VERSION "12.2.7"

NS_ :

BS_:

BU_: ACM ADAS_Body APM ASU_Gateway BCM BCM_BPM CCU_F CCU_R DUMMY_BCM_BPM ETG LDM_L LDM_R OCS_P PSM_D SRR_RR_M SHVU_F SHVU_R TRM USS_F USS_R XGW_Body

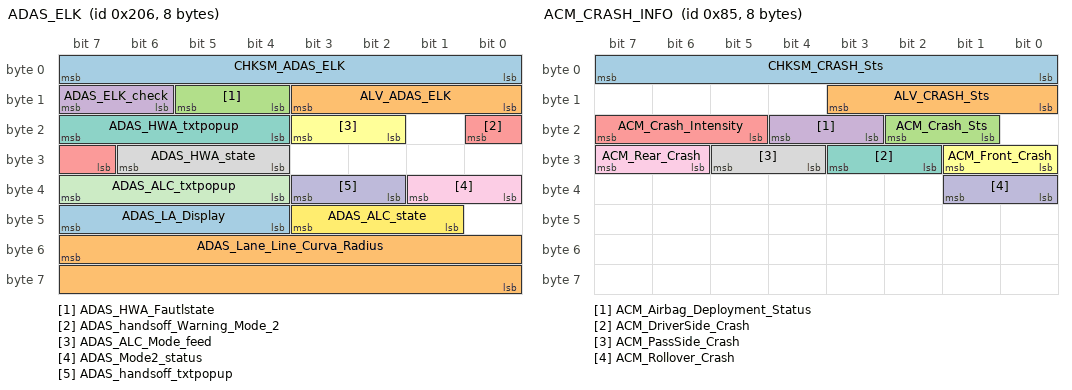
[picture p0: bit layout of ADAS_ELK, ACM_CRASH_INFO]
BO_ 518 ADAS_ELK: 8 XGW_Body
 SG_ CHKSM_ADAS_ELK : 7|8@0+ (1,0) [0|255] "" ACM
 SG_ ALV_ADAS_ELK : 11|4@0+ (1,0) [0|14] "" ACM
 SG_ ADAS_HWA_Fautlstate : 13|2@0+ (1,0) [0|3] "" Vector__XXX
 SG_ ADAS_ELK_check : 15|2@0+ (1,0) [0|3] "" ACM
 SG_ ADAS_handsoff_Warning_Mode_2 : 16|2@0+ (1,0) [0|3] "" Vector__XXX
 SG_ ADAS_ALC_Mode_feed : 19|2@0+ (1,0) [0|3] "-"  Vector__XXX
 SG_ ADAS_HWA_txtpopup : 23|4@0+ (1,0) [0|15] "" Vector__XXX
 SG_ ADAS_HWA_state : 30|3@0+ (1,0) [0|7] "" ACM
 SG_ ADAS_Mode2_status : 33|2@0+ (1,0) [0|3] "" ACM
 SG_ ADAS_handsoff_txtpopup : 35|2@0+ (1,0) [0|3] "" Vector__XXX
 SG_ ADAS_ALC_txtpopup : 39|4@0+ (1,0) [0|15] "" Vector__XXX
 SG_ ADAS_ALC_state : 43|3@0+ (1,0) [0|7] "" BCM,ACM
 SG_ ADAS_LA_Display : 47|4@0+ (1,0) [0|15] "" Vector__XXX
 SG_ ADAS_Lane_Line_Curva_Radius : 55|16@0- (1,0) [-32768|32767] "m" Vector__XXX

BO_ 133 ACM_CRASH_INFO: 8 ACM
 SG_ CHKSM_CRASH_Sts : 7|8@0+ (1,0) [0|255] ""  BCM,ETG,XGW_Body
 SG_ ALV_CRASH_Sts : 11|4@0+ (1,0) [0|14] ""  BCM,ETG,XGW_Body
 SG_ ACM_Crash_Sts : 18|2@0+ (1,0) [0|3] ""  BCM,CCU_F,ETG,XGW_Body
 SG_ ACM_Airbag_Deployment_Status : 20|2@0+ (1,0) [0|3] "-"  ETG,XGW_Body
 SG_ ACM_Crash_Intensity : 23|3@0+ (1,0) [0|7] ""  CCU_F,ETG,XGW_Body
 SG_ ACM_Front_Crash : 25|2@0+ (1,0) [0|3] "-"  BCM,ETG,XGW_Body
 SG_ ACM_DriverSide_Crash : 27|2@0+ (1,0) [0|3] ""  BCM,ETG,XGW_Body
 SG_ ACM_PassSide_Crash : 29|2@0+ (1,0) [0|3] "-"  BCM,ETG,XGW_Body
 SG_ ACM_Rear_Crash : 31|2@0+ (1,0) [0|3] "-"  BCM,ETG,XGW_Body
 SG_ ACM_Rollover_Crash : 33|2@0+ (1,0) [0|3] "-"  BCM,ETG,XGW_Body

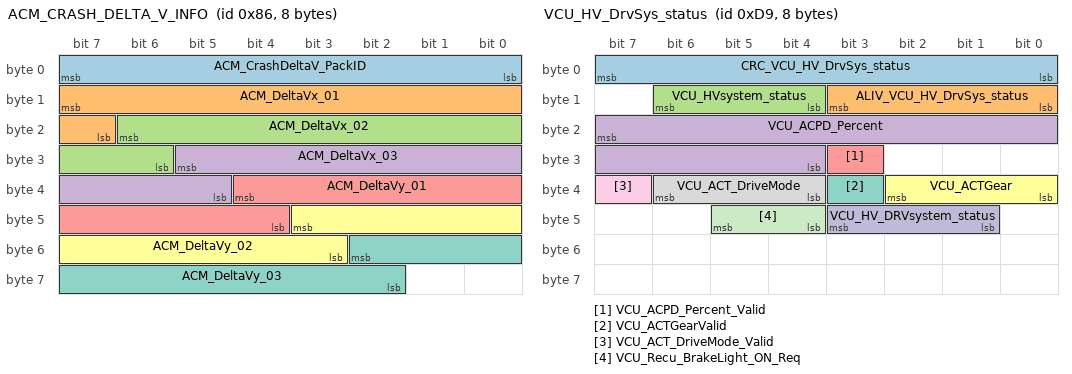
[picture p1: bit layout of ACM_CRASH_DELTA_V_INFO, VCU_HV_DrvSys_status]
BO_ 134 ACM_CRASH_DELTA_V_INFO: 8 ACM
 SG_ ACM_CrashDeltaV_PackID : 7|8@0+ (1,0) [1|9] ""  XGW_Body
 SG_ ACM_DeltaVx_01 : 15|9@0+ (1,-250) [-250|250] "Km/h"  XGW_Body
 SG_ ACM_DeltaVx_02 : 22|9@0+ (1,-250) [-250|250] "Km/h"  XGW_Body
 SG_ ACM_DeltaVx_03 : 29|9@0+ (1,-250) [-250|250] "Km/h"  XGW_Body
 SG_ ACM_DeltaVy_01 : 36|9@0+ (1,-250) [-250|250] "Km/h"  XGW_Body
 SG_ ACM_DeltaVy_02 : 43|9@0+ (1,-250) [-250|250] "Km/h"  XGW_Body
 SG_ ACM_DeltaVy_03 : 50|9@0+ (1,-250) [-250|250] "Km/h"  XGW_Body

BO_ 149 IDB_FUNCTION: 8 XGW_Body
 SG_ CHKSM_IDB_FUNCTION : 7|8@0+ (1,0) [0|255] ""  ACM,BCM
 SG_ ALV_IDB_FUNCTION : 11|4@0+ (1,0) [0|14] ""  ACM,BCM
 SG_ STAT_ABS : 13|2@0+ (1,0) [0|3] "" Vector__XXX
 SG_ ABS_Active : 15|2@0+ (1,0) [0|3] "" Vector__XXX
 SG_ AYC_Active : 17|2@0+ (1,0) [0|3] "Bit" Vector__XXX
 SG_ ASR_Active : 19|2@0+ (1,0) [0|3] "-" Vector__XXX
 SG_ STAT_DSC : 21|2@0+ (1,0) [0|3] "-"  ACM
 SG_ DSC_Active : 23|2@0+ (1,0) [0|3] "" Vector__XXX
 SG_ HBA_ActiveSignal : 25|2@0+ (1,0) [0|3] "" Vector__XXX
 SG_ ARM_ActiveSignal : 27|2@0+ (1,0) [0|3] "-" Vector__XXX
 SG_ STAT_AutoHazardBlinking : 29|2@0+ (1,0) [0|3] "Bit"  BCM
 SG_ MSR_Active : 31|2@0+ (1,0) [0|3] "-" Vector__XXX
 SG_ HSA_ActiveSignal : 33|2@0+ (1,0) [0|3] "" Vector__XXX
 SG_ EPBi_ECD_ActiveSignal : 35|2@0+ (1,0) [0|3] "" Vector__XXX
 SG_ TSM_Active : 37|2@0+ (1,0) [0|3] "-" Vector__XXX
 SG_ HAS_Available : 41|2@0+ (1,0) [0|3] "" Vector__XXX
 SG_ STAT_EBD : 43|2@0+ (1,0) [0|3] "" Vector__XXX
 SG_ EBD_Active : 45|2@0+ (1,0) [0|3] "" Vector__XXX
 SG_ ST_BRG_MSA : 55|4@0+ (1,0) [0|15] "" Vector__XXX

BO_ 217 VCU_HV_DrvSys_status: 8 XGW_Body
 SG_ CRC_VCU_HV_DrvSys_status : 7|8@0+ (1,0) [0|255] ""  ACM,BCM,LDM_L,LDM_R,SRR_RR_M,USS_F,USS_R
 SG_ ALIV_VCU_HV_DrvSys_status : 11|4@0+ (1,0) [0|14] ""  ACM,BCM,LDM_L,LDM_R,SRR_RR_M,USS_F,USS_R
 SG_ VCU_HVsystem_status : 14|3@0+ (1,0) [0|7] "-"  ACM,BCM
 SG_ VCU_ACPD_Percent : 23|12@0+ (0.0625,0) [0|100] "%"  ACM,SRR_RR_M
 SG_ VCU_ACPD_Percent_Valid : 27|1@0+ (1,0) [0|1] ""  ACM,SRR_RR_M
 SG_ VCU_ACTGear : 34|3@0+ (1,0) [0|7] ""  BCM,LDM_L,LDM_R,SRR_RR_M,USS_F,USS_R
 SG_ VCU_ACTGearValid : 35|1@0+ (1,0) [0|1] ""  BCM,LDM_L,LDM_R,SRR_RR_M
 SG_ VCU_ACT_DriveMode : 38|3@0+ (1,0) [0|7] ""  BCM
 SG_ VCU_ACT_DriveMode_Valid : 39|1@0+ (1,0) [0|1] "-"  BCM
 SG_ VCU_HV_DRVsystem_status : 43|3@0+ (1,0) [0|7] ""  BCM
 SG_ VCU_Recu_BrakeLight_ON_Req : 45|2@0+ (1,0) [0|3] "-"  BCM

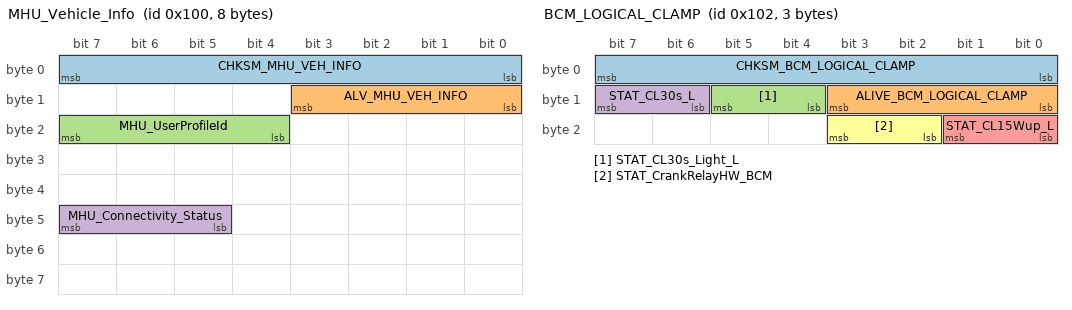
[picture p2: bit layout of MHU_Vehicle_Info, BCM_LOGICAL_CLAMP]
BO_ 256 MHU_Vehicle_Info: 8 XGW_Body
 SG_ CHKSM_MHU_VEH_INFO : 7|8@0+ (1,0) [0|255] ""  BCM
 SG_ ALV_MHU_VEH_INFO : 11|4@0+ (1,0) [0|14] ""  BCM
 SG_ MHU_UserProfileId : 23|4@0+ (1,0) [0|15] "-"  BCM
 SG_ MHU_Connectivity_Status : 47|3@0+ (1,0) [0|7] ""  BCM

BO_ 258 BCM_LOGICAL_CLAMP: 3 BCM
 SG_ CHKSM_BCM_LOGICAL_CLAMP : 7|8@0+ (1,0) [0|255] ""  ASU_Gateway,XGW_Body
 SG_ ALIVE_BCM_LOGICAL_CLAMP : 11|4@0+ (1,0) [0|14] ""  ASU_Gateway,XGW_Body
 SG_ STAT_CL30s_Light_L : 13|2@0+ (1,0) [0|3] ""  XGW_Body
 SG_ STAT_CL30s_L : 15|2@0+ (1,0) [0|3] "Bit"  ASU_Gateway,XGW_Body
 SG_ STAT_CL15Wup_L : 17|2@0+ (1,0) [0|3] "Bit"  ASU_Gateway,XGW_Body
 SG_ STAT_CrankRelayHW_BCM : 19|2@0+ (1,0) [0|3] "Bit"  XGW_Body

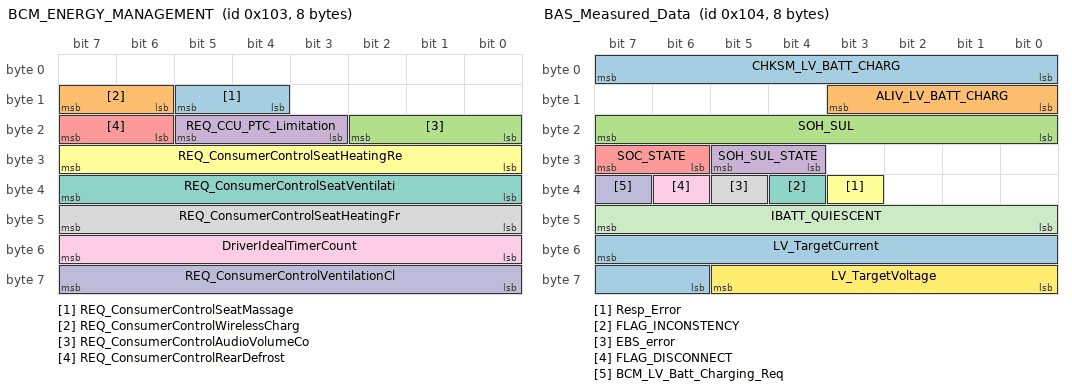
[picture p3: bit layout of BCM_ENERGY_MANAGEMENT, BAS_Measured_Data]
BO_ 259 BCM_ENERGY_MANAGEMENT: 8 BCM
 SG_ REQ_ConsumerControlSeatMassage : 13|2@0+ (1,0) [0|3] "-"  XGW_Body
 SG_ REQ_ConsumerControlWirelessCharg : 15|2@0+ (1,0) [0|3] "-"  XGW_Body
 SG_ REQ_ConsumerControlAudioVolumeCo : 18|3@0+ (1,0) [0|7] "-"  XGW_Body
 SG_ REQ_CCU_PTC_Limitation : 21|3@0+ (1,0) [0|7] ""  CCU_F,CCU_R
 SG_ REQ_ConsumerControlRearDefrost : 23|2@0+ (1,0) [0|3] "-"  CCU_F,CCU_R,XGW_Body
 SG_ REQ_ConsumerControlSeatHeatingRe : 31|8@0+ (1,0) [0|100] "%"  SHVU_F,SHVU_R,XGW_Body
 SG_ REQ_ConsumerControlSeatVentilati : 39|8@0+ (1,0) [0|100] "%"  SHVU_F,SHVU_R,XGW_Body
 SG_ REQ_ConsumerControlSeatHeatingFr : 47|8@0+ (1,0) [0|100] "%"  SHVU_F,SHVU_R,XGW_Body
 SG_ DriverIdealTimerCount : 55|8@0+ (5,0) [0|1275] "s"  XGW_Body
 SG_ REQ_ConsumerControlVentilationCl : 63|8@0+ (1,0) [0|100] "%"  CCU_F,CCU_R,SHVU_F,SHVU_R,XGW_Body

BO_ 260 BAS_Measured_Data: 8 BCM
 SG_ CHKSM_LV_BATT_CHARG : 7|8@0+ (1,0) [0|255] ""  XGW_Body
 SG_ ALIV_LV_BATT_CHARG : 11|4@0+ (1,0) [0|14] ""  XGW_Body
 SG_ SOH_SUL : 23|8@0+ (1,0) [0|100] "%"  XGW_Body
 SG_ SOH_SUL_STATE : 29|2@0+ (1,0) [0|3] ""  XGW_Body
 SG_ SOC_STATE : 31|2@0+ (1,0) [0|3] "%"  XGW_Body
 SG_ Resp_Error : 35|1@0+ (1,0) [0|1] ""  XGW_Body
 SG_ FLAG_INCONSTENCY : 36|1@0+ (1,0) [0|1] "%"  XGW_Body
 SG_ EBS_error : 37|1@0+ (1,0) [0|1] ""  XGW_Body
 SG_ FLAG_DISCONNECT : 38|1@0+ (1,0) [0|1] ""  XGW_Body
 SG_ BCM_LV_Batt_Charging_Req : 39|1@0+ (1,0) [0|1] ""  XGW_Body
 SG_ IBATT_QUIESCENT : 47|8@0+ (0.00390625,0) [0|0.984375] "" Vector__XXX
 SG_ LV_TargetVoltage : 61|6@0+ (0.112903,9) [9|16] "V"  XGW_Body
 SG_ LV_TargetCurrent : 55|10@0+ (0.25,-128) [-128|127] "A"  XGW_Body

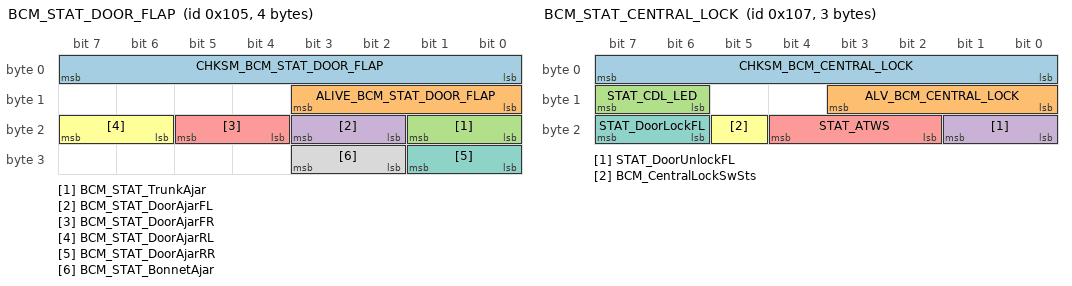
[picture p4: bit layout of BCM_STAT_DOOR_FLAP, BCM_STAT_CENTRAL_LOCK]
BO_ 261 BCM_STAT_DOOR_FLAP: 4 BCM
 SG_ CHKSM_BCM_STAT_DOOR_FLAP : 7|8@0+ (1,0) [0|255] ""  APM,ASU_Gateway,CCU_F,CCU_R,SRR_RR_M,XGW_Body
 SG_ ALIVE_BCM_STAT_DOOR_FLAP : 11|4@0+ (1,0) [0|14] ""  APM,ASU_Gateway,CCU_F,CCU_R,SRR_RR_M,XGW_Body
 SG_ BCM_STAT_TrunkAjar : 17|2@0+ (1,0) [0|3] "Bit"  APM,ASU_Gateway,CCU_R,SRR_RR_M,XGW_Body
 SG_ BCM_STAT_DoorAjarFL : 19|2@0+ (1,0) [0|3] "Bit"  APM,ASU_Gateway,CCU_F,CCU_R,SRR_RR_M,XGW_Body
 SG_ BCM_STAT_DoorAjarFR : 21|2@0+ (1,0) [0|3] "Bit"  APM,ASU_Gateway,CCU_F,CCU_R,SRR_RR_M,XGW_Body
 SG_ BCM_STAT_DoorAjarRL : 23|2@0+ (1,0) [0|3] "Bit"  APM,ASU_Gateway,CCU_F,CCU_R,SRR_RR_M,XGW_Body
 SG_ BCM_STAT_DoorAjarRR : 25|2@0+ (1,0) [0|3] "Bit"  APM,ASU_Gateway,CCU_F,CCU_R,SRR_RR_M,XGW_Body
 SG_ BCM_STAT_BonnetAjar : 27|2@0+ (1,0) [0|3] "Bit"  APM,SRR_RR_M,XGW_Body

BO_ 262 BCM_LIGHT: 8 BCM
 SG_ CHKSM_BCM_LIGHT : 7|8@0+ (1,0) [0|255] ""  APM,CCU_F,LDM_L,LDM_R,XGW_Body,SRR_RR_M
 SG_ ALIVE_BCM_LIGHT : 11|4@0+ (1,0) [0|14] ""  APM,CCU_F,LDM_L,LDM_R,XGW_Body,SRR_RR_M
 SG_ BCM_DayRunningLampSts : 13|2@0+ (1,0) [0|3] ""  LDM_L,LDM_R,XGW_Body
 SG_ BCM_ReverseLightSts : 15|2@0+ (1,0) [0|3] ""  TRM,XGW_Body
 SG_ BCM_StopLightSts : 17|2@0+ (1,0) [0|3] ""  TRM,XGW_Body
 SG_ BCM_LicensePlateLightSts : 19|2@0+ (1,0) [0|3] ""  XGW_Body
 SG_ BCM_Fr_Dimming_dome_lampSts : 21|2@0+ (1,0) [0|3] ""  XGW_Body
 SG_ BCM_Rr_Dimming_dome_lampSts : 23|2@0+ (1,0) [0|3] ""  XGW_Body
 SG_ BCM_STAT_InteriorLight : 25|2@0+ (1,0) [0|3] "Bit"  XGW_Body
 SG_ BCM_STAT_LightActivation : 28|3@0+ (1,0) [0|7] "-"  LDM_L,LDM_R,TRM,XGW_Body,SRR_RR_M
 SG_ BCM_HighBeamSts : 31|2@0+ (1,0) [0|3] ""  LDM_L,LDM_R,TRM,XGW_Body
 SG_ BCM_STAT_SwitchLightBrightness : 39|7@0+ (1,0) [0|100] "%"  XGW_Body
 SG_ BCM_LowBeamSts : 41|2@0+ (1,0) [0|3] "-"  LDM_L,LDM_R,TRM,XGW_Body
 SG_ BCM_RearFogLmpSts : 43|2@0+ (1,0) [0|3] "-"  TRM,XGW_Body
 SG_ BCM_FrntFogLmpSts : 45|2@0+ (1,0) [0|3] ""  XGW_Body
 SG_ BCM_PosLmpSts : 47|2@0+ (1,0) [0|3] "-"  LDM_L,LDM_R,TRM,XGW_Body
 SG_ BCM_BackGrdCl58Sts : 51|2@0+ (1,0) [0|3] "" Vector__XXX
 SG_ BCM_HornSts : 53|2@0+ (1,0) [0|3] ""  XGW_Body
 SG_ BCM_TurnIndicatorSts : 55|2@0+ (1,0) [0|3] ""  LDM_L,LDM_R,TRM,XGW_Body,SRR_RR_M

BO_ 263 BCM_STAT_CENTRAL_LOCK: 3 BCM
 SG_ CHKSM_BCM_CENTRAL_LOCK : 7|8@0+ (1,0) [0|255] ""  ASU_Gateway,SRR_RR_M,XGW_Body
 SG_ ALV_BCM_CENTRAL_LOCK : 11|4@0+ (1,0) [0|14] ""  ASU_Gateway,SRR_RR_M,XGW_Body
 SG_ STAT_CDL_LED : 15|2@0+ (1,0) [0|3] "-"  XGW_Body
 SG_ STAT_DoorUnlockFL : 17|2@0+ (1,0) [0|3] "Bit"  SRR_RR_M,XGW_Body
 SG_ STAT_ATWS : 20|3@0+ (1,0) [0|7] "Bit"  XGW_Body
 SG_ BCM_CentralLockSwSts : 21|1@0+ (1,0) [0|1] "" Vector__XXX
 SG_ STAT_DoorLockFL : 23|2@0+ (1,0) [0|3] "Bit"  ASU_Gateway,XGW_Body

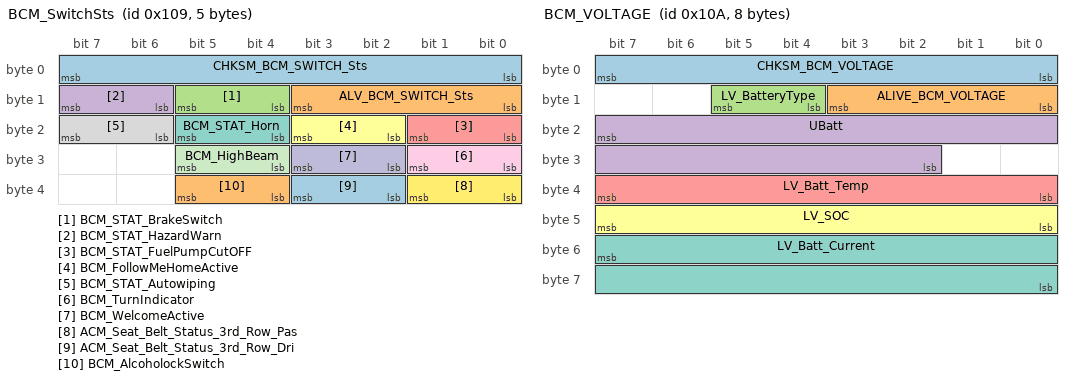
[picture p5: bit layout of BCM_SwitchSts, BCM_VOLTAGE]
BO_ 265 BCM_SwitchSts: 5 BCM
 SG_ CHKSM_BCM_SWITCH_Sts : 7|8@0+ (1,0) [0|255] ""  ACM,LDM_L,LDM_R,TRM,XGW_Body,SRR_RR_M
 SG_ ALV_BCM_SWITCH_Sts : 11|4@0+ (1,0) [0|14] ""  ACM,LDM_L,LDM_R,TRM,XGW_Body,SRR_RR_M
 SG_ BCM_STAT_BrakeSwitch : 13|2@0+ (1,0) [0|3] ""  ACM,TRM,XGW_Body,SRR_RR_M
 SG_ BCM_STAT_HazardWarn : 15|2@0+ (1,0) [0|3] "-"  LDM_L,LDM_R,TRM,XGW_Body,SRR_RR_M
 SG_ BCM_STAT_FuelPumpCutOFF : 17|2@0+ (1,0) [0|3] ""  XGW_Body
 SG_ BCM_FollowMeHomeActive : 19|2@0+ (1,0) [0|3] ""  TRM,XGW_Body
 SG_ BCM_STAT_Horn : 21|2@0+ (1,0) [0|3] "-"  XGW_Body
 SG_ BCM_STAT_Autowiping : 23|2@0+ (1,0) [0|3] ""  XGW_Body
 SG_ BCM_TurnIndicator : 25|2@0+ (1,0) [0|3] ""  LDM_L,LDM_R,TRM,XGW_Body,SRR_RR_M
 SG_ BCM_WelcomeActive : 27|2@0+ (1,0) [0|3] "-"  TRM,XGW_Body
 SG_ BCM_HighBeam : 29|2@0+ (1,0) [0|3] ""  LDM_L,LDM_R,TRM,XGW_Body,SRR_RR_M
 SG_ ACM_Seat_Belt_Status_3rd_Row_Pas : 33|2@0+ (1,0) [0|3] ""  XGW_Body
 SG_ ACM_Seat_Belt_Status_3rd_Row_Dri : 35|2@0+ (1,0) [0|3] "-"  XGW_Body
 SG_ BCM_AlcoholockSwitch : 37|2@0+ (1,0) [0|3] "" Vector__XXX

BO_ 266 BCM_VOLTAGE: 8 BCM
 SG_ CHKSM_BCM_VOLTAGE : 7|8@0+ (1,0) [0|255] ""  ACM,APM,ASU_Gateway,BCM_BPM,CCU_F,CCU_R,ETG,LDM_L,LDM_R,OCS_P,PSM_D,SHVU_F,SHVU_R,SRR_RR_M,TRM,USS_F,USS_R,XGW_Body
 SG_ ALIVE_BCM_VOLTAGE : 11|4@0+ (1,0) [0|14] ""  ACM,APM,ASU_Gateway,BCM_BPM,CCU_F,CCU_R,ETG,LDM_L,LDM_R,OCS_P,PSM_D,SHVU_F,SHVU_R,SRR_RR_M,TRM,USS_F,USS_R,XGW_Body
 SG_ LV_BatteryType : 13|2@0+ (1,0) [0|3] "Number"  XGW_Body
 SG_ UBatt : 23|14@0+ (0.0009777,3) [3|18] "V"  ACM,APM,ASU_Gateway,BCM_BPM,CCU_F,CCU_R,ETG,LDM_L,LDM_R,OCS_P,PSM_D,SHVU_F,SHVU_R,SRR_RR_M,TRM,XGW_Body,USS_F,USS_R
 SG_ LV_Batt_Temp : 39|8@0+ (1,-40) [-40|105] "Degree C"  ACM,APM,ASU_Gateway,BCM_BPM,CCU_F,CCU_R,ETG,LDM_L,LDM_R,OCS_P,PSM_D,SHVU_F,SHVU_R,TRM,XGW_Body
 SG_ LV_SOC : 47|8@0+ (1,0) [0|100] "%"  ACM,APM,ASU_Gateway,BCM_BPM,CCU_F,CCU_R,ETG,LDM_L,LDM_R,OCS_P,PSM_D,SHVU_F,SHVU_R,TRM,XGW_Body
 SG_ LV_Batt_Current : 55|16@0+ (0.03125,-1536) [-1536|511.90625] "A"  ACM,APM,ASU_Gateway,BCM_BPM,CCU_F,CCU_R,ETG,LDM_L,LDM_R,OCS_P,PSM_D,SHVU_F,SHVU_R,TRM,XGW_Body

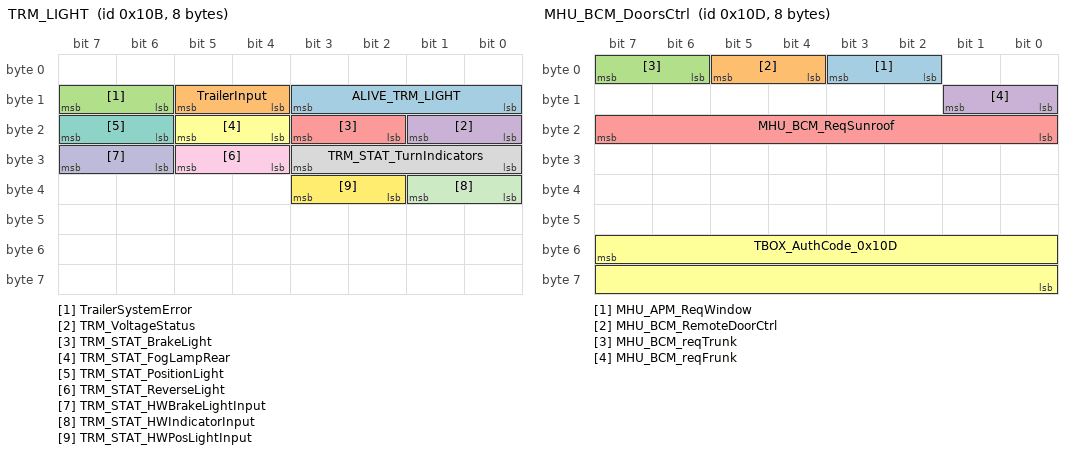
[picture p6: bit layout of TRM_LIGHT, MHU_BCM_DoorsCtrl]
BO_ 267 TRM_LIGHT: 8 TRM
 SG_ ALIVE_TRM_LIGHT : 11|4@0+ (1,0) [0|14] ""  BCM,XGW_Body
 SG_ TrailerInput : 13|2@0+ (1,0) [0|3] ""  BCM,XGW_Body
 SG_ TrailerSystemError : 15|2@0+ (1,0) [0|3] ""  BCM,XGW_Body
 SG_ TRM_VoltageStatus : 17|2@0+ (1,0) [0|3] ""  BCM,XGW_Body
 SG_ TRM_STAT_BrakeLight : 19|2@0+ (1,0) [0|3] ""  BCM,XGW_Body
 SG_ TRM_STAT_FogLampRear : 21|2@0+ (1,0) [0|3] ""  BCM,XGW_Body
 SG_ TRM_STAT_PositionLight : 23|2@0+ (1,0) [0|3] ""  BCM,XGW_Body
 SG_ TRM_STAT_TurnIndicators : 27|4@0+ (1,0) [0|15] ""  BCM,XGW_Body
 SG_ TRM_STAT_ReverseLight : 29|2@0+ (1,0) [0|3] ""  BCM,XGW_Body
 SG_ TRM_STAT_HWBrakeLightInput : 31|2@0+ (1,0) [0|3] ""  BCM,XGW_Body
 SG_ TRM_STAT_HWIndicatorInput : 33|2@0+ (1,0) [0|3] ""  BCM,XGW_Body
 SG_ TRM_STAT_HWPosLightInput : 35|2@0+ (1,0) [0|3] ""  BCM,XGW_Body

BO_ 268 BCM_RemoteCtrlSts: 8 BCM
 SG_ Checksum_0x10C : 7|8@0+ (1,0) [0|255] ""  XGW_Body
 SG_ Rolling_Counter_0x10C : 11|4@0+ (1,0) [0|14] ""  XGW_Body
 SG_ BCM_TboxAuthStatus : 23|2@0+ (1,0) [0|3] "-"  XGW_Body
 SG_ BCM_RandomNum32bit : 31|32@0+ (1,0) [0|4294967295] "-"  XGW_Body

BO_ 269 MHU_BCM_DoorsCtrl: 8 XGW_Body
 SG_ MHU_APM_ReqWindow : 3|2@0+ (1,0) [0|3] "-"  BCM
 SG_ MHU_BCM_RemoteDoorCtrl : 5|2@0+ (1,0) [0|3] "-"  BCM
 SG_ MHU_BCM_reqTrunk : 7|2@0+ (1,0) [0|3] "-"  BCM
 SG_ MHU_BCM_reqFrunk : 9|2@0+ (1,0) [0|3] "-"  BCM
 SG_ MHU_BCM_ReqSunroof : 23|8@0+ (1,0) [0|255] "%"  BCM
 SG_ TBOX_AuthCode_0x10D : 55|16@0+ (1,0) [0|65535] "-"  BCM

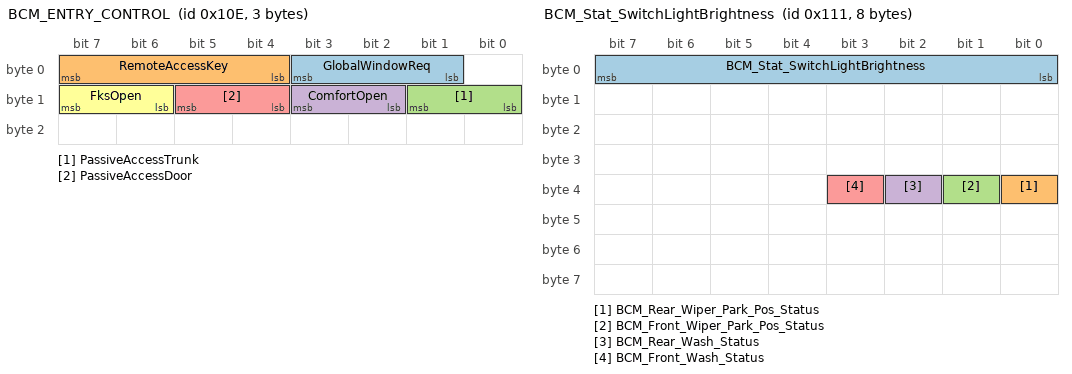
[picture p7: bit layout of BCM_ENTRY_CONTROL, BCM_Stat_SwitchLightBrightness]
BO_ 270 BCM_ENTRY_CONTROL: 3 BCM
 SG_ GlobalWindowReq : 3|3@0+ (1,0) [0|7] ""  APM
 SG_ RemoteAccessKey : 7|4@0+ (1,0) [0|15] "-"  APM,ETG,XGW_Body
 SG_ PassiveAccessTrunk : 9|2@0+ (1,0) [0|3] "-"  ETG,XGW_Body
 SG_ ComfortOpen : 11|2@0+ (1,0) [0|3] "-"  ETG,XGW_Body
 SG_ PassiveAccessDoor : 13|2@0+ (1,0) [0|3] "-"  APM,ETG,XGW_Body
 SG_ FksOpen : 15|2@0+ (1,0) [0|3] ""  ETG,XGW_Body

BO_ 271 MHU_BCM_HornLightControl: 8 XGW_Body
 SG_ MHU_SetHornOnOff : 3|2@0+ (1,0) [0|3] "-"  BCM
 SG_ MHU_SetLowBeam : 5|2@0+ (1,0) [0|3] ""  BCM
 SG_ MHU_SetHighBeam : 7|2@0+ (1,0) [0|3] ""  BCM
 SG_ TBOX_AuthCode_0x10F : 55|16@0+ (1,0) [0|65535] "-"  BCM

BO_ 273 BCM_Stat_SwitchLightBrightness: 8 BCM
 SG_ BCM_Stat_SwitchLightBrightness : 7|8@0+ (0.4,0) [0|102] ""  XGW_Body
 SG_ BCM_Rear_Wiper_Park_Pos_Status : 32|1@0+ (1,0) [0|1] "" Vector__XXX
 SG_ BCM_Front_Wiper_Park_Pos_Status : 33|1@0+ (1,0) [0|1] "" Vector__XXX
 SG_ BCM_Rear_Wash_Status : 34|1@0+ (1,0) [0|1] "" Vector__XXX
 SG_ BCM_Front_Wash_Status : 35|1@0+ (1,0) [0|1] "" Vector__XXX

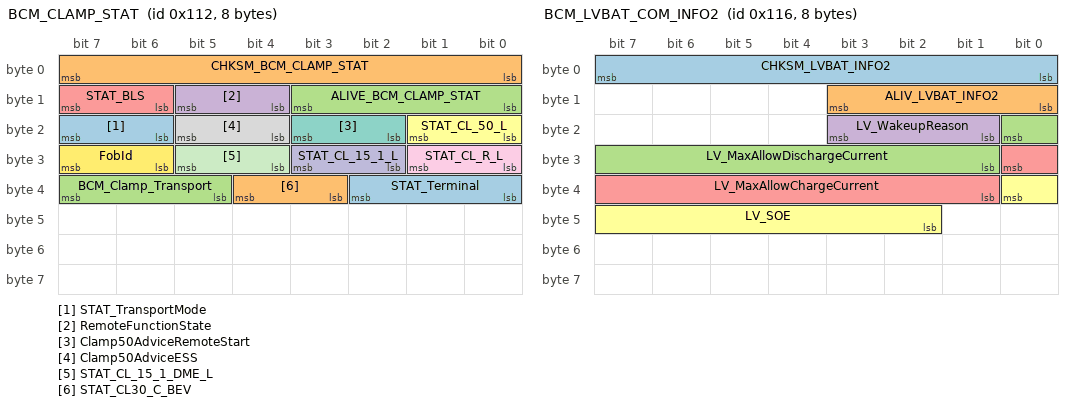
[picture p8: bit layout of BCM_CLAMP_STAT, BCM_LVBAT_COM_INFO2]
BO_ 274 BCM_CLAMP_STAT: 8 BCM
 SG_ STAT_TransportMode : 23|2@0+ (1,0) [0|3] ""  XGW_Body
 SG_ CHKSM_BCM_CLAMP_STAT : 7|8@0+ (1,0) [0|255] ""  ACM,APM,ASU_Gateway,BCM_BPM,CCU_F,CCU_R,ETG,LDM_L,LDM_R,OCS_P,PSM_D,SHVU_F,SHVU_R,SRR_RR_M,TRM,USS_F,USS_R,XGW_Body
 SG_ ALIVE_BCM_CLAMP_STAT : 11|4@0+ (1,0) [0|14] ""  ACM,APM,ASU_Gateway,BCM_BPM,CCU_F,CCU_R,ETG,LDM_L,LDM_R,OCS_P,PSM_D,SHVU_F,SHVU_R,SRR_RR_M,TRM,USS_F,USS_R,XGW_Body
 SG_ RemoteFunctionState : 13|2@0+ (1,0) [0|3] ""  ACM,APM,ASU_Gateway,BCM_BPM,CCU_F,CCU_R,ETG,LDM_L,LDM_R,OCS_P,PSM_D,SHVU_F,SHVU_R,TRM,XGW_Body
 SG_ STAT_BLS : 15|2@0+ (1,0) [0|3] "-"  ACM,APM,ASU_Gateway,BCM_BPM,CCU_F,CCU_R,ETG,LDM_L,LDM_R,OCS_P,PSM_D,SHVU_F,SHVU_R,TRM,XGW_Body
 SG_ STAT_CL_50_L : 17|2@0+ (1,0) [0|3] ""  ACM,APM,ASU_Gateway,BCM_BPM,CCU_F,CCU_R,ETG,LDM_L,LDM_R,OCS_P,PSM_D,SHVU_F,SHVU_R,TRM,XGW_Body
 SG_ Clamp50AdviceRemoteStart : 19|2@0+ (1,0) [0|3] "-"  ACM,APM,ASU_Gateway,BCM_BPM,CCU_F,CCU_R,ETG,LDM_L,LDM_R,OCS_P,PSM_D,SHVU_F,SHVU_R,TRM,XGW_Body
 SG_ Clamp50AdviceESS : 21|2@0+ (1,0) [0|3] "-"  ACM,APM,ASU_Gateway,BCM_BPM,CCU_F,CCU_R,ETG,LDM_L,LDM_R,OCS_P,PSM_D,SHVU_F,SHVU_R,TRM,XGW_Body
 SG_ STAT_CL_R_L : 25|2@0+ (1,0) [0|3] ""  ACM,APM,ASU_Gateway,BCM_BPM,CCU_F,CCU_R,ETG,LDM_L,LDM_R,OCS_P,PSM_D,SHVU_F,SHVU_R,TRM,XGW_Body
 SG_ STAT_CL_15_1_L : 27|2@0+ (1,0) [0|3] "-"  ACM,APM,ASU_Gateway,BCM_BPM,CCU_F,CCU_R,ETG,LDM_L,LDM_R,OCS_P,PSM_D,SHVU_F,SHVU_R,TRM,XGW_Body
 SG_ STAT_CL_15_1_DME_L : 29|2@0+ (1,0) [0|3] ""  ACM,APM,ASU_Gateway,BCM_BPM,CCU_F,CCU_R,ETG,LDM_L,LDM_R,OCS_P,PSM_D,SHVU_F,SHVU_R,TRM,XGW_Body
 SG_ FobId : 31|2@0+ (1,0) [0|3] "Bit"  ACM,APM,ASU_Gateway,BCM_BPM,CCU_F,CCU_R,ETG,LDM_L,LDM_R,OCS_P,PSM_D,SHVU_F,SHVU_R,TRM,XGW_Body
 SG_ STAT_Terminal : 34|3@0+ (1,0) [0|7] "Bit"  ACM,APM,ASU_Gateway,BCM_BPM,CCU_F,CCU_R,ETG,LDM_L,LDM_R,OCS_P,PSM_D,SHVU_F,SHVU_R,SRR_RR_M,TRM,XGW_Body,USS_F,USS_R
 SG_ STAT_CL30_C_BEV : 36|2@0+ (1,0) [0|3] "Bit"  ACM,APM,ASU_Gateway,BCM_BPM,CCU_F,CCU_R,ETG,LDM_L,LDM_R,OCS_P,PSM_D,SHVU_F,SHVU_R,TRM,XGW_Body
 SG_ BCM_Clamp_Transport : 39|3@0+ (1,0) [0|7] ""  ACM,APM,ASU_Gateway,BCM_BPM,CCU_F,CCU_R,ETG,LDM_L,LDM_R,OCS_P,PSM_D,SHVU_F,SHVU_R,TRM,XGW_Body

BO_ 276 BCM_LVBAT_Data: 8 BCM
 SG_ CHKSM_LVBAT_DATA : 7|8@0+ (1,0) [0|255] ""  XGW_Body
 SG_ ALIV_LVBAT_DATA : 11|4@0+ (1,0) [0|14] ""  XGW_Body
 SG_ LV_ErrorSts : 14|3@0+ (1,0) [0|7] ""  XGW_Body
 SG_ LV_MinCellVolt : 23|8@0+ (0.015625,1) [1|5] "V"  XGW_Body
 SG_ LV_MaxCellVolt : 31|8@0+ (0.015625,1) [1|5] "V"  XGW_Body
 SG_ LV_MinCellTemp : 39|8@0+ (1,-40) [-40|215] "Degree C"  XGW_Body
 SG_ LV_MaxCellTemp : 47|8@0+ (1,-40) [-40|215] "Degree C"  XGW_Body
 SG_ LV_Discharger_Err : 48|1@0+ (1,0) [0|1] ""  XGW_Body
 SG_ LV_Discharger_Sts : 49|1@0+ (1,0) [0|1] ""  XGW_Body
 SG_ LV_Charger_Err : 50|1@0+ (1,0) [0|1] ""  XGW_Body
 SG_ LV_Charger_Sts : 51|1@0+ (1,0) [0|1] ""  XGW_Body
 SG_ LV_OverVoltage : 52|1@0+ (1,0) [0|1] ""  XGW_Body
 SG_ LV_UnderVoltage : 53|1@0+ (1,0) [0|1] ""  XGW_Body
 SG_ LV_OverCurrent : 54|1@0+ (1,0) [0|1] ""  XGW_Body
 SG_ LV_UnderTemp : 55|1@0+ (1,0) [0|1] ""  XGW_Body
 SG_ LV_OverTemp : 56|1@0+ (1,0) [0|1] ""  XGW_Body
 SG_ LV_OverCharge : 57|1@0+ (1,0) [0|1] ""  XGW_Body
 SG_ LV_OverDischarge : 58|1@0+ (1,0) [0|1] ""  XGW_Body
 SG_ LV_CellBalance_Sts : 59|1@0+ (1,0) [0|1] ""  XGW_Body
 SG_ LV_CellBalance_Error : 60|1@0+ (1,0) [0|1] ""  XGW_Body
 SG_ LV_ThermalRunaway : 61|1@0+ (1,0) [0|1] ""  XGW_Body
 SG_ LV_WarmupRequest : 63|2@0+ (1,0) [0|3] ""  XGW_Body

BO_ 277 BCM_Childlock: 8 BCM
 SG_ BCM_ChildLock_Feedback : 7|2@0+ (1,0) [0|3] ""  XGW_Body

BO_ 278 BCM_LVBAT_COM_INFO2: 8 BCM
 SG_ CHKSM_LVBAT_INFO2 : 7|8@0+ (1,0) [0|255] ""  XGW_Body
 SG_ ALIV_LVBAT_INFO2 : 11|4@0+ (1,0) [0|14] ""  XGW_Body
 SG_ LV_MaxAllowDischargeCurrent : 16|8@0+ (1,0) [0|253] "A"  XGW_Body
 SG_ LV_WakeupReason : 19|3@0+ (1,0) [0|7] "" XGW_Body
 SG_ LV_MaxAllowChargeCurrent : 24|8@0+ (1,0) [0|253] "A"  XGW_Body
 SG_ LV_SOE : 32|7@0+ (1,0) [0|100] "%"  XGW_Body

BO_ 280 BCM_MHU_Ctrl_Fbk: 8 BCM
 SG_ CHKSM_BCM_MHU_Ctrl_Fbk : 7|8@0+ (1,0) [0|255] ""  XGW_Body
 SG_ ALV_BCM_MHU_Ctrl_Fbk : 11|4@0+ (1,0) [0|14] ""  XGW_Body
 SG_ BCM_DrvInhibitStsFbk : 13|2@0+ (1,0) [0|3] ""  XGW_Body

BO_ 282 MHU_ServiceMode_Setting: 8 XGW_Body
 SG_ MHU_SET_WiperServicePositionMod : 5|2@0+ (1,0) [0|3] ""  BCM
 SG_ MHU_Read_KeyFobOnCenterConsole : 7|2@0+ (1,0) [0|3] ""  BCM

BO_ 283 MHU_BCM_RemoteClampCtrl: 8 XGW_Body
 SG_ TBOX_STAT_TerminalReq : 7|3@0+ (1,0) [0|7] "-"  BCM
 SG_ TBOX_AuthCode_0x11B : 55|16@0+ (1,0) [0|65535] ""  BCM

BO_ 284 MHU_BCM_FOTAClampCtrl: 8 XGW_Body
 SG_ TBOX_FOTA_STAT_TerminalReq : 7|3@0+ (1,0) [0|7] "-"  BCM

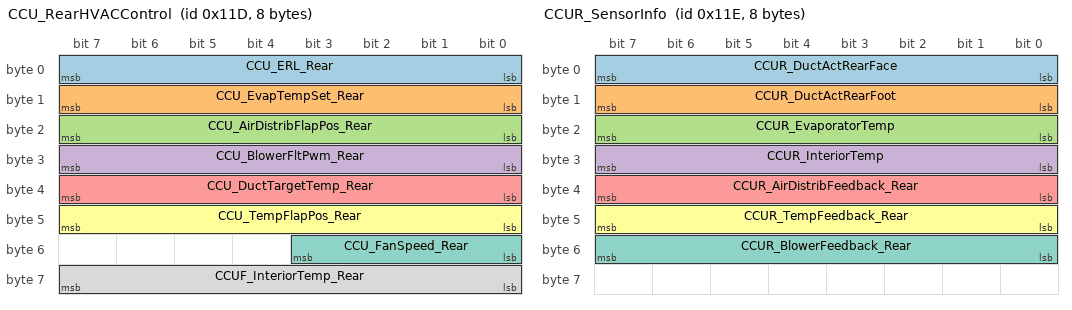
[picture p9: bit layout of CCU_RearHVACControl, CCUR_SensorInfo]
BO_ 285 CCU_RearHVACControl: 8 CCU_F
 SG_ CCU_ERL_Rear : 7|8@0+ (1,0) [0|255] ""  CCU_R
 SG_ CCU_EvapTempSet_Rear : 15|8@0+ (0.1,-5) [-5|20.5] "Degree C"  CCU_R
 SG_ CCU_AirDistribFlapPos_Rear : 23|8@0+ (0.5,0) [0|100] "%"  CCU_R
 SG_ CCU_BlowerFltPwm_Rear : 31|8@0+ (0.5,0) [0|100] "%"  CCU_R
 SG_ CCU_DuctTargetTemp_Rear : 39|8@0+ (0.5,-40) [-40|85] "Degree C"  CCU_R
 SG_ CCU_TempFlapPos_Rear : 47|8@0+ (0.5,0) [0|100] "%"  CCU_R
 SG_ CCU_FanSpeed_Rear : 51|4@0+ (1,0) [0|15] "%"  CCU_R
 SG_ CCUF_InteriorTemp_Rear : 63|8@0+ (0.5,-40) [-40|85] "Degree C" Vector__XXX

BO_ 286 CCUR_SensorInfo: 8 CCU_R
 SG_ CCUR_DuctActRearFace : 7|8@0+ (0.5,-40) [-40|85] "Degree C"  CCU_F
 SG_ CCUR_DuctActRearFoot : 15|8@0+ (0.5,-40) [-40|85] "Degree C"  CCU_F
 SG_ CCUR_EvaporatorTemp : 23|8@0+ (0.5,-40) [-40|85] "Degree C"  CCU_F
 SG_ CCUR_InteriorTemp : 31|8@0+ (0.5,-40) [-40|85] "Degree C"  CCU_F
 SG_ CCUR_AirDistribFeedback_Rear : 39|8@0+ (0.5,0) [0|5] "V"  CCU_F
 SG_ CCUR_TempFeedback_Rear : 47|8@0+ (0.5,0) [0|5] "V"  CCU_F
 SG_ CCUR_BlowerFeedback_Rear : 55|8@0+ (0.5,0) [0|5] "V"  CCU_F

BO_ 287 MHU_BCM_Ctrl: 8 XGW_Body
 SG_ MHU_DrvInhibitSts : 13|2@0+ (1,0) [0|3] ""  BCM
 SG_ TBOX_AuthCode_0x11F : 55|16@0+ (1,0) [0|65535] ""  BCM

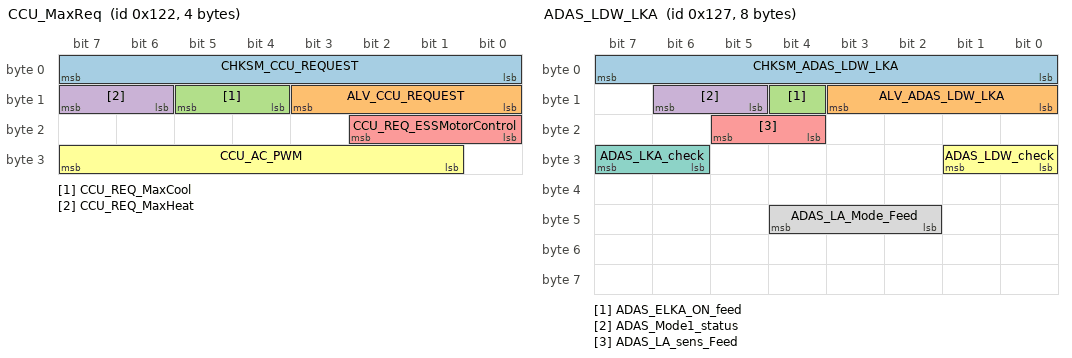
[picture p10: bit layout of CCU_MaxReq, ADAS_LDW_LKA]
BO_ 290 CCU_MaxReq: 4 CCU_F
 SG_ CHKSM_CCU_REQUEST : 7|8@0+ (1,0) [0|255] ""  XGW_Body
 SG_ ALV_CCU_REQUEST : 11|4@0+ (1,0) [0|14] ""  XGW_Body
 SG_ CCU_REQ_MaxCool : 13|2@0+ (1,0) [0|3] ""  XGW_Body
 SG_ CCU_REQ_MaxHeat : 15|2@0+ (1,0) [0|3] ""  XGW_Body
 SG_ CCU_REQ_ESSMotorControl : 18|3@0+ (1,0) [0|7] "Bit"  XGW_Body
 SG_ CCU_AC_PWM : 31|7@0+ (1,0) [0|100] "%"  XGW_Body

BO_ 295 ADAS_LDW_LKA: 8 XGW_Body
  SG_ CHKSM_ADAS_LDW_LKA : 7|8@0+ (1,0) [0|255] "" ACM
  SG_ ALV_ADAS_LDW_LKA : 11|4@0+ (1,0) [0|14] "" ACM
  SG_ ADAS_ELKA_ON_feed : 12|1@0+ (1,0) [0|1] ""  ACM
  SG_ ADAS_Mode1_status : 14|2@0+ (1,0) [0|3] "-" ACM
  SG_ ADAS_LA_sens_Feed : 21|2@0+ (1,0) [0|3] "-" ACM
  SG_ ADAS_LDW_check : 25|2@0+ (1,0) [0|3] "-" ACM
  SG_ ADAS_LKA_check : 31|2@0+ (1,0) [0|3] "-" ACM
  SG_ ADAS_LA_Mode_Feed : 44|3@0+ (1,0) [0|7] "-" ACM

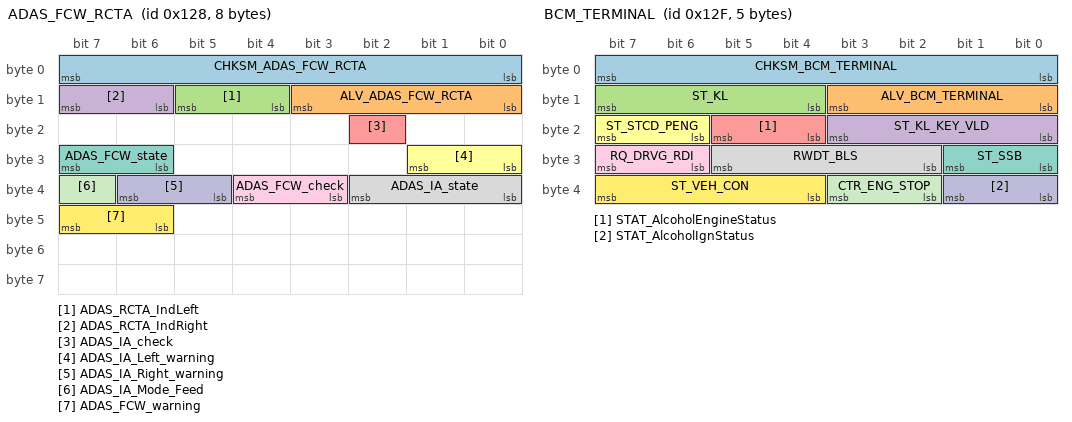
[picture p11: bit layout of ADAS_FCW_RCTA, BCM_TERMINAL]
BO_ 296 ADAS_FCW_RCTA: 8 XGW_Body
  SG_ CHKSM_ADAS_FCW_RCTA : 7|8@0+ (1,0) [0|255] "" ACM
  SG_ ALV_ADAS_FCW_RCTA : 11|4@0+ (1,0) [0|14] "" ACM
  SG_ ADAS_RCTA_IndLeft : 13|2@0+ (1,0) [0|3] "-" BCM
  SG_ ADAS_RCTA_IndRight : 15|2@0+ (1,0) [0|3] "-" BCM
  SG_ ADAS_IA_check : 18|1@0+ (1,0) [0|1] "-" ACM
  SG_ ADAS_IA_Left_warning : 25|2@0+ (1,0) [0|3] "-" ACM
  SG_ ADAS_FCW_state : 31|2@0+ (1,0) [0|3] "-" ACM
  SG_ ADAS_IA_state : 34|3@0+ (1,0) [0|7] "-" ACM
  SG_ ADAS_FCW_check : 36|2@0+ (1,0) [0|3] "-" ACM
  SG_ ADAS_IA_Right_warning : 38|2@0+ (1,0) [0|3] "-" ACM
  SG_ ADAS_IA_Mode_Feed : 39|1@0+ (1,0) [0|1] "-" ACM
  SG_ ADAS_FCW_warning : 47|2@0+ (1,0) [0|3] "-" ACM

BO_ 303 BCM_TERMINAL: 5 BCM
 SG_ CHKSM_BCM_TERMINAL : 7|8@0+ (1,0) [0|255] ""  XGW_Body
 SG_ ALV_BCM_TERMINAL : 11|4@0+ (1,0) [0|14] ""  XGW_Body
 SG_ ST_KL : 15|4@0+ (1,0) [0|15] "-"  XGW_Body
 SG_ ST_KL_KEY_VLD : 19|4@0+ (1,0) [0|15] ""  XGW_Body
 SG_ STAT_AlcoholEngineStatus : 21|2@0+ (1,0) [0|3] "" XGW_Body
 SG_ ST_STCD_PENG : 23|2@0+ (1,0) [0|3] ""  XGW_Body
 SG_ ST_SSB : 25|2@0+ (1,0) [0|3] "-"  XGW_Body
 SG_ RWDT_BLS : 29|4@0+ (1,0) [0|15] "-"  XGW_Body
 SG_ RQ_DRVG_RDI : 31|2@0+ (1,0) [0|3] ""  XGW_Body
 SG_ STAT_AlcoholIgnStatus : 33|2@0+ (1,0) [0|3] "" XGW_Body
 SG_ CTR_ENG_STOP : 35|2@0+ (1,0) [0|3] "Bit"  XGW_Body
 SG_ ST_VEH_CON : 39|4@0+ (1,0) [0|15] "-"  XGW_Body

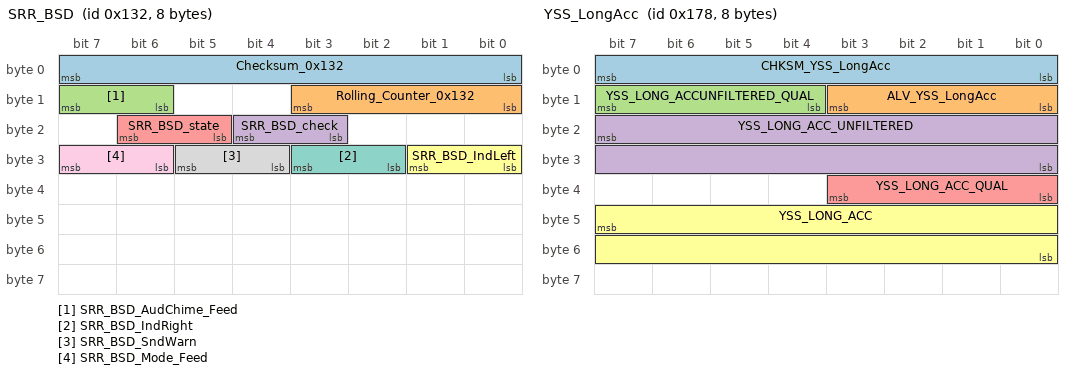
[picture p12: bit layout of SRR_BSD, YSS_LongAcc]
BO_ 306 SRR_BSD: 8 SRR_RR_M
 SG_ Checksum_0x132 : 7|8@0+ (1,0) [0|255] ""  BCM,XGW_Body
 SG_ Rolling_Counter_0x132 : 11|4@0+ (1,0) [0|15] ""  BCM,XGW_Body
 SG_ SRR_BSD_AudChime_Feed : 15|2@0+ (1,0) [0|3] "-"  BCM,XGW_Body
 SG_ SRR_BSD_check : 20|2@0+ (1,0) [0|3] "-"  BCM,XGW_Body
 SG_ SRR_BSD_state : 22|2@0+ (1,0) [0|3] ""  BCM,XGW_Body
 SG_ SRR_BSD_IndLeft : 25|2@0+ (1,0) [0|3] "" BCM,XGW_Body
 SG_ SRR_BSD_IndRight : 27|2@0+ (1,0) [0|3] ""  BCM,XGW_Body
 SG_ SRR_BSD_SndWarn : 29|2@0+ (1,0) [0|3] "-"  BCM,XGW_Body
 SG_ SRR_BSD_Mode_Feed : 31|2@0+ (1,0) [0|3] "-"  BCM,XGW_Body

BO_ 307 ADAS_BSD: 8 XGW_Body
 SG_ ADAS_BSD_IndLeft : 25|2@0+ (1,0) [0|3] ""  BCM
 SG_ ADAS_BSD_IndRight : 27|2@0+ (1,0) [0|3] ""  BCM

BO_ 314 FCAM_ESA_Sts: 8 XGW_Body
 SG_ FCAM_ESA_Sts : 14|3@0+ (1,0) [0|7] ""  ACM

BO_ 359 VCU_TWV1_Frm: 8 XGW_Body
 SG_ TWV1_N_Position : 7|16@0+ (0.1,0) [0|100] "%"  CCU_F
 SG_ TWV1_St_Feedback : 23|16@0+ (1,0) [0|15] ""  CCU_F
 SG_ TWV1_Frm_Error : 39|1@0+ (1,0) [0|1] ""  CCU_F

BO_ 360 MHU_FEEDBACK_APA: 8 XGW_Body
 SG_ Checksum_MHU_FEEDBACK_APA : 7|8@0+ (1,0) [0|255] "" USS_F,USS_R
 SG_ Rolling_Counter_MHU_FEEDBACK_APA : 11|4@0+ (1,0) [0|14] "" USS_F,USS_R
 SG_ MHU_AVM_ShowAVMReq : 22|2@0+ (1,0) [0|3] "-" USS_F,USS_R

BO_ 376 YSS_LongAcc: 8 XGW_Body
 SG_ CHKSM_YSS_LongAcc : 7|8@0+ (1,0) [0|255] ""  ASU_Gateway
 SG_ ALV_YSS_LongAcc : 11|4@0+ (1,0) [0|14] ""  ASU_Gateway
 SG_ YSS_LONG_ACCUNFILTERED_QUAL : 15|4@0+ (1,0) [0|15] ""  ASU_Gateway
 SG_ YSS_LONG_ACC_UNFILTERED : 23|16@0+ (0.002,-65.532) [-65.532|65.532] "m/s2"  ASU_Gateway
 SG_ YSS_LONG_ACC_QUAL : 35|4@0+ (1,0) [0|15] ""  ASU_Gateway
 SG_ YSS_LONG_ACC : 47|16@0+ (0.002,-65.532) [-65.532|65.532] "m/s2"  ASU_Gateway

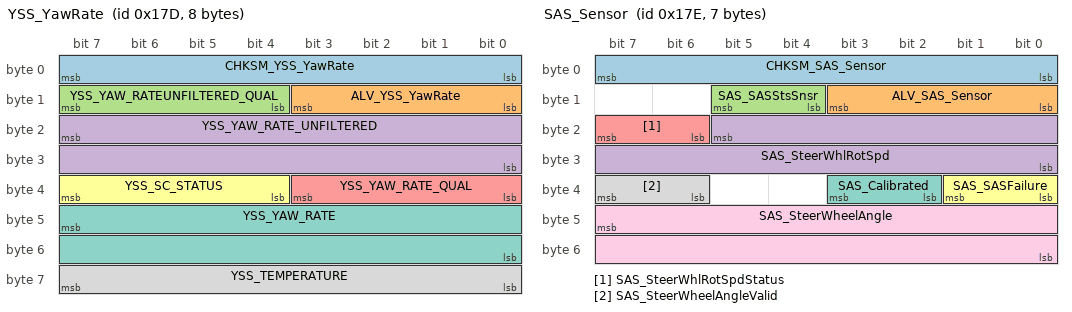
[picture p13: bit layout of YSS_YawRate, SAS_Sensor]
BO_ 381 YSS_YawRate: 8 XGW_Body
 SG_ CHKSM_YSS_YawRate : 7|8@0+ (1,0) [0|255] ""  ASU_Gateway,ACM
 SG_ ALV_YSS_YawRate : 11|4@0+ (1,0) [0|14] ""  ASU_Gateway,ACM
 SG_ YSS_YAW_RATEUNFILTERED_QUAL : 15|4@0+ (1,0) [0|15] ""  ASU_Gateway,ACM
 SG_ YSS_YAW_RATE_UNFILTERED : 23|16@0+ (0.005,-163.83) [-163.83|163.83] "�/s"  ASU_Gateway,ACM
 SG_ YSS_YAW_RATE_QUAL : 35|4@0+ (1,0) [0|15] ""  ASU_Gateway,ACM
 SG_ YSS_SC_STATUS : 39|4@0+ (1,0) [0|15] ""  ASU_Gateway,ACM
 SG_ YSS_YAW_RATE : 47|16@0+ (0.005,-163.83) [-163.83|163.83] "�/s"  ASU_Gateway,ACM
 SG_ YSS_TEMPERATURE : 63|8@0+ (1,-40) [-40|115] "�C"  ASU_Gateway,ACM

BO_ 382 SAS_Sensor: 7 XGW_Body
 SG_ CHKSM_SAS_Sensor : 7|8@0+ (1,0) [0|255] ""  ACM,BCM,LDM_L,LDM_R,SRR_RR_M
 SG_ ALV_SAS_Sensor : 11|4@0+ (1,0) [0|14] ""  ACM,BCM,LDM_L,LDM_R,SRR_RR_M
 SG_ SAS_SASStsSnsr : 13|2@0+ (1,0) [0|1] "-"  ACM,LDM_L,LDM_R,SRR_RR_M
 SG_ SAS_SteerWhlRotSpd : 21|14@0+ (0.125,-1024) [-1024|1023.875] "degree/s"  LDM_L,LDM_R,SRR_RR_M
 SG_ SAS_SteerWhlRotSpdStatus : 23|2@0+ (1,0) [0|1] ""  LDM_L,LDM_R,SRR_RR_M
 SG_ SAS_SASFailure : 33|2@0+ (1,0) [0|1] ""  ACM,LDM_L,LDM_R,SRR_RR_M
 SG_ SAS_Calibrated : 35|2@0+ (1,0) [0|1] ""  ACM,LDM_L,LDM_R,SRR_RR_M
 SG_ SAS_SteerWheelAngleValid : 39|2@0+ (1,0) [0|1] ""  ACM,LDM_L,LDM_R,SRR_RR_M
 SG_ SAS_SteerWheelAngle : 47|16@0+ (0.0238,-780) [-780|779.7] "deg"  ACM,BCM,LDM_L,LDM_R,SRR_RR_M

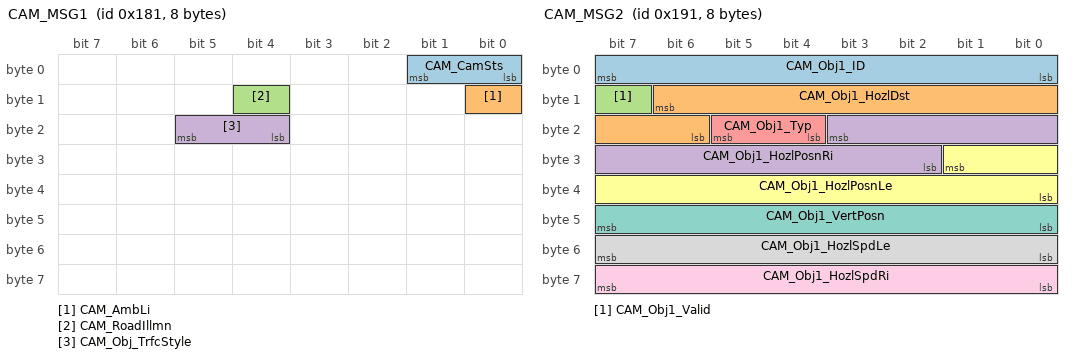
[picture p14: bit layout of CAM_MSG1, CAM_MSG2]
BO_ 385 CAM_MSG1: 8 XGW_Body
 SG_ CAM_CamSts : 1|2@0+ (1,0) [0|3] ""  LDM_L,LDM_R
 SG_ CAM_AmbLi : 8|1@0+ (1,0) [0|1] ""  LDM_L,LDM_R
 SG_ CAM_RoadIllmn : 12|1@0+ (1,0) [0|1] ""  LDM_L,LDM_R
 SG_ CAM_Obj_TrfcStyle : 21|2@0+ (1,0) [0|3] ""  LDM_L,LDM_R

 BO_ 388 FCAM_BCM_Status: 8 XGW_Body
 SG_ CHKSM_FCAM_BCM_Status : 7|8@0+ (1,0) [0|255] ""  BCM
 SG_ ALIVE_FCAM_BCM_Status : 11|4@0+ (1,0) [0|14] ""  BCM
 SG_ FCAM_BCM_IndicatorlightReq : 15|3@0+ (1,0) [0|7] ""  BCM
 SG_ SECCAN_FCAM_BCM_Sts : 63|8@0+ (1,0) [0|255] ""  BCM

BO_ 401 CAM_MSG2: 8 XGW_Body
 SG_ CAM_Obj1_ID : 7|8@0+ (1,0) [0|255] ""  LDM_L,LDM_R
 SG_ CAM_Obj1_HozlDst : 14|9@0+ (1,0) [0|511] "m"  LDM_L,LDM_R
 SG_ CAM_Obj1_Valid : 15|1@0+ (1,0) [0|1] ""  LDM_L,LDM_R
 SG_ CAM_Obj1_HozlPosnRi : 19|10@0+ (0.08,-40) [-40|40] "degree"  LDM_L,LDM_R
 SG_ CAM_Obj1_Typ : 21|2@0+ (1,0) [0|3] ""  LDM_L,LDM_R
 SG_ CAM_Obj1_HozlPosnLe : 25|10@0+ (0.08,-40) [-40|40] "degree"  LDM_L,LDM_R
 SG_ CAM_Obj1_VertPosn : 47|8@0+ (0.1,-12) [-12|12] "degree"  LDM_L,LDM_R
 SG_ CAM_Obj1_HozlSpdLe : 55|8@0+ (0.5,-64) [-64|63.5] "degree/s"  LDM_L,LDM_R
 SG_ CAM_Obj1_HozlSpdRi : 63|8@0+ (0.5,-64) [-64|63.5] "degree/s"  LDM_L,LDM_R

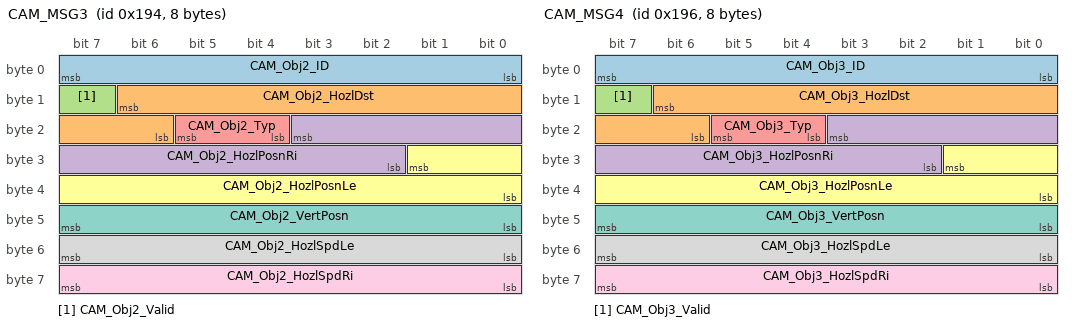
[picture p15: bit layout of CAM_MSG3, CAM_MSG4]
BO_ 404 CAM_MSG3: 8 XGW_Body
 SG_ CAM_Obj2_ID : 7|8@0+ (1,0) [0|255] ""  LDM_L,LDM_R
 SG_ CAM_Obj2_HozlDst : 14|9@0+ (1,0) [0|511] "m"  LDM_L,LDM_R
 SG_ CAM_Obj2_Valid : 15|1@0+ (1,0) [0|1] ""  LDM_L,LDM_R
 SG_ CAM_Obj2_HozlPosnRi : 19|10@0+ (0.08,-40) [-40|40] "degree"  LDM_L,LDM_R
 SG_ CAM_Obj2_Typ : 21|2@0+ (1,0) [0|3] ""  LDM_L,LDM_R
 SG_ CAM_Obj2_HozlPosnLe : 25|10@0+ (0.08,-40) [-40|40] "degree"  LDM_L,LDM_R
 SG_ CAM_Obj2_VertPosn : 47|8@0+ (0.1,-12) [-12|12] "degree"  LDM_L,LDM_R
 SG_ CAM_Obj2_HozlSpdLe : 55|8@0+ (0.5,-64) [-64|63.5] "degree/s"  LDM_L,LDM_R
 SG_ CAM_Obj2_HozlSpdRi : 63|8@0+ (0.5,-64) [-64|63.5] "degree/s"  LDM_L,LDM_R

BO_ 406 CAM_MSG4: 8 XGW_Body
 SG_ CAM_Obj3_ID : 7|8@0+ (1,0) [0|255] ""  LDM_L,LDM_R
 SG_ CAM_Obj3_HozlDst : 14|9@0+ (1,0) [0|511] "m"  LDM_L,LDM_R
 SG_ CAM_Obj3_Valid : 15|1@0+ (1,0) [0|1] ""  LDM_L,LDM_R
 SG_ CAM_Obj3_HozlPosnRi : 19|10@0+ (0.08,-40) [-40|40] "degree"  LDM_L,LDM_R
 SG_ CAM_Obj3_Typ : 21|2@0+ (1,0) [0|3] ""  LDM_L,LDM_R
 SG_ CAM_Obj3_HozlPosnLe : 25|10@0+ (0.08,-40) [-40|40] "degree"  LDM_L,LDM_R
 SG_ CAM_Obj3_VertPosn : 47|8@0+ (0.1,-12) [-12|12] "degree"  LDM_L,LDM_R
 SG_ CAM_Obj3_HozlSpdLe : 55|8@0+ (0.5,-64) [-64|63.5] "degree/s"  LDM_L,LDM_R
 SG_ CAM_Obj3_HozlSpdRi : 63|8@0+ (0.5,-64) [-64|63.5] "degree/s"  LDM_L,LDM_R

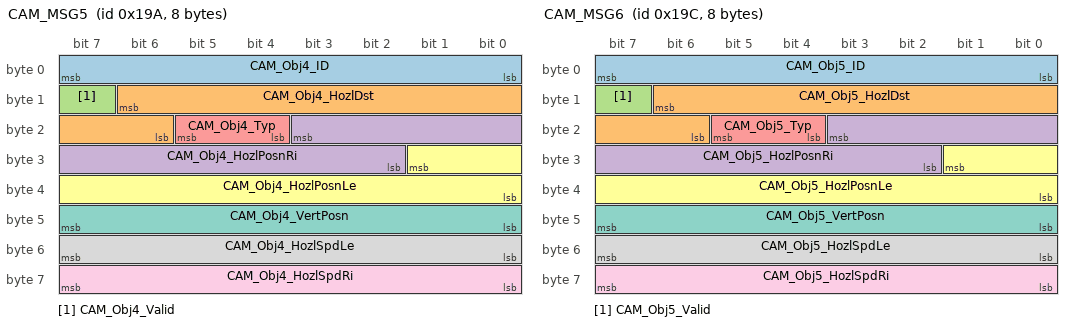
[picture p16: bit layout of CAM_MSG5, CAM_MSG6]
BO_ 410 CAM_MSG5: 8 XGW_Body
 SG_ CAM_Obj4_ID : 7|8@0+ (1,0) [0|255] ""  LDM_L,LDM_R
 SG_ CAM_Obj4_HozlDst : 14|9@0+ (1,0) [0|511] "m"  LDM_L,LDM_R
 SG_ CAM_Obj4_Valid : 15|1@0+ (1,0) [0|1] ""  LDM_L,LDM_R
 SG_ CAM_Obj4_HozlPosnRi : 19|10@0+ (0.08,-40) [-40|40] "degree"  LDM_L,LDM_R
 SG_ CAM_Obj4_Typ : 21|2@0+ (1,0) [0|3] ""  LDM_L,LDM_R
 SG_ CAM_Obj4_HozlPosnLe : 25|10@0+ (0.08,-40) [-40|40] "degree"  LDM_L,LDM_R
 SG_ CAM_Obj4_VertPosn : 47|8@0+ (0.1,-12) [-12|12] "degree"  LDM_L,LDM_R
 SG_ CAM_Obj4_HozlSpdLe : 55|8@0+ (0.5,-64) [-64|63.5] "degree/s"  LDM_L,LDM_R
 SG_ CAM_Obj4_HozlSpdRi : 63|8@0+ (0.5,-64) [-64|63.5] "degree/s"  LDM_L,LDM_R

BO_ 412 CAM_MSG6: 8 XGW_Body
 SG_ CAM_Obj5_ID : 7|8@0+ (1,0) [0|255] ""  LDM_L,LDM_R
 SG_ CAM_Obj5_HozlDst : 14|9@0+ (1,0) [0|511] "m"  LDM_L,LDM_R
 SG_ CAM_Obj5_Valid : 15|1@0+ (1,0) [0|1] ""  LDM_L,LDM_R
 SG_ CAM_Obj5_HozlPosnRi : 19|10@0+ (0.08,-40) [-40|40] "degree"  LDM_L,LDM_R
 SG_ CAM_Obj5_Typ : 21|2@0+ (1,0) [0|3] ""  LDM_L,LDM_R
 SG_ CAM_Obj5_HozlPosnLe : 25|10@0+ (0.08,-40) [-40|40] "degree"  LDM_L,LDM_R
 SG_ CAM_Obj5_VertPosn : 47|8@0+ (0.1,-12) [-12|12] "degree"  LDM_L,LDM_R
 SG_ CAM_Obj5_HozlSpdLe : 55|8@0+ (0.5,-64) [-64|63.5] "degree/s"  LDM_L,LDM_R
 SG_ CAM_Obj5_HozlSpdRi : 63|8@0+ (0.5,-64) [-64|63.5] "degree/s"  LDM_L,LDM_R

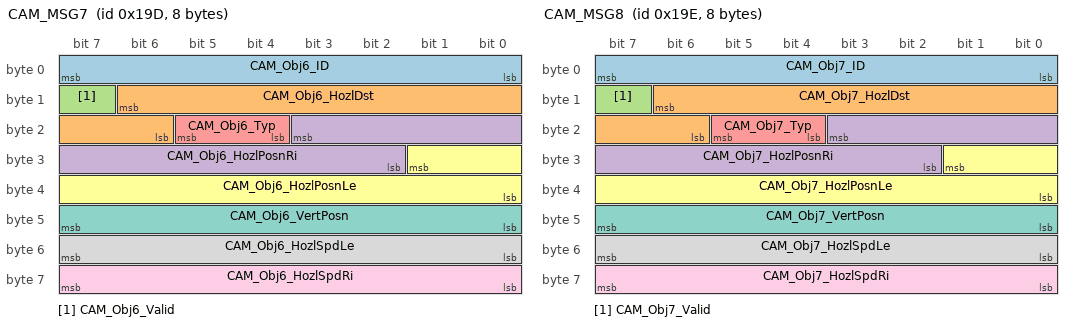
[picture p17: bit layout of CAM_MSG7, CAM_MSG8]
BO_ 413 CAM_MSG7: 8 XGW_Body
 SG_ CAM_Obj6_ID : 7|8@0+ (1,0) [0|255] ""  LDM_L,LDM_R
 SG_ CAM_Obj6_HozlDst : 14|9@0+ (1,0) [0|511] "m"  LDM_L,LDM_R
 SG_ CAM_Obj6_Valid : 15|1@0+ (1,0) [0|1] ""  LDM_L,LDM_R
 SG_ CAM_Obj6_HozlPosnRi : 19|10@0+ (0.08,-40) [-40|40] "degree"  LDM_L,LDM_R
 SG_ CAM_Obj6_Typ : 21|2@0+ (1,0) [0|3] ""  LDM_L,LDM_R
 SG_ CAM_Obj6_HozlPosnLe : 25|10@0+ (0.08,-40) [-40|40] "degree"  LDM_L,LDM_R
 SG_ CAM_Obj6_VertPosn : 47|8@0+ (0.1,-12) [-12|12] "degree"  LDM_L,LDM_R
 SG_ CAM_Obj6_HozlSpdLe : 55|8@0+ (0.5,-64) [-64|63.5] "degree/s"  LDM_L,LDM_R
 SG_ CAM_Obj6_HozlSpdRi : 63|8@0+ (0.5,-64) [-64|63.5] "degree/s"  LDM_L,LDM_R

BO_ 414 CAM_MSG8: 8 XGW_Body
 SG_ CAM_Obj7_ID : 7|8@0+ (1,0) [0|255] ""  LDM_L,LDM_R
 SG_ CAM_Obj7_HozlDst : 14|9@0+ (1,0) [0|511] "m"  LDM_L,LDM_R
 SG_ CAM_Obj7_Valid : 15|1@0+ (1,0) [0|1] ""  LDM_L,LDM_R
 SG_ CAM_Obj7_HozlPosnRi : 19|10@0+ (0.08,-40) [-40|40] "degree"  LDM_L,LDM_R
 SG_ CAM_Obj7_Typ : 21|2@0+ (1,0) [0|3] ""  LDM_L,LDM_R
 SG_ CAM_Obj7_HozlPosnLe : 25|10@0+ (0.08,-40) [-40|40] "degree"  LDM_L,LDM_R
 SG_ CAM_Obj7_VertPosn : 47|8@0+ (0.1,-12) [-12|12] "degree"  LDM_L,LDM_R
 SG_ CAM_Obj7_HozlSpdLe : 55|8@0+ (0.5,-64) [-64|63.5] "degree/s"  LDM_L,LDM_R
 SG_ CAM_Obj7_HozlSpdRi : 63|8@0+ (0.5,-64) [-64|63.5] "degree/s"  LDM_L,LDM_R

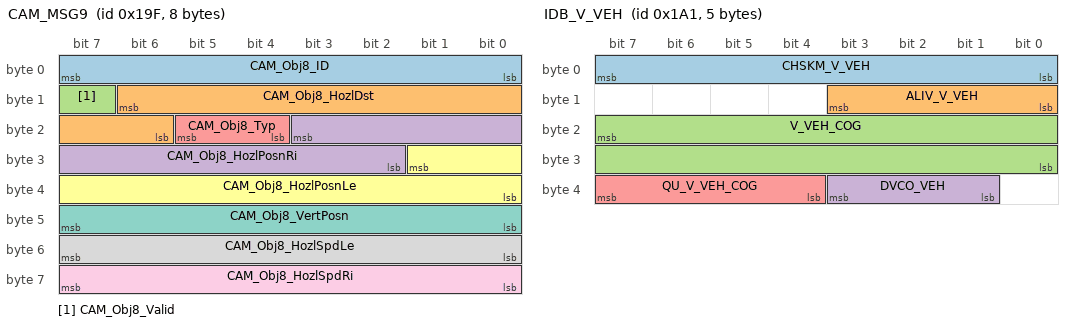
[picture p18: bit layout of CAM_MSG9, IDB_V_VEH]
BO_ 415 CAM_MSG9: 8 XGW_Body
 SG_ CAM_Obj8_ID : 7|8@0+ (1,0) [0|255] ""  LDM_L,LDM_R
 SG_ CAM_Obj8_HozlDst : 14|9@0+ (1,0) [0|511] "m"  LDM_L,LDM_R
 SG_ CAM_Obj8_Valid : 15|1@0+ (1,0) [0|1] ""  LDM_L,LDM_R
 SG_ CAM_Obj8_HozlPosnRi : 19|10@0+ (0.08,-40) [-40|40] "degree"  LDM_L,LDM_R
 SG_ CAM_Obj8_Typ : 21|2@0+ (1,0) [0|3] ""  LDM_L,LDM_R
 SG_ CAM_Obj8_HozlPosnLe : 25|10@0+ (0.08,-40) [-40|40] "degree"  LDM_L,LDM_R
 SG_ CAM_Obj8_VertPosn : 47|8@0+ (0.1,-12) [-12|12] "degree"  LDM_L,LDM_R
 SG_ CAM_Obj8_HozlSpdLe : 55|8@0+ (0.5,-64) [-64|63.5] "degree/s"  LDM_L,LDM_R
 SG_ CAM_Obj8_HozlSpdRi : 63|8@0+ (0.5,-64) [-64|63.5] "degree/s"  LDM_L,LDM_R

BO_ 417 IDB_V_VEH: 5 XGW_Body
 SG_ CHSKM_V_VEH : 7|8@0+ (1,0) [0|255] ""  ACM, USS_F, USS_R
 SG_ ALIV_V_VEH : 11|4@0+ (1,0) [0|14] ""  ACM, USS_F, USS_R
 SG_ V_VEH_COG : 23|16@0+ (0.015625,0) [0|350] "km/h"  ACM
 SG_ DVCO_VEH : 35|3@0+ (1,0) [0|7] ""  ACM, USS_F, USS_R
 SG_ QU_V_VEH_COG : 39|4@0+ (1,0) [0|15] ""  ACM

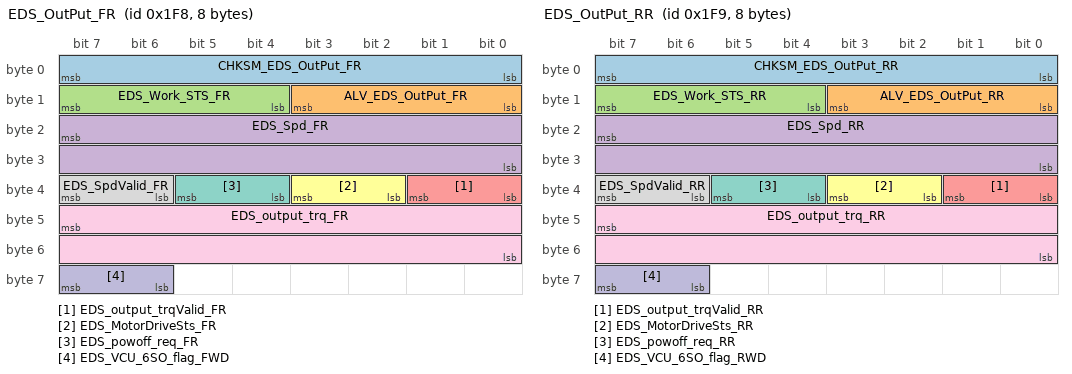
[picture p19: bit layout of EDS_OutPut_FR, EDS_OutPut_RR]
BO_ 504 EDS_OutPut_FR: 8 XGW_Body
 SG_ CHKSM_EDS_OutPut_FR : 7|8@0+ (1,0) [0|255] ""  ACM,APM,ASU_Gateway,BCM_BPM,CCU_F,CCU_R,ETG,LDM_L,LDM_R,OCS_P,PSM_D,SHVU_F,SHVU_R,TRM
 SG_ ALV_EDS_OutPut_FR : 11|4@0+ (1,0) [0|14] ""  ACM,APM,ASU_Gateway,BCM_BPM,CCU_F,CCU_R,ETG,LDM_L,LDM_R,OCS_P,PSM_D,SHVU_F,SHVU_R,TRM
 SG_ EDS_Work_STS_FR : 15|4@0+ (1,0) [0|15] "-"  ACM,APM,ASU_Gateway,BCM_BPM,CCU_F,CCU_R,ETG,LDM_L,LDM_R,OCS_P,PSM_D,SHVU_F,SHVU_R,TRM
 SG_ EDS_Spd_FR : 23|16@0+ (1,-20000) [-20000|20000] "rpm"  ACM,APM,ASU_Gateway,BCM_BPM,CCU_F,CCU_R,ETG,LDM_L,LDM_R,OCS_P,PSM_D,SHVU_F,SHVU_R,TRM
 SG_ EDS_output_trqValid_FR : 33|2@0+ (1,0) [0|1] ""  ACM,APM,ASU_Gateway,BCM_BPM,CCU_F,CCU_R,ETG,LDM_L,LDM_R,OCS_P,PSM_D,SHVU_F,SHVU_R,TRM
 SG_ EDS_MotorDriveSts_FR : 35|2@0+ (1,0) [0|3] ""  ACM,APM,ASU_Gateway,BCM_BPM,CCU_F,CCU_R,ETG,LDM_L,LDM_R,OCS_P,PSM_D,SHVU_F,SHVU_R,TRM
 SG_ EDS_powoff_req_FR : 37|2@0+ (1,0) [0|1] ""  ACM,APM,ASU_Gateway,BCM_BPM,CCU_F,CCU_R,ETG,LDM_L,LDM_R,OCS_P,PSM_D,SHVU_F,SHVU_R,TRM
 SG_ EDS_SpdValid_FR : 39|2@0+ (1,0) [0|1] ""  ACM,APM,ASU_Gateway,BCM_BPM,CCU_F,CCU_R,ETG,LDM_L,LDM_R,OCS_P,PSM_D,SHVU_F,SHVU_R,TRM
 SG_ EDS_output_trq_FR : 47|16@0+ (1,-2000) [-2000|2000] "Nm"  ACM,APM,ASU_Gateway,BCM_BPM,CCU_F,CCU_R,ETG,LDM_L,LDM_R,OCS_P,PSM_D,SHVU_F,SHVU_R,TRM
 SG_ EDS_VCU_6SO_flag_FWD : 63|2@0+ (1,0) [0|1] ""  ACM,APM,ASU_Gateway,BCM_BPM,CCU_F,CCU_R,ETG,LDM_L,LDM_R,OCS_P,PSM_D,SHVU_F,SHVU_R,TRM

BO_ 505 EDS_OutPut_RR: 8 XGW_Body
 SG_ CHKSM_EDS_OutPut_RR : 7|8@0+ (1,0) [0|255] ""  ACM,APM,ASU_Gateway,BCM_BPM,CCU_F,CCU_R,ETG,LDM_L,LDM_R,OCS_P,PSM_D,SHVU_F,SHVU_R,TRM
 SG_ ALV_EDS_OutPut_RR : 11|4@0+ (1,0) [0|14] ""  ACM,APM,ASU_Gateway,BCM_BPM,CCU_F,CCU_R,ETG,LDM_L,LDM_R,OCS_P,PSM_D,SHVU_F,SHVU_R,TRM
 SG_ EDS_Work_STS_RR : 15|4@0+ (1,0) [0|15] "-"  ACM,APM,ASU_Gateway,BCM_BPM,CCU_F,CCU_R,ETG,LDM_L,LDM_R,OCS_P,PSM_D,SHVU_F,SHVU_R,TRM
 SG_ EDS_Spd_RR : 23|16@0+ (1,-20000) [-20000|20000] "rpm"  ACM,APM,ASU_Gateway,BCM_BPM,CCU_F,CCU_R,ETG,LDM_L,LDM_R,OCS_P,PSM_D,SHVU_F,SHVU_R,TRM
 SG_ EDS_output_trqValid_RR : 33|2@0+ (1,0) [0|1] ""  ACM,APM,ASU_Gateway,BCM_BPM,CCU_F,CCU_R,ETG,LDM_L,LDM_R,OCS_P,PSM_D,SHVU_F,SHVU_R,TRM
 SG_ EDS_MotorDriveSts_RR : 35|2@0+ (1,0) [0|3] ""  ACM,APM,ASU_Gateway,BCM_BPM,CCU_F,CCU_R,ETG,LDM_L,LDM_R,OCS_P,PSM_D,SHVU_F,SHVU_R,TRM
 SG_ EDS_powoff_req_RR : 37|2@0+ (1,0) [0|1] ""  ACM,APM,ASU_Gateway,BCM_BPM,CCU_F,CCU_R,ETG,LDM_L,LDM_R,OCS_P,PSM_D,SHVU_F,SHVU_R,TRM
 SG_ EDS_SpdValid_RR : 39|2@0+ (1,0) [0|1] ""  ACM,APM,ASU_Gateway,BCM_BPM,CCU_F,CCU_R,ETG,LDM_L,LDM_R,OCS_P,PSM_D,SHVU_F,SHVU_R,TRM
 SG_ EDS_output_trq_RR : 47|16@0+ (1,-2000) [-2000|2000] "Nm"  ACM,APM,ASU_Gateway,BCM_BPM,CCU_F,CCU_R,ETG,LDM_L,LDM_R,OCS_P,PSM_D,SHVU_F,SHVU_R,TRM
 SG_ EDS_VCU_6SO_flag_RWD : 63|2@0+ (1,0) [0|1] "-"  ACM,APM,ASU_Gateway,BCM_BPM,CCU_F,CCU_R,ETG,LDM_L,LDM_R,OCS_P,PSM_D,SHVU_F,SHVU_R,TRM

BO_ 519 BCM_SunroofSts: 8 BCM
 SG_ SR_Undervoltage_Fault_Sts : 0|1@0+ (1,0) [0|1] ""  XGW_Body
 SG_ SR_Overvoltage_Fault_Sts : 1|1@0+ (1,0) [0|1] ""  XGW_Body
 SG_ SR_SLEEP_RQ : 2|1@0+ (1,0) [0|1] "-"  XGW_Body
 SG_ SR_Position : 5|3@0+ (1,0) [0|7] ""  XGW_Body
 SG_ SR_Motor_Running_Sts : 7|2@0+ (1,0) [0|3] ""  XGW_Body
 SG_ SR_MotorReverse_Fault_Sts : 8|1@0+ (1,0) [0|1] ""  XGW_Body
 SG_ SR_Hall_Fault_Sts : 9|1@0+ (1,0) [0|1] ""  XGW_Body
 SG_ SR_Normalisation_Sts : 10|1@0+ (1,0) [0|1] ""  XGW_Body
 SG_ SR_Relay_Fault : 11|1@0+ (1,0) [0|1] ""  XGW_Body
 SG_ SR_Commu_Fault_Sts : 12|1@0+ (1,0) [0|1] ""  XGW_Body
 SG_ SR_Initialisation_Status : 13|1@0+ (1,0) [0|1] ""  XGW_Body
 SG_ SR_Ctrl_Result : 15|2@0+ (1,0) [0|3] ""  XGW_Body
 SG_ SR_ThermalProtection_Fault_Sts : 16|1@0+ (1,0) [0|1] "-"  XGW_Body
 SG_ SR_Posit_Percentage : 23|7@0+ (1,0) [0|100] "%"  XGW_Body
 SG_ SR_Operation_Stat : 27|4@0+ (1,0) [0|8] "-"  XGW_Body
 SG_ SR_Error_RSP : 28|1@0+ (1,0) [0|1] ""  XGW_Body
 SG_ BCM_AutoSunroof_Sts : 30|2@0+ (1,0) [0|3] ""  XGW_Body

BO_ 520 BCM_SunshadeSts: 8 BCM
 SG_ SS_MotorReverse_Fault_Status : 0|1@0+ (1,0) [0|1] ""  XGW_Body
 SG_ SS_Motor_Running_Status : 2|2@0+ (1,0) [0|3] ""  XGW_Body
 SG_ SS_Position : 5|3@0+ (1,0) [0|7] ""  XGW_Body
 SG_ SS_SLEEP_RQ : 6|1@0+ (1,0) [0|1] "-"  XGW_Body
 SG_ SS_Undervoltage_Fault_Status : 7|1@0+ (1,0) [0|1] ""  XGW_Body
 SG_ SS_Ctrl_Result : 9|2@0+ (1,0) [0|3] ""  XGW_Body
 SG_ SS_Overvoltage_Fault_Status : 10|1@0+ (1,0) [0|1] ""  XGW_Body
 SG_ SS_Relay_Fault : 11|1@0+ (1,0) [0|1] ""  XGW_Body
 SG_ SS_Normalisation_Status : 12|1@0+ (1,0) [0|1] ""  XGW_Body
 SG_ SS_Hall_Fault_Status : 13|1@0+ (1,0) [0|1] ""  XGW_Body
 SG_ SS_Commu_Fault_Status : 14|1@0+ (1,0) [0|1] ""  XGW_Body
 SG_ SS_Initialisation_Status : 15|1@0+ (1,0) [0|1] ""  XGW_Body
 SG_ SS_Posit_Percentage : 22|7@0+ (1,0) [0|100] "%"  XGW_Body
 SG_ SS_ThermalProtection_Flt_Sts : 23|1@0+ (1,0) [0|1] ""  XGW_Body
 SG_ SS_Operation_State : 31|3@0+ (1,0) [0|7] ""  XGW_Body
 SG_ SECCAN_SunshadeSts : 55|8@0+ (1,0) [0|255] ""  XGW_Body
 SG_ SS_Error_RSP : 63|1@0+ (1,0) [0|1] ""  XGW_Body

CM_ "This dbc file for FRS build";
CM_ BU_ ACM "Airbag Control Module";
CM_ BU_ ADAS_Body "Advance Driver Assistance System";
CM_ BU_ APM "Anti Pinch Module";
CM_ BU_ ASU_Gateway "Air Spring Control Unit";
CM_ BU_ BCM "Body Control Module";
CM_ BU_ BCM_BPM "Second chip of Body Control Module";
CM_ BU_ CCU_F "Climate Control Unit Front";
CM_ BU_ CCU_R "Climate Control Unit Rear";
CM_ BU_ ETG "Electric Tail Gate";
CM_ BU_ LDM_L "Led Driving Matrix Left";
CM_ BU_ LDM_R "Led Driving Matrix Right";
CM_ BU_ OCS_P "Occupant Classification System";
CM_ BU_ PSM_D "Power Seat Module Driver";
CM_ BU_ SHVU_F "Seat Heating and Ventilation Unit Front";
CM_ BU_ SHVU_R "Seat Heating and Ventilation Unit Rear";
CM_ BU_ TRM "Trailer Module";
CM_ BU_ XGW_Body "Gateway";
CM_ BO_ 518 "ADAS_ELK";
CM_ SG_ 518 ADAS_ALC_txtpopup "ALC Text Popups Based on system states- functional cases";
CM_ SG_ 518 ADAS_Lane_Line_Curva_Radius "Lane line curvature redius (minus for left curve, plus for right curve, radius > 1000m, display as straight curve";
CM_ SG_ 518 ADAS_LA_Display "Lane assist function and lane display";
CM_ SG_ 518 ADAS_ALC_state "ALC state";
CM_ SG_ 518 ADAS_handsoff_txtpopup "Hands off warning popup text";
CM_ SG_ 518 ADAS_Mode2_status "System mode: Mode 1 & 2";
CM_ SG_ 518 ADAS_handsoff_Warning_Mode_2 "Hands off warning level";
CM_ SG_ 518 ADAS_HWA_state "HWA state";
CM_ SG_ 518 ADAS_ALC_Mode_feed "ALCA feedback status";
CM_ SG_ 518 ADAS_HWA_txtpopup "HWA Text Popups Based on system states- functional cases";
CM_ SG_ 518 ADAS_ELK_check "Emergency Lane Keeping check";
CM_ SG_ 518 ADAS_HWA_Fautlstate "HWA fault status";
CM_ SG_ 518 ALV_ADAS_ELK "Alive Counter";
CM_ SG_ 518 CHKSM_ADAS_ELK "Checksum";
CM_ BO_ 133 "ACM Message for crash details";
CM_ SG_ 133 CHKSM_CRASH_Sts "Checksum";
CM_ SG_ 133 ALV_CRASH_Sts "Alive Counter";
CM_ SG_ 133 ACM_Crash_Sts "Crash status";
CM_ SG_ 133 ACM_Airbag_Deployment_Status "Signal to indicate if airbag pretensioner pyrofuse is deployed";
CM_ SG_ 133 ACM_Crash_Intensity "Indicate crash intensity level";
CM_ SG_ 133 ACM_Front_Crash "Output information for direction of crash";
CM_ SG_ 133 ACM_DriverSide_Crash "Output information for direction of crash";
CM_ SG_ 133 ACM_PassSide_Crash "Output information for direction of crash";
CM_ SG_ 133 ACM_Rear_Crash "Output information for direction of crash";
CM_ SG_ 133 ACM_Rollover_Crash "Output information for direction of crash";
CM_ BO_ 134 " ";
CM_ SG_ 134 ACM_CrashDeltaV_PackID "Pack ID, each pack ID contain 3 sample  [DeltaVx ; DeltaVy]​. There are 26 samples, so ID range will be from 1 to 9​";
CM_ SG_ 134 ACM_DeltaVx_01 "Delta velocity longitudinal sample 1 of pack";
CM_ SG_ 134 ACM_DeltaVx_02 "Delta velocity longitudinal sample 2 of pack";
CM_ SG_ 134 ACM_DeltaVx_03 "Delta velocity longitudinal sample 3 of pack";
CM_ SG_ 134 ACM_DeltaVy_01 "Delta velocity lateral sample 1 of pack​";
CM_ SG_ 134 ACM_DeltaVy_02 "Delta velocity lateral sample 2 of pack​";
CM_ SG_ 134 ACM_DeltaVy_03 "Delta velocity lateral sample 3 of pack​";
CM_ BO_ 149 "EPBi Function";
CM_ SG_ 149 CHKSM_IDB_FUNCTION "Checksum";
CM_ SG_ 149 ALV_IDB_FUNCTION "Alive counter";
CM_ SG_ 149 STAT_ABS "ABS Status";
CM_ SG_ 149 ABS_Active "ABS function active.";
CM_ SG_ 149 AYC_Active "Active yaw control";
CM_ SG_ 149 ASR_Active "ASR Traction Control active";
CM_ SG_ 149 STAT_DSC "Dynamic Stability Control status";
CM_ SG_ 149 DSC_Active "DSC function active.";
CM_ SG_ 149 HBA_ActiveSignal "HBA active signal";
CM_ SG_ 149 ARM_ActiveSignal "ARM active signal";
CM_ SG_ 149 STAT_AutoHazardBlinking "Indicates IDB/ABS emergency brake";
CM_ SG_ 149 MSR_Active "engine drag torque control active";
CM_ SG_ 149 HSA_ActiveSignal "HSA active signal, It will set to 0x1: Active when HHC activated, it will set back to 0x0:Inactive when HHC not active or deactivated.";
CM_ SG_ 149 EPBi_ECD_ActiveSignal "this signal indicates EPBi active or not after EPBi receives ECD request";
CM_ SG_ 149 TSM_Active "TSM Active";
CM_ SG_ 149 HAS_Available "HAS Hill Hold Available";
CM_ SG_ 149 STAT_EBD "EBD Electronic Brake Distribution Status";
CM_ SG_ 149 EBD_Active "EBD function active.";
CM_ SG_ 149 ST_BRG_MSA "Prediction of whether the vehicle is held by the DSC at v = 0 km/h. (Receiver: EMS)";
CM_ BO_ 217 "High Voltage Drive System Status";
CM_ SG_ 217 CRC_VCU_HV_DrvSys_status "Checksum";
CM_ SG_ 217 ALIV_VCU_HV_DrvSys_status "Alive counter";
CM_ SG_ 217 VCU_HVsystem_status "High Voltage system status";
CM_ SG_ 217 VCU_ACPD_Percent "The signal contains the actual angle of the acceleration pedal100% acceleration pedal position shall only provided in case of kick down.Without kickdown the maximum value shall be 99.";
CM_ SG_ 217 VCU_ACPD_Percent_Valid "Qualifier for corresponding signal.  In value table not defined values are reserved";
CM_ SG_ 217 VCU_ACTGear "actual gear,Provide gear shift signal";
CM_ SG_ 217 VCU_ACTGearValid "Indicate the current gear position";
CM_ SG_ 217 VCU_ACT_DriveMode "Vehicle drive mode";
CM_ SG_ 217 VCU_ACT_DriveMode_Valid "Vehicle drive mode status";
CM_ SG_ 217 VCU_HV_DRVsystem_status "Status of driving system ( Highvoltage )";
CM_ SG_ 217 VCU_Recu_BrakeLight_ON_Req "VCU request brake light ON when regen";
CM_ BO_ 256 "MHU_Vehicle_Info";
CM_ SG_ 256 CHKSM_MHU_VEH_INFO "Checksum";
CM_ SG_ 256 ALV_MHU_VEH_INFO "Alive Counter";
CM_ SG_ 256 MHU_UserProfileId "User profile ID, support 10 user profiles in maxinum, 0xF is invalid signal";
CM_ SG_ 256 MHU_Connectivity_Status "Internet Connection Connectivity Status";
CM_ BO_ 258 "Logical Clamp status for  Vehicle";
CM_ SG_ 258 CHKSM_BCM_LOGICAL_CLAMP "Checksum";
CM_ SG_ 258 ALIVE_BCM_LOGICAL_CLAMP "Alive counter";
CM_ SG_ 258 STAT_CL30s_Light_L "Logical clamp status";
CM_ SG_ 258 STAT_CL30s_L "Status Clamp 30s Logical ON/OFF";
CM_ SG_ 258 STAT_CL15Wup_L "Status Clamp 15 WakeUp Signal Logical";
CM_ SG_ 258 STAT_CrankRelayHW_BCM "Represents the status of the starter relais";
CM_ BO_ 259 "BCM Energy Management";
CM_ SG_ 259 REQ_ConsumerControlWirelessCharg "Consumer control WLC  for powermanagement";
CM_ SG_ 259 REQ_ConsumerControlAudioVolumeCo "Consumer control audio volume for powermanagement";
CM_ SG_ 259 REQ_ConsumerControlSeatMassage "Consumer control WLC  for SeatMassage powermanagement";
CM_ SG_ 259 REQ_CCU_PTC_Limitation "Consumer control PTC for powermanagement";
CM_ SG_ 259 REQ_ConsumerControlRearDefrost "Consumer control rear defrost for powermanagement";
CM_ SG_ 259 REQ_ConsumerControlSeatHeatingRe "Consumer control rear seat heating  for powermanagement";
CM_ SG_ 259 REQ_ConsumerControlSeatVentilati "Consumer control seat venting for powermanagement";
CM_ SG_ 259 REQ_ConsumerControlSeatHeatingFr "Consumer control front seat heating  for powermanagement";
CM_ SG_ 259 DriverIdealTimerCount "Driver Ideal Timer Counter";
CM_ SG_ 259 REQ_ConsumerControlVentilationCl "Consumer control  ventilation (blower control clima) for powermanagement";
CM_ BO_ 260 "Actual name BCM_LVBAT_COM_INFO";
CM_ SG_ 260 CHKSM_LV_BATT_CHARG "Checksum";
CM_ SG_ 260 ALIV_LV_BATT_CHARG "Alive counter";
CM_ SG_ 260 SOH_SUL "Actual name LV_SOH (State of Health)";
CM_ SG_ 260 SOH_SUL_STATE "Actual name LV_SOH_Sts (SOH Status)";
CM_ SG_ 260 SOC_STATE "SOC Status";
CM_ SG_ 260 Resp_Error "Resp_Error";
CM_ SG_ 260 FLAG_INCONSTENCY "Battery inconsistency flag";
CM_ SG_ 260 EBS_error "EBS error";
CM_ SG_ 260 FLAG_DISCONNECT "Battery disconnection flag";
CM_ SG_ 260 BCM_LV_Batt_Charging_Req "BCM_LV_REQ";
CM_ SG_ 260 IBATT_QUIESCENT "IBATT_QUIESCENT ";
CM_ SG_ 260 LV_TargetVoltage "LV BMS sends out expected target voltage";
CM_ SG_ 260 LV_TargetCurrent "Target battery current from LV BMS";
CM_ BO_ 261 "BCM door flap state";
CM_ SG_ 261 CHKSM_BCM_STAT_DOOR_FLAP "Checksum";
CM_ SG_ 261 ALIVE_BCM_STAT_DOOR_FLAP "Alive counter";
CM_ SG_ 261 BCM_STAT_TrunkAjar "Trunk Ajar Door Status";
CM_ SG_ 261 BCM_STAT_DoorAjarFL "Ajar Door Front Left Status";
CM_ SG_ 261 BCM_STAT_DoorAjarFR "Ajar Door Front Right Status";
CM_ SG_ 261 BCM_STAT_DoorAjarRL "Ajar Door Rear Left Status";
CM_ SG_ 261 BCM_STAT_DoorAjarRR "Ajar Door Rear Right Status";
CM_ SG_ 261 BCM_STAT_BonnetAjar "Ajar Bonnet Status";
CM_ BO_ 262 "BCM LIGHT";
CM_ SG_ 262 CHKSM_BCM_LIGHT "Checksum";
CM_ SG_ 262 ALIVE_BCM_LIGHT "Alive counter";
CM_ SG_ 262 BCM_DayRunningLampSts "DayRunning Lamp output Status";
CM_ SG_ 262 BCM_ReverseLightSts "Reverse light output Status";
CM_ SG_ 262 BCM_StopLightSts "Stop light output Status";
CM_ SG_ 262 BCM_LicensePlateLightSts "License plate light output";
CM_ SG_ 262 BCM_Fr_Dimming_dome_lampSts "Dimming dome lamp Front Status";
CM_ SG_ 262 BCM_Rr_Dimming_dome_lampSts "Dimming dome lamp Rear Status";
CM_ SG_ 262 BCM_STAT_InteriorLight "Status for functional illumination in the interior light switch button";
CM_ SG_ 262 BCM_STAT_LightActivation "Status of light ";
CM_ SG_ 262 BCM_HighBeamSts "High beam output Status";
CM_ SG_ 262 BCM_STAT_SwitchLightBrightness "Confirm Brighness level of Switch illumination";
CM_ SG_ 262 BCM_LowBeamSts "Low beam output  Status";
CM_ SG_ 262 BCM_RearFogLmpSts "Rear fog output Status";
CM_ SG_ 262 BCM_FrntFogLmpSts "Front fog output Status";
CM_ SG_ 262 BCM_PosLmpSts "Position light output Status";
CM_ SG_ 262 BCM_BackGrdCl58Sts "Background CL58  output  Status";
CM_ SG_ 262 BCM_HornSts "Horn output Status";
CM_ SG_ 262 BCM_TurnIndicatorSts "Turn light output  Status";
CM_ BO_ 263 "BCM Status Central Lock";
CM_ SG_ 263 CHKSM_BCM_CENTRAL_LOCK "Checksum ";
CM_ SG_ 263 ALV_BCM_CENTRAL_LOCK "Alive counter";
CM_ SG_ 263 STAT_CDL_LED "Status of functional CDL button LED, value 2 represents implausible state";
CM_ SG_ 263 STAT_DoorUnlockFL "UnLock Status Driver Door not used for lock status";
CM_ SG_ 263 STAT_ATWS "Locking/UnLocking Status Anti theft Invalid value = 7";
CM_ SG_ 263 BCM_CentralLockSwSts "BCM Central LockSwitch Sts ";
CM_ SG_ 263 STAT_DoorLockFL "Lock Status Driver Door used as central lock information";
CM_ BO_ 265 "BCM switches status";
CM_ SG_ 265 CHKSM_BCM_SWITCH_Sts "Checksum";
CM_ SG_ 265 ALV_BCM_SWITCH_Sts "Alive counter";
CM_ SG_ 265 BCM_STAT_BrakeSwitch "Brake pedal switch BCM pressed (only for brake light)";
CM_ SG_ 265 BCM_STAT_HazardWarn "Hazard Warning switch activation";
CM_ SG_ 265 BCM_STAT_FuelPumpCutOFF "Status Fuel Pump cut off by crash";
CM_ SG_ 265 BCM_FollowMeHomeActive "BCM_FollowMeHomeActive";
CM_ SG_ 265 BCM_STAT_Horn "Status switch horn";
CM_ SG_ 265 BCM_STAT_Autowiping "Status for Autowiping ON /OFF";
CM_ SG_ 265 BCM_TurnIndicator "BCM_TurnIndicator";
CM_ SG_ 265 BCM_WelcomeActive "BCM Welcome Active";
CM_ SG_ 265 BCM_HighBeam "BCM_High beam ";
CM_ SG_ 265 ACM_Seat_Belt_Status_3rd_Row_Pas "Seatbelt status for seatbelt reminder function for 3rd Row Pass";
CM_ SG_ 265 ACM_Seat_Belt_Status_3rd_Row_Dri "Seatbelt status for seatbelt reminder function for 3rd Row Driver";
CM_ SG_ 265 BCM_AlcoholockSwitch "AlcoholockSwithDetect";
CM_ BO_ 266 "Low Voltage Battery";
CM_ SG_ 266 CHKSM_BCM_VOLTAGE "Checksum";
CM_ SG_ 266 ALIVE_BCM_VOLTAGE "Alive counter";
CM_ SG_ 266 LV_BatteryType "LV Battery Type (Lead Acid or Lithium)";
CM_ SG_ 266 UBatt "Battery Voltage";
CM_ SG_ 266 LV_Batt_Temp "Low voltage Battery Temperature";
CM_ SG_ 266 LV_SOC "State Of charge for Low Voltage Battery";
CM_ SG_ 266 LV_Batt_Current "Current of Low Voltage Battery";
CM_ BO_ 267 "TRM_LIGHT";
CM_ SG_ 267 ALIVE_TRM_LIGHT "Alive counter rolling counter of the message if it's over 14 then will swap back to 0 and increase again. Invalid Value = F";
CM_ SG_ 267 TrailerInput "Trailer synchronization confirmation with HW/SW";
CM_ SG_ 267 TrailerSystemError "Trailer error detection";
CM_ SG_ 267 TRM_VoltageStatus "Trailer voltage status";
CM_ SG_ 267 TRM_STAT_BrakeLight "Trailer Brake light status";
CM_ SG_ 267 TRM_STAT_FogLampRear "Trailer Rear fog lamp status";
CM_ SG_ 267 TRM_STAT_PositionLight "Trailer Position light status";
CM_ SG_ 267 TRM_STAT_TurnIndicators "Trailer Turn Indicatiors status";
CM_ SG_ 267 TRM_STAT_ReverseLight "Trailer Reverse light status";
CM_ SG_ 267 TRM_STAT_HWBrakeLightInput "Trailer hardwired Brake light inputstatus";
CM_ SG_ 267 TRM_STAT_HWIndicatorInput "Trailer hardwired Turn Indicatiors input status";
CM_ SG_ 267 TRM_STAT_HWPosLightInput "Trailer hardwired Position light input status";
CM_ BO_ 268 "GW_BCM_RemoteCtrlSts";
CM_ SG_ 268 Checksum_0x10C "Checksum";
CM_ SG_ 268 Rolling_Counter_0x10C "Rolling_Counter";
CM_ SG_ 268 BCM_TboxAuthStatus "MHU's TBOX authentication status";
CM_ SG_ 268 BCM_RandomNum32bit "BCM's random OTP 32 bits and refresh every 20 secs";
CM_ BO_ 269 "MHU_BCM_DoorsCtrl";
CM_ SG_ 269 MHU_APM_ReqWindow "Request control Window from MHU";
CM_ SG_ 269 MHU_BCM_RemoteDoorCtrl "MHU set door state remotely.";
CM_ SG_ 269 MHU_BCM_reqTrunk "MHU Set Trunk Ajar Door or Tailgate";
CM_ SG_ 269 MHU_BCM_reqFrunk "MHU unlock frunk or bonnet";
CM_ SG_ 269 MHU_BCM_ReqSunroof "MHU open sunroof by percentage value";
CM_ SG_ 269 TBOX_AuthCode_0x10D "TBOX Message Authentication Code of message 0x10D";
CM_ BO_ 270 "BCM ENTRY CONTROLBCM Entry Control";
CM_ SG_ 270 GlobalWindowReq "Global windows open/close CAN signal ";
CM_ SG_ 270 RemoteAccessKey "Status of remote key button Tailgate opening long press > 1.5 sec;";
CM_ SG_ 270 PassiveAccessTrunk "BCM request for passive entry trunk";
CM_ SG_ 270 ComfortOpen "Doorhandle or RKE request for comfort open.";
CM_ SG_ 270 PassiveAccessDoor "BCM request for passive entry door";
CM_ SG_ 270 FksOpen "The signal is send by BCM after BCM confirms that the vehilce should let PTG open";
CM_ BO_ 271 "MHU_BCM_HornLightControl";
CM_ SG_ 271 MHU_SetHornOnOff "Set horn ON/OFF";
CM_ SG_ 271 MHU_SetLowBeam "Set low beam light ON/FF";
CM_ SG_ 271 MHU_SetHighBeam "Set high beam light ON/FF";
CM_ SG_ 271 TBOX_AuthCode_0x10F "TBOX Message Authentication Code of message 0x10F";
CM_ BO_ 273 "BCM_Stat_SwitchLightBrightness";
CM_ SG_ 273 BCM_Stat_SwitchLightBrightness "BCM_Stat_SwitchLightBrightness";
CM_ SG_ 273 BCM_Rear_Wiper_Park_Pos_Status "Rear Wiper Park Position Status ";
CM_ SG_ 273 BCM_Front_Wiper_Park_Pos_Status "Front Wiper Park Position Status";
CM_ SG_ 273 BCM_Rear_Wash_Status "Rear Wiper Wash Status";
CM_ SG_ 273 BCM_Front_Wash_Status "Front Wiper Wash Status";
CM_ BO_ 274 "Clamp status for BEV vehicle";
CM_ SG_ 274 STAT_TransportMode "Status of Transport mode";
CM_ SG_ 274 CHKSM_BCM_CLAMP_STAT "Checksum";
CM_ SG_ 274 ALIVE_BCM_CLAMP_STAT "Alive counter";
CM_ SG_ 274 RemoteFunctionState "0x1(remote function) will be sent after PreRemoteStart=0x1 first time in ignition OFF state, and this signal will be kept 0x1 until SESAM exit remote state.";
CM_ SG_ 274 STAT_BLS "Signal represent plausibility of both HW Inputs for brake light switch.";
CM_ SG_ 274 STAT_CL_50_L "Logical clamp status";
CM_ SG_ 274 Clamp50AdviceRemoteStart "Engine Start announcement (Clamp 50) for remote start";
CM_ SG_ 274 Clamp50AdviceESS "Engine Start announcement (Clamp 50) for ESS";
CM_ SG_ 274 STAT_CL_R_L "Logical clamp status";
CM_ SG_ 274 STAT_CL_15_1_L "Logical clamp status";
CM_ SG_ 274 STAT_CL_15_1_DME_L "Logical clamp status";
CM_ SG_ 274 FobId "Information of FOB ID.";
CM_ SG_ 274 STAT_Terminal "Represent the status of physical terminal";
CM_ SG_ 274 STAT_CL30_C_BEV "Logical clamp status";
CM_ SG_ 274 BCM_Clamp_Transport "BCM_Clamp_Transport";
CM_ BO_ 276 "For Li-ion LV Battery only";
CM_ SG_ 276 CHKSM_LVBAT_DATA "Checksum";
CM_ SG_ 276 ALIV_LVBAT_DATA "Alive counter";
CM_ SG_ 276 LV_ErrorSts "LV Error status";
CM_ SG_ 276 LV_MinCellVolt "Min cell voltage";
CM_ SG_ 276 LV_MaxCellVolt "Max cell voltage";
CM_ SG_ 276 LV_MinCellTemp "Min cell temperature";
CM_ SG_ 276 LV_MaxCellTemp "Max cell temperature";
CM_ SG_ 276 LV_Discharger_Err "Discharge contactor (MOSFET) malfunction";
CM_ SG_ 276 LV_Discharger_Sts "The charge MOSFET status: Close/Open";
CM_ SG_ 276 LV_Charger_Err "Charge contactor (MOSFET) malfunction";
CM_ SG_ 276 LV_Charger_Sts "The discharge MOSFET status: Close/Open";
CM_ SG_ 276 LV_OverVoltage "Over voltage flag";
CM_ SG_ 276 LV_UnderVoltage "Under voltage flag";
CM_ SG_ 276 LV_OverCurrent "Over current flag";
CM_ SG_ 276 LV_UnderTemp "Under temperature flag";
CM_ SG_ 276 LV_OverTemp "Over temperature flag";
CM_ SG_ 276 LV_OverCharge "Over charge";
CM_ SG_ 276 LV_OverDischarge "Over discharge";
CM_ SG_ 276 LV_CellBalance_Sts "Cell balance operation status";
CM_ SG_ 276 LV_CellBalance_Error "Cell balance error status";
CM_ SG_ 276 LV_ThermalRunaway "Thermal runaway warning";
CM_ SG_ 276 LV_WarmupRequest "LV Warmup Request from the LV Lithium battery";
CM_ BO_ 277 "BCM_Childlock";
CM_ SG_ 277 BCM_ChildLock_Feedback "Response for Childlock Status";
CM_ BO_ 278 "BCM_LVBAT_COM_INFO2";
CM_ SG_ 278 CHKSM_LVBAT_INFO2 "Checksum";
CM_ SG_ 278 ALIV_LVBAT_INFO2 "Alive counter";
CM_ SG_ 278 LV_MaxAllowDischargeCurrent "Maximum discharge current that is allowed by LV BMS";
CM_ SG_ 278 LV_WakeupReason "LV Wakeup Reason";
CM_ SG_ 278 LV_MaxAllowChargeCurrent "Maximum charge current that is allowed by LV BMS";
CM_ SG_ 278 LV_SOE "State of Energy";
CM_ BO_ 280 "BCM_MHU_DrivingInhibitionFeed";
CM_ SG_ 280 CHKSM_BCM_MHU_Ctrl_Fbk "Checksum";
CM_ SG_ 280 ALV_BCM_MHU_Ctrl_Fbk "Alive Counter";
CM_ SG_ 280 BCM_DrvInhibitStsFbk "BCM Feedback status for Driving Inhibition";
CM_ BO_ 282 "MHU_ServiceMode_Setting";
CM_ SG_ 282 MHU_SET_WiperServicePositionMod "MHU request BCM to keyfob on the center comtrol to link this key to user profile";
CM_ SG_ 282 MHU_Read_KeyFobOnCenterConsole "MHU request BCM to keyfob on the center comtrol to link this key to user profile";
CM_ BO_ 283 "MHU_BCM_RemoteClampCtrl";
CM_ SG_ 283 TBOX_STAT_TerminalReq "CAR state switching request";
CM_ SG_ 283 TBOX_AuthCode_0x11B "TBOX Message Authentication Code of message";
CM_ BO_ 284 "MHU_BCM_FOTAClampCtrl";
CM_ SG_ 284 TBOX_FOTA_STAT_TerminalReq "CAR state switching request for FOTA";
CM_ BO_ 285 "CCU_RearHVACControl";
CM_ SG_ 285 CCU_ERL_Rear "Energy Requirement Level for Rear";
CM_ SG_ 285 CCU_EvapTempSet_Rear "Evaporator Target Temperature for Rear";
CM_ SG_ 285 CCU_AirDistribFlapPos_Rear "Air Distribution flap position Rear";
CM_ SG_ 285 CCU_BlowerFltPwm_Rear "Blower PWM Rear";
CM_ SG_ 285 CCU_DuctTargetTemp_Rear "Target Duct Temperature for Rear";
CM_ SG_ 285 CCU_TempFlapPos_Rear "Temperature flap position for Rear";
CM_ SG_ 285 CCU_FanSpeed_Rear "Blower settings/Fan Speed for climate system";
CM_ SG_ 285 CCUF_InteriorTemp_Rear "CCU interior temperature. Invalid = 251-255";
CM_ BO_ 286 "CCUR_SensorInfo";
CM_ SG_ 286 CCUR_DuctActRearFace "Actual Duct Temp Rear Face";
CM_ SG_ 286 CCUR_DuctActRearFoot "Actual Duct Temp Rear Foot";
CM_ SG_ 286 CCUR_EvaporatorTemp "Actual evaporator temperature of the HVAC unit. Invalid = 251-255";
CM_ SG_ 286 CCUR_InteriorTemp "CCU interior temperature. Invalid = 251-255";
CM_ SG_ 286 CCUR_AirDistribFeedback_Rear "Air Distribution flap feedback Rear";
CM_ SG_ 286 CCUR_TempFeedback_Rear "Temperature flap feedback for Rear";
CM_ SG_ 286 CCUR_BlowerFeedback_Rear "Blower feedback for Rear";
CM_ BO_ 287 "MHU_BCM_DrivingInhibition";
CM_ SG_ 287 MHU_DrvInhibitSts "MHU_DrivingInhibitionStatus";
CM_ SG_ 287 TBOX_AuthCode_0x11F "TBOX Message Authentication Code of message 0x11F";
CM_ BO_ 290 "CCU maximum request";
CM_ SG_ 290 CHKSM_CCU_REQUEST "Checksum";
CM_ SG_ 290 ALV_CCU_REQUEST "Alive Counter";
CM_ SG_ 290 CCU_REQ_MaxCool "Request for maximal cool down minimum level temp";
CM_ SG_ 290 CCU_REQ_MaxHeat "Request for maximal heat up maximum level temp";
CM_ SG_ 290 CCU_REQ_ESSMotorControl "This signal provides the status, to prevent the motorstop, or to request the motorstart.Invalid value = 7";
CM_ SG_ 290 CCU_AC_PWM "Compressor pwm value. 65h to 7Fh are invalid values. ";
CM_ BO_ 295 "ADAS Lane Departure Warning and Lane Keeping Assist";
CM_ SG_ 295 CHKSM_ADAS_LDW_LKA "Checksum";
CM_ SG_ 295 ALV_ADAS_LDW_LKA "Alive Counter";
CM_ SG_ 295 ADAS_ELKA_ON_feed "Feedback of MHU_ELKA_ON";
CM_ SG_ 295 ADAS_Mode1_status "System mode: Mode 1 & 2";
CM_ SG_ 295 ADAS_LA_sens_Feed "Sensitivity Feedback";
CM_ SG_ 295 ADAS_LDW_check "Lane Departure Warning Check";
CM_ SG_ 295 ADAS_LKA_check "Lans Keeping Assist Check";
CM_ SG_ 295 ADAS_LA_Mode_Feed "Feedback of LA mode select (From MHU setting)";
CM_ BO_ 296 "ADAS Forward Collision and Rear Cross Traffic Alert  Warning";
CM_ SG_ 296 CHKSM_ADAS_FCW_RCTA "Checksum";
CM_ SG_ 296 ALV_ADAS_FCW_RCTA "Alive Counter";
CM_ SG_ 296 ADAS_IA_check "Intersection Assist State Check";
CM_ SG_ 296 ADAS_RCTA_IndLeft "Left Rear Cross Traffic Alert (RCTA) System Warning";
CM_ SG_ 296 ADAS_RCTA_IndRight "Right Rear Cross Traffic Alert (RCTA) System Warning ";
CM_ SG_ 296 ADAS_IA_Left_warning "Intersecion assist left warning";
CM_ SG_ 296 ADAS_FCW_state "Forward Collision Warning State";
CM_ SG_ 296 ADAS_IA_state "Intersection Assist State";
CM_ SG_ 296 ADAS_FCW_check "Forward Collision Warning Check";
CM_ SG_ 296 ADAS_IA_Right_warning "Intersecion assist right warning";
CM_ SG_ 296 ADAS_IA_Mode_Feed "Intersection Assist State  Mode select";
CM_ SG_ 296 ADAS_FCW_warning "Forward Collision Warning Warning popup";
CM_ BO_ 303 "BCM Terminal for vehicle";
CM_ SG_ 303 CHKSM_BCM_TERMINAL "Checksum";
CM_ SG_ 303 ALV_BCM_TERMINAL "Alive counter";
CM_ SG_ 303 ST_KL "Clamp status";
CM_ SG_ 303 ST_KL_KEY_VLD "Key valid";
CM_ SG_ 303 STAT_AlcoholEngineStatus "AlcoholEngineStatus ON/OFF ";
CM_ SG_ 303 ST_STCD_PENG "Plausibility signal for starter release";
CM_ SG_ 303 ST_SSB "Status of Start Stop Button";
CM_ SG_ 303 RWDT_BLS "Raw data Brake light switch";
CM_ SG_ 303 RQ_DRVG_RDI "Engine start advice (will be send out before the engine start)";
CM_ BO_ 306 "ADAS Blind Sport Detection";
CM_ SG_ 306 Checksum_0x132 "Checksum";
CM_ SG_ 306 Rolling_Counter_0x132 "Rolling_Counter";
CM_ SG_ 306 SRR_BSD_AudChime_Feed "Blind Sport Detection Audible Chime Feedback";
CM_ SG_ 306 SRR_BSD_check "Blind Sport Detection Check";
CM_ SG_ 306 SRR_BSD_state "Blind Sport Detection State Feedback";
CM_ SG_ 306 SRR_BSD_IndLeft "Left Blind Sport Detection Warning";
CM_ SG_ 306 SRR_BSD_IndRight "Right Blind Sport Detection Warning";
CM_ SG_ 306 SRR_BSD_SndWarn "Rear Blind Sport Detection warning sound en disable";
CM_ SG_ 306 SRR_BSD_Mode_Feed "Blind Sport Detection On Off Feedback";
CM_ BO_ 307 "ADAS Blind Sport Detection";
CM_ SG_ 307 ADAS_BSD_IndLeft "Left Blind Sport Detection Warning";
CM_ SG_ 307 ADAS_BSD_IndRight "Right Blind Sport Detection Warning";
CM_ SG_ 303 STAT_AlcoholIgnStatus "AlcoholIgnStatus ON/OFF ";
CM_ SG_ 303 CTR_ENG_STOP "This signal allows the engine to be switched off without removing the ignition (KL15). ";
CM_ SG_ 303 ST_VEH_CON "The signal is formed from the current klemme state, the engine running status and the vehicle movement. It also shows whether the vehicle is in washline mode. Attention: This signal only evaluates the condition of the internal combustion engine.";
CM_ SG_ 314 FCAM_ESA_Sts "The signal indicates the status of ESA function Off  passive, standby,active etc.";
CM_ BO_ 359 "VCU_TWV1_FRM";
CM_ SG_ 359 TWV1_N_Position "TWV1_N_Position";
CM_ SG_ 359 TWV1_St_Feedback "TWV1_St_Feedback";
CM_ SG_ 359 TWV1_Frm_Error "TWV1_Frm_Error";
CM_ BO_ 360 "MHU and T-Box Feedback signals";
CM_ SG_ 360 Checksum_MHU_FEEDBACK_APA "Checksum";
CM_ SG_ 360 Rolling_Counter_MHU_FEEDBACK_APA "Roling counter";
CM_ SG_ 360 MHU_AVM_ShowAVMReq "request AVM Active";
CM_ BO_ 376 "YSS_LongAcc";
CM_ SG_ 376 CHKSM_YSS_LongAcc "Checksum";
CM_ SG_ 376 ALV_YSS_LongAcc "Alive Counter";
CM_ SG_ 376 YSS_LONG_ACCUNFILTERED_QUAL "This signal contains the physical value of the Longitudinal acceleration with 0.002m/s2 LSB.";
CM_ SG_ 376 YSS_LONG_ACC_UNFILTERED "This signal contains the physical value of the Longitudinal acceleration with 0.002m/s2 LSB.";
CM_ SG_ 376 YSS_LONG_ACC_QUAL "This signal contains the qualifier of the Longitudinal acceleration.";
CM_ SG_ 376 YSS_LONG_ACC "This signal contains the physical value of the Longitudinal acceleration with 0.002m/s2 LSB.";
CM_ BO_ 381 "YSS_YawRate";
CM_ SG_ 381 CHKSM_YSS_YawRate "Checksum";
CM_ SG_ 381 ALV_YSS_YawRate "Alive Counter";
CM_ SG_ 381 YSS_YAW_RATEUNFILTERED_QUAL "This signal contains the qualifier of the Yaw rate. ";
CM_ SG_ 381 YSS_YAW_RATE_UNFILTERED "This signal contains the physical value of the Yaw rate with 0.005�/s LSB.";
CM_ SG_ 381 YSS_YAW_RATE_QUAL "This signal contains the qualifier of the Yaw rate. ";
CM_ SG_ 381 YSS_SC_STATUS "This signal contains the state information for the SC. Each state has different priority, therefore the SC can have only one state at the same time.";
CM_ SG_ 381 YSS_YAW_RATE "This signal contains the physical value of the Yaw rate with 0.005�/s LSB. Table 2 contains some hexadecimal values with special meaning (e.g. initialization). The Yaw rate signal can have values from -163.830�/s (0x0000) to +163.830�/s (0xFFFC). The 0�/s value is assigned to (0x7FFE).";
CM_ SG_ 381 YSS_TEMPERATURE "This signal contains the physical value of the Temperature with 1�C LSB. Table 2 contains hexadecimal values with special meaning (e.g. initialization). The TEMPERATURE signal has no separate qualifier signal.";
CM_ BO_ 382 "Steering angle sensor";
CM_ SG_ 382 CHKSM_SAS_Sensor "Checksum";
CM_ SG_ 382 ALV_SAS_Sensor "Alive Counter";
CM_ SG_ 382 SAS_SASStsSnsr "The flag of  SAS status Punch Steering angle status";
CM_ SG_ 382 SAS_SteerWhlRotSpd "The current rotation speed of the steering wheel.";
CM_ SG_ 382 SAS_SteerWhlRotSpdStatus "The status of SteerWheelRotSpd";
CM_ SG_ 382 SAS_SASFailure "Angle sensor disabled.";
CM_ SG_ 382 SAS_Calibrated "SAS calibration state";
CM_ SG_ 382 SAS_SteerWheelAngleValid "Effective signal for steering angle";
CM_ SG_ 382 SAS_SteerWheelAngle "The current angle of the steering wheel(Positive, to left; Negative, to right)";
CM_ BO_ 385 "CAM_Status";
CM_ SG_ 385 CAM_CamSts "Camera Status ";
CM_ SG_ 385 CAM_AmbLi "Ambient brightness";
CM_ SG_ 385 CAM_RoadIllmn "Road lamp detection";
CM_ SG_ 385 CAM_Obj_TrfcStyle "Traffic type ";
CM_ SG_ 388 CHKSM_FCAM_BCM_Status "Checksum";
CM_ SG_ 388 ALIVE_FCAM_BCM_Status "Alive counter";
CM_ SG_ 388 FCAM_BCM_IndicatorlightReq "FCAM request BCM to light up these light";
CM_ SG_ 388 SECCAN_FCAM_BCM_Sts "Seed generated from Secure CAN algorithm";
CM_ BO_ 401 "CAM Obj 1";
CM_ SG_ 401 CAM_Obj1_ID "ID of object 1
Light object ID. Range is 1-255, while 0 indicates that the field in unfilled.";
CM_ SG_ 401 CAM_Obj1_HozlDst "Horizontal distance in X axis direction  of object 1
0x000-0x1FE: valid
0x1FF: NotAvailable";
CM_ SG_ 401 CAM_Obj1_Valid "Valid of object 1";
CM_ SG_ 401 CAM_Obj1_HozlPosnRi "Horizontal right edge of object 1
0x000-0x3E8: valid
0x3E9-0x3FD: Reserved
0x3FF: NotAvailable";
CM_ SG_ 401 CAM_Obj1_Typ "Type of object 1";
CM_ SG_ 401 CAM_Obj1_HozlPosnLe "Horizontal left edge of object 1
0x000-0x3E8: valid
0x3E9-0x3FD: Reserved
0x3FF: NotAvailable";
CM_ SG_ 401 CAM_Obj1_VertPosn "Vertical lower boundary of object 1
-10 to 10 degree";
CM_ SG_ 401 CAM_Obj1_HozlSpdLe "Horizontal angular velocity of left edge of object 1 (Left��negative and Right positive )
";
CM_ SG_ 401 CAM_Obj1_HozlSpdRi "Horizontal angular velocity of right edge of object 1 (Left��negative and Right positive )
";
CM_ BO_ 404 "CAM_Obj2";
CM_ SG_ 404 CAM_Obj2_ID "ID of object 2
Light object ID. Range is 1-255, while 0 indicates that the field in unfilled.";
CM_ SG_ 404 CAM_Obj2_HozlDst "Horizontal distance in X axis direction  of object 2
0x000-0x1FE: valid
0x1FF: NotAvailable";
CM_ SG_ 404 CAM_Obj2_Valid "Valid of object 2";
CM_ SG_ 404 CAM_Obj2_HozlPosnRi "Horizontal right edge of object 2
0x000-0x3E8: valid
0x3E9-0x3FD: Reserved
0x3FF: NotAvailable";
CM_ SG_ 404 CAM_Obj2_Typ "Type of object 2";
CM_ SG_ 404 CAM_Obj2_HozlPosnLe "Horizontal left edge of object 2
0x000-0x3E8: valid
0x3E9-0x3FD: Reserved
0x3FF: NotAvailable";
CM_ SG_ 404 CAM_Obj2_VertPosn "Vertical lower boundary of object  2
-10 to 10 degree";
CM_ SG_ 404 CAM_Obj2_HozlSpdLe "Horizontal angular velocity of left edge of object 2 (Left��negative and Right positive )
";
CM_ SG_ 404 CAM_Obj2_HozlSpdRi "Horizontal angular velocity of right edge of object 2 (Left��negative and Right positive )
";
CM_ BO_ 406 "CAM_Obj3";
CM_ SG_ 406 CAM_Obj3_ID "ID of object 3
Light object ID. Range is 1-255, while 0 indicates that the field in unfilled.";
CM_ SG_ 406 CAM_Obj3_HozlDst "Horizontal distance in X axis direction  of object 3
0x000-0x1FE: valid
0x1FF: NotAvailable";
CM_ SG_ 406 CAM_Obj3_Valid "Valid of object 3";
CM_ SG_ 406 CAM_Obj3_HozlPosnRi "Horizontal right edge of object 3
0x000-0x3E8: valid
0x3E9-0x3FD: Reserved
0x3FF: NotAvailable";
CM_ SG_ 406 CAM_Obj3_Typ "Type of object 3";
CM_ SG_ 406 CAM_Obj3_HozlPosnLe "Horizontal left edge of object 3
0x000-0x3E8: valid
0x3E9-0x3FD: Reserved
0x3FF: NotAvailable";
CM_ SG_ 406 CAM_Obj3_VertPosn "Vertical lower boundary of object  3
-10 to 10 degree";
CM_ SG_ 406 CAM_Obj3_HozlSpdLe "Horizontal angular velocity of left edge of object 3 (Left��negative and Right positive )
";
CM_ SG_ 406 CAM_Obj3_HozlSpdRi "Horizontal angular velocity of right edge of object 3 (Left��negative and Right positive )
";
CM_ BO_ 410 "CAM_Obj4";
CM_ SG_ 410 CAM_Obj4_ID "ID of object 4
Light object ID. Range is 1-255, while 0 indicates that the field in unfilled.";
CM_ SG_ 410 CAM_Obj4_HozlDst "Horizontal distance in X axis direction  of object 4
0x000-0x1FE: valid
0x1FF: NotAvailable";
CM_ SG_ 410 CAM_Obj4_Valid "Valid of object 4";
CM_ SG_ 410 CAM_Obj4_HozlPosnRi "Horizontal right edge of object 4
0x000-0x3E8: valid
0x3E9-0x3FD: Reserved
0x3FF: NotAvailable";
CM_ SG_ 410 CAM_Obj4_Typ "Type of object 4";
CM_ SG_ 410 CAM_Obj4_HozlPosnLe "Horizontal left edge of object 4
0x000-0x3E8: valid
0x3E9-0x3FD: Reserved
0x3FF: NotAvailable";
CM_ SG_ 410 CAM_Obj4_VertPosn "Vertical lower boundary of object  4
-10 to 10 degree";
CM_ SG_ 410 CAM_Obj4_HozlSpdLe "Horizontal angular velocity of left edge of object 4 (Left��negative and Right positive )
";
CM_ SG_ 410 CAM_Obj4_HozlSpdRi "Horizontal angular velocity of right edge of object 4 (Left��negative and Right positive )
";
CM_ BO_ 412 "CAM_Obj5";
CM_ SG_ 412 CAM_Obj5_ID "ID of object 5
Light object ID. Range is 1-255, while 0 indicates that the field in unfilled.";
CM_ SG_ 412 CAM_Obj5_HozlDst "Horizontal distance in X axis direction  of object 5
0x000-0x1FE: valid
0x1FF: NotAvailable";
CM_ SG_ 412 CAM_Obj5_Valid "Valid of object 5";
CM_ SG_ 412 CAM_Obj5_HozlPosnRi "Horizontal right edge of object 5
0x000-0x3E8: valid
0x3E9-0x3FD: Reserved
0x3FF: NotAvailable";
CM_ SG_ 412 CAM_Obj5_Typ "Type of object 5";
CM_ SG_ 412 CAM_Obj5_HozlPosnLe "Horizontal left edge of object 5
0x000-0x3E8: valid
0x3E9-0x3FD: Reserved
0x3FF: NotAvailable";
CM_ SG_ 412 CAM_Obj5_VertPosn "Vertical lower boundary of object  5
-10 to 10 degree";
CM_ SG_ 412 CAM_Obj5_HozlSpdLe "Horizontal angular velocity of left edge of object 5 (Left��negative and Right positive )
";
CM_ SG_ 412 CAM_Obj5_HozlSpdRi "Horizontal angular velocity of right edge of object 5 (Left��negative and Right positive )
";
CM_ BO_ 413 "CAM_Obj6";
CM_ SG_ 413 CAM_Obj6_ID "ID of object 6
Light object ID. Range is 1-255, while 0 indicates that the field in unfilled.";
CM_ SG_ 413 CAM_Obj6_HozlDst "Horizontal distance in X axis direction  of object 6
0x000-0x1FE: valid
0x1FF: NotAvailable";
CM_ SG_ 413 CAM_Obj6_Valid "Valid of object 6";
CM_ SG_ 413 CAM_Obj6_HozlPosnRi "Horizontal right edge of object 6
0x000-0x3E8: valid
0x3E9-0x3FD: Reserved
0x3FF: NotAvailable";
CM_ SG_ 413 CAM_Obj6_Typ "Type of object 6";
CM_ SG_ 413 CAM_Obj6_HozlPosnLe "Horizontal left edge of object 6
0x000-0x3E8: valid
0x3E9-0x3FD: Reserved
0x3FF: NotAvailable";
CM_ SG_ 413 CAM_Obj6_VertPosn "Vertical lower boundary of object  6
-10 to 10 degree";
CM_ SG_ 413 CAM_Obj6_HozlSpdLe "Horizontal angular velocity of left edge of object 6 (Left��negative and Right positive )
";
CM_ SG_ 413 CAM_Obj6_HozlSpdRi "Horizontal angular velocity of right edge of object 6 (Left��negative and Right positive )
";
CM_ BO_ 414 "CAM_Obj7";
CM_ SG_ 414 CAM_Obj7_ID "ID of object 7
Light object ID. Range is 1-255, while 0 indicates that the field in unfilled.";
CM_ SG_ 414 CAM_Obj7_HozlDst "Horizontal distance in X axis direction  of object 7
0x000-0x1FE: valid
0x1FF: NotAvailable";
CM_ SG_ 414 CAM_Obj7_Valid "Valid of object 7";
CM_ SG_ 414 CAM_Obj7_HozlPosnRi "Horizontal right edge of object 7
0x000-0x3E8: valid
0x3E9-0x3FD: Reserved
0x3FF: NotAvailable";
CM_ SG_ 414 CAM_Obj7_Typ "Type of object 7";
CM_ SG_ 414 CAM_Obj7_HozlPosnLe "Horizontal left edge of object 7
0x000-0x3E8: valid
0x3E9-0x3FD: Reserved
0x3FF: NotAvailable";
CM_ SG_ 414 CAM_Obj7_VertPosn "Vertical lower boundary of object  7
-10 to 10 degree";
CM_ SG_ 414 CAM_Obj7_HozlSpdLe "Horizontal angular velocity of left edge of object 7 (Left��negative and Right positive )
";
CM_ SG_ 414 CAM_Obj7_HozlSpdRi "Horizontal angular velocity of right edge of object 7 (Left��negative and Right positive )
";
CM_ BO_ 415 "CAM_Obj8";
CM_ SG_ 415 CAM_Obj8_ID "ID of object 8 Light object ID. Range is 1-255, while 0 indicates that the field in unfilled.";
CM_ SG_ 415 CAM_Obj8_HozlDst "Horizontal distance in X axis direction  of object 8
0x000-0x1FE: valid
0x1FF: NotAvailable";
CM_ SG_ 415 CAM_Obj8_Valid "Valid of object 8";
CM_ SG_ 415 CAM_Obj8_HozlPosnRi "Horizontal right edge of object 8
0x000-0x3E8: valid
0x3E9-0x3FD: Reserved
0x3FF: NotAvailable";
CM_ SG_ 415 CAM_Obj8_Typ "Type of object 8";
CM_ SG_ 415 CAM_Obj8_HozlPosnLe "Horizontal left edge of object 8
0x000-0x3E8: valid
0x3E9-0x3FD: Reserved
0x3FF: NotAvailable";
CM_ SG_ 415 CAM_Obj8_VertPosn "Vertical lower boundary of object 8 -10 to 10 degree";
CM_ SG_ 415 CAM_Obj8_HozlSpdLe "Horizontal angular velocity of left edge of object 8 (Left��negative and Right positive )";
CM_ SG_ 415 CAM_Obj8_HozlSpdRi "Horizontal angular velocity of right edge of object 8 (Left��negative and Right positive )";
CM_ BO_ 417 "Vehicle speed";
CM_ SG_ 417 CHSKM_V_VEH "Checksum";
CM_ SG_ 417 ALIV_V_VEH "Alive counter";
CM_ SG_ 417 V_VEH_COG "Vehicle speed for powertrain";
CM_ SG_ 417 DVCO_VEH "Driving condition";
CM_ SG_ 417 QU_V_VEH_COG "Vehicle speed valid";
CM_ BO_ 504 "MCU OutPut FR";
CM_ SG_ 504 CHKSM_EDS_OutPut_FR "Check sum";
CM_ SG_ 504 ALV_EDS_OutPut_FR "Alive Counter";
CM_ SG_ 504 EDS_Work_STS_FR "EDS Work status ";
CM_ SG_ 504 EDS_Spd_FR "Current motor speed";
CM_ SG_ 504 EDS_output_trqValid_FR "Indicate the valid flag of current motor torque";
CM_ SG_ 504 EDS_MotorDriveSts_FR "The drive state of EDS";
CM_ SG_ 504 EDS_powoff_req_FR "If there is a serious failure in the running process of EDS, the high voltage of VCU will be requested ";
CM_ SG_ 504 EDS_SpdValid_FR "Indicate the valid flag of current motor speed";
CM_ SG_ 504 EDS_output_trq_FR "Actual output torque of current EDS";
CM_ SG_ 504 EDS_VCU_6SO_flag_FWD "Indicate the valid flag of current front motor 6SO possible";
CM_ BO_ 505 "MCU OutPut RR";
CM_ SG_ 505 CHKSM_EDS_OutPut_RR "Check sum";
CM_ SG_ 505 ALV_EDS_OutPut_RR "Alive Counter";
CM_ SG_ 505 EDS_Work_STS_RR "Rear EDS Work status ";
CM_ SG_ 505 EDS_Spd_RR "current rear motor speed";
CM_ SG_ 505 EDS_output_trqValid_RR "Indicate the valid flag of current rear motor torque";
CM_ SG_ 505 EDS_MotorDriveSts_RR "The drive state of rear EDS";
CM_ SG_ 505 EDS_powoff_req_RR " If there is a serious failure in the running process of rear EDS, the high voltage of VCU will be requested ";
CM_ SG_ 505 EDS_SpdValid_RR "Indicate the valid flag of current rear motor speed";
CM_ SG_ 505 EDS_output_trq_RR "Actual output torque of current Rear motor ";
CM_ SG_ 505 EDS_VCU_6SO_flag_RWD "Indicate the valid flag of current rear motor 6SO possible";
CM_ BO_ 519 "Sunroof status";
CM_ SG_ 519 SR_Undervoltage_Fault_Sts "Sunroof under voltage status";
CM_ SG_ 519 SR_Overvoltage_Fault_Sts "Sunroof over voltage ";
CM_ SG_ 519 SR_SLEEP_RQ "Sunroof sleep request";
CM_ SG_ 519 SR_Position "Sunroof position";
CM_ SG_ 519 SR_Motor_Running_Sts "Sunroof motor running status";
CM_ SG_ 519 SR_MotorReverse_Fault_Sts "Sunroof motor reverse status";
CM_ SG_ 519 SR_Hall_Fault_Sts "SR Hall Fault Sts";
CM_ SG_ 519 SR_Normalisation_Sts "SR Normalisation Sts";
CM_ SG_ 519 SR_Relay_Fault "SR Relay Fault";
CM_ SG_ 519 SR_Commu_Fault_Sts "Sunroof comminication status";
CM_ SG_ 519 SR_Initialisation_Status "SR_Initialisation_Status";
CM_ SG_ 519 SR_Ctrl_Result "Sunroof control result";
CM_ SG_ 519 SR_ThermalProtection_Fault_Sts "Sunroof thermal protection status";
CM_ SG_ 519 SR_Posit_Percentage "Sunroof position in percentage";
CM_ SG_ 519 SR_Operation_Stat "Sunroof operating state ";
CM_ SG_ 519 SR_Error_RSP "Sunroof error";
CM_ SG_ 519 BCM_AutoSunroof_Sts "Auto Sunroof setting feedback";
CM_ BO_ 520 "Sunshade status";
CM_ SG_ 520 SS_MotorReverse_Fault_Status "Sunshade MotorReverse Fault Status";
CM_ SG_ 520 SS_Motor_Running_Status "Sunshade Motor Running Status";
CM_ SG_ 520 SS_Position "Sunshade Position";
CM_ SG_ 520 SS_SLEEP_RQ "Sunshade SLEEP RQ";
CM_ SG_ 520 SS_Undervoltage_Fault_Status "Sunshade Undervoltage Fault Status";
CM_ SG_ 520 SS_Ctrl_Result "Sunshade Ctrl Result";
CM_ SG_ 520 SS_Overvoltage_Fault_Status "Sunshade Overvoltage Fault Status";
CM_ SG_ 520 SS_Relay_Fault "SS_Relay_Fault";
CM_ SG_ 520 SS_Normalisation_Status "SS_Normalisation_Status";
CM_ SG_ 520 SS_Hall_Fault_Status "Sunshade Driver Fault Status";
CM_ SG_ 520 SS_Commu_Fault_Status "Sunshade Commu Fault Status";
CM_ SG_ 520 SS_Initialisation_Status "SS_Initialisation_Status";
CM_ SG_ 520 SS_Posit_Percentage "Sunshade Posit Percentage";
CM_ SG_ 520 SS_ThermalProtection_Flt_Sts "Sunshade ThermalProtection Fault Status";
CM_ SG_ 520 SS_Operation_State "Sunshade Operation State";
CM_ SG_ 520 SECCAN_SunshadeSts "Secret portion from Secure CAN algorithm";
CM_ SG_ 520 SS_Error_RSP "Sunshade Error RSP";
BA_DEF_ BO_  "GenMsgSendType" ENUM  "Cyclic","NotUsed","NotUsed","NotUsed","NotUsed","NotUsed","NotUsed","IfActive","NoMsgSendType","NotUsed";
BA_DEF_ BO_  "GenMsgILSupport" ENUM  "No","Yes";
BA_DEF_ BO_  "DiagResponse" ENUM  "No","Yes";
BA_DEF_ BO_  "DiagRequest" ENUM  "No","Yes";
BA_DEF_ BO_  "NmAsrMessage" ENUM  "No","Yes";
BA_DEF_ BO_  "DiagState" ENUM  "No","Yes";
BA_DEF_ BO_  "DiagUudtResponse" ENUM  "False","True";
BA_DEF_ BO_  "GenMsgStartDelayTime" INT 0 65535;
BA_DEF_ BO_  "GenMsgDelayTime" INT 0 0;
BA_DEF_ BO_  "GenMsgNrOfRepetition" INT 0 0;
BA_DEF_ BO_  "GenMsgCycleTimeFast" INT 0 0;
BA_DEF_ BO_  "GenMsgCycleTime" INT 0 0;
BA_DEF_ BU_  "NmStationAddress" HEX 0 0;
BA_DEF_ BU_  "Address" HEX 0 255;
BA_DEF_ BU_  "TpSTMin" INT 0 255;
BA_DEF_ BU_  "ILUsed" ENUM  "No","Yes";
BA_DEF_ BU_  "NmAsrNode" ENUM  "No","Yes";
BA_DEF_ BU_  "NmAsrNodeIdentifier" HEX 0 255;
BA_DEF_ BU_  "NmAsrCanMsgCycleOffset" INT 0 65535;
BA_DEF_ BU_  "NmAsrCanMsgReducedTime" INT 320 640;
BA_DEF_ SG_  "GenSigSendType" ENUM  "Cyclic","OnWrite","OnWriteWithRepetition","OnChange","OnChangeWithRepetition","IfActive","IfActiveWithRepetition","NoSigSendType","NotUsed","NotUsed","NotUsed","NotUsed","NotUsed";
BA_DEF_ SG_  "InvalidValue" STRING ;
BA_DEF_ SG_  "GenSigStartValue" INT 0 0;
BA_DEF_ SG_  "GenSigTimeoutTime_ALL" INT 0 65535;
BA_DEF_  "DBName" STRING ;
BA_DEF_  "NmAsrBaseAddress" HEX 0 2047;
BA_DEF_  "NmAsrMessageCount" INT 1 256;
BA_DEF_  "NmAsrTimeoutTime" INT 0 65535;
BA_DEF_  "NmAsrWaitBusSleepTime" INT 0 65535;
BA_DEF_  "NmAsrRepeatMessageTime" INT 0 65535;
BA_DEF_  "NmAsrCanMsgCycleTime" INT 0 65535;
BA_DEF_  "Baudrate" INT 0 1000000;
BA_DEF_  "BusType" STRING ;
BA_DEF_  "NmType" STRING ;
BA_DEF_  "Manufacturer" STRING ;
BA_DEF_ BU_  "ECU" STRING ;
BA_DEF_DEF_  "GenMsgSendType" "NoMsgSendType";
BA_DEF_DEF_  "GenMsgILSupport" "Yes";
BA_DEF_DEF_  "DiagResponse" "No";
BA_DEF_DEF_  "DiagRequest" "No";
BA_DEF_DEF_  "NmAsrMessage" "No";
BA_DEF_DEF_  "DiagState" "No";
BA_DEF_DEF_  "DiagUudtResponse" "False";
BA_DEF_DEF_  "GenMsgStartDelayTime" 0;
BA_DEF_DEF_  "GenMsgDelayTime" 0;
BA_DEF_DEF_  "GenMsgNrOfRepetition" 0;
BA_DEF_DEF_  "GenMsgCycleTimeFast" 0;
BA_DEF_DEF_  "GenMsgCycleTime" 0;
BA_DEF_DEF_  "NmStationAddress" 0;
BA_DEF_DEF_  "Address" 0;
BA_DEF_DEF_  "TpSTMin" 20;
BA_DEF_DEF_  "ILUsed" "Yes";
BA_DEF_DEF_  "NmAsrNode" "Yes";
BA_DEF_DEF_  "NmAsrNodeIdentifier" 0;
BA_DEF_DEF_  "NmAsrCanMsgCycleOffset" 0;
BA_DEF_DEF_  "NmAsrCanMsgReducedTime" 320;
BA_DEF_DEF_  "GenSigSendType" "Cyclic";
BA_DEF_DEF_  "InvalidValue" "";
BA_DEF_DEF_  "GenSigStartValue" 0;
BA_DEF_DEF_  "GenSigTimeoutTime_ALL" 0;
BA_DEF_DEF_  "DBName" "";
BA_DEF_DEF_  "NmAsrBaseAddress" 1280;
BA_DEF_DEF_  "NmAsrMessageCount" 128;
BA_DEF_DEF_  "NmAsrTimeoutTime" 2000;
BA_DEF_DEF_  "NmAsrWaitBusSleepTime" 1500;
BA_DEF_DEF_  "NmAsrRepeatMessageTime" 3200;
BA_DEF_DEF_  "NmAsrCanMsgCycleTime" 640;
BA_DEF_DEF_  "Baudrate" 500000;
BA_DEF_DEF_  "BusType" "";
BA_DEF_DEF_  "NmType" "";
BA_DEF_DEF_  "Manufacturer" "VinFast";
BA_DEF_DEF_  "ECU" "";
BA_ "BusType" "CAN";
BA_ "NmType" "NmAsr";
BA_ "DBName" "Body";
BA_ "Address" BU_ ACM 8;
BA_ "ECU" BU_ ACM "ACM";
BA_ "NmAsrCanMsgCycleOffset" BU_ ACM 40;
BA_ "NmAsrCanMsgReducedTime" BU_ ACM 340;
BA_ "NmAsrNodeIdentifier" BU_ ACM 8;
BA_ "NmStationAddress" BU_ ACM 8;
BA_ "Address" BU_ SRR_RR_M 57;
BA_ "ECU" BU_ SRR_RR_M "SRR_RR_M";
BA_ "NmAsrCanMsgCycleOffset" BU_ SRR_RR_M 285;
BA_ "NmAsrNodeIdentifier" BU_ SRR_RR_M 57;
BA_ "NmStationAddress" BU_ SRR_RR_M 57;
BA_ "Address" BU_ ADAS_Body 64;
BA_ "ECU" BU_ ADAS_Body "ADAS_BodyCAN";
BA_ "NmAsrCanMsgCycleOffset" BU_ ADAS_Body 320;
BA_ "NmAsrCanMsgReducedTime" BU_ ADAS_Body 480;
BA_ "NmAsrNode" BU_ ADAS_Body 0;
BA_ "NmAsrNodeIdentifier" BU_ ADAS_Body 64;
BA_ "NmStationAddress" BU_ ADAS_Body 64;
BA_ "Address" BU_ APM 65;
BA_ "ECU" BU_ APM "APM";
BA_ "NmAsrCanMsgCycleOffset" BU_ APM 325;
BA_ "NmAsrNodeIdentifier" BU_ APM 65;
BA_ "NmStationAddress" BU_ APM 65;
BA_ "Address" BU_ ASU_Gateway 28;
BA_ "ECU" BU_ ASU_Gateway "ASU";
BA_ "NmAsrNodeIdentifier" BU_ ASU_Gateway 17;
BA_ "NmStationAddress" BU_ ASU_Gateway 17;
BA_ "Address" BU_ BCM 1;
BA_ "ECU" BU_ BCM "Body_CAN_BCM";
BA_ "NmAsrCanMsgCycleOffset" BU_ BCM 5;
BA_ "NmAsrNodeIdentifier" BU_ BCM 1;
BA_ "NmStationAddress" BU_ BCM 1;
BA_ "Address" BU_ BCM_BPM 123;
BA_ "ECU" BU_ BCM_BPM "BCM_BPM";
BA_ "NmAsrCanMsgCycleOffset" BU_ BCM_BPM 485;
BA_ "NmStationAddress" BU_ BCM_BPM 123;
BA_ "Address" BU_ CCU_F 9;
BA_ "ECU" BU_ CCU_F "CCU_F";
BA_ "NmAsrCanMsgCycleOffset" BU_ CCU_F 45;
BA_ "NmAsrNodeIdentifier" BU_ CCU_F 9;
BA_ "NmStationAddress" BU_ CCU_F 9;
BA_ "Address" BU_ CCU_R 20;
BA_ "ECU" BU_ CCU_R "CCU_R";
BA_ "NmAsrCanMsgCycleOffset" BU_ CCU_R 70;
BA_ "NmAsrCanMsgReducedTime" BU_ CCU_R 355;
BA_ "NmAsrNodeIdentifier" BU_ CCU_R 20;
BA_ "NmStationAddress" BU_ CCU_R 20;
BA_ "ECU" BU_ DUMMY_BCM_BPM "DUMMY_BCM_BPM";
BA_ "Address" BU_ ETG 14;
BA_ "ECU" BU_ ETG "ETG";
BA_ "NmAsrCanMsgCycleOffset" BU_ ETG 70;
BA_ "NmAsrCanMsgReducedTime" BU_ ETG 355;
BA_ "NmAsrNodeIdentifier" BU_ ETG 14;
BA_ "NmStationAddress" BU_ ETG 14;
BA_ "Address" BU_ LDM_L 73;
BA_ "ECU" BU_ LDM_L "LDM_L";
BA_ "NmAsrCanMsgCycleOffset" BU_ LDM_L 365;
BA_ "NmAsrCanMsgReducedTime" BU_ LDM_L 503;
BA_ "NmAsrNodeIdentifier" BU_ LDM_L 73;
BA_ "NmStationAddress" BU_ LDM_L 73;
BA_ "Address" BU_ LDM_R 74;
BA_ "ECU" BU_ LDM_R "LDM_R";
BA_ "NmAsrCanMsgCycleOffset" BU_ LDM_R 370;
BA_ "NmAsrCanMsgReducedTime" BU_ LDM_R 505;
BA_ "NmAsrNodeIdentifier" BU_ LDM_R 74;
BA_ "NmStationAddress" BU_ LDM_R 74;
BA_ "Address" BU_ OCS_P 68;
BA_ "ECU" BU_ OCS_P "OCS_P";
BA_ "NmAsrCanMsgCycleOffset" BU_ OCS_P 340;
BA_ "NmAsrCanMsgReducedTime" BU_ OCS_P 490;
BA_ "NmAsrNodeIdentifier" BU_ OCS_P 68;
BA_ "NmStationAddress" BU_ OCS_P 68;
BA_ "Address" BU_ PSM_D 30;
BA_ "ECU" BU_ PSM_D "PSM_D";
BA_ "NmAsrCanMsgCycleOffset" BU_ PSM_D 150;
BA_ "NmAsrCanMsgReducedTime" BU_ PSM_D 395;
BA_ "NmAsrNodeIdentifier" BU_ PSM_D 30;
BA_ "NmStationAddress" BU_ PSM_D 30;
BA_ "Address" BU_ SHVU_F 66;
BA_ "ECU" BU_ SHVU_F "SHVU_F";
BA_ "NmAsrCanMsgCycleOffset" BU_ SHVU_F 330;
BA_ "NmAsrCanMsgReducedTime" BU_ SHVU_F 485;
BA_ "NmAsrNodeIdentifier" BU_ SHVU_F 66;
BA_ "NmStationAddress" BU_ SHVU_F 66;
BA_ "Address" BU_ SHVU_R 67;
BA_ "ECU" BU_ SHVU_R "SHVU_R";
BA_ "NmAsrCanMsgCycleOffset" BU_ SHVU_R 335;
BA_ "NmAsrNodeIdentifier" BU_ SHVU_R 67;
BA_ "NmStationAddress" BU_ SHVU_R 67;
BA_ "Address" BU_ TRM 59;
BA_ "ECU" BU_ TRM "TRM";
BA_ "NmAsrCanMsgCycleOffset" BU_ TRM 295;
BA_ "NmAsrNodeIdentifier" BU_ TRM 59;
BA_ "NmStationAddress" BU_ TRM 59;
BA_ "NmAsrCanMsgCycleOffset" BU_ USS_R 250;
BA_ "Address" BU_ USS_F 50;
BA_ "ECU" BU_ USS_F "USS_F";
BA_ "NmAsrNodeIdentifier" BU_ USS_F 50;
BA_ "NmStationAddress" BU_ USS_F 50;
BA_ "NmAsrCanMsgCycleOffset" BU_ USS_R 245;
BA_ "Address" BU_ USS_R 49;
BA_ "ECU" BU_ USS_F "USS_F";
BA_ "NmAsrNodeIdentifier" BU_ USS_R 49;
BA_ "NmStationAddress" BU_ USS_R 49;
BA_ "Address" BU_ XGW_Body 2;
BA_ "ECU" BU_ XGW_Body "XGW_BodyCAN";
BA_ "NmAsrCanMsgCycleOffset" BU_ XGW_Body 10;
BA_ "NmAsrCanMsgReducedTime" BU_ XGW_Body 325;
BA_ "NmAsrNodeIdentifier" BU_ XGW_Body 2;
BA_ "NmStationAddress" BU_ XGW_Body 2;
BA_ "GenMsgCycleTime" BO_ 133 20;
BA_ "GenMsgSendType" BO_ 133 0;
BA_ "GenMsgCycleTime" BO_ 149 100;
BA_ "GenMsgSendType" BO_ 149 0;
BA_ "GenMsgCycleTime" BO_ 217 20;
BA_ "GenMsgSendType" BO_ 217 0;
BA_ "GenMsgCycleTime" BO_ 256 1000;
BA_ "GenMsgSendType" BO_ 256 0;
BA_ "GenMsgCycleTime" BO_ 258 100;
BA_ "GenMsgSendType" BO_ 258 0;
BA_ "GenMsgCycleTime" BO_ 259 1000;
BA_ "GenMsgSendType" BO_ 259 0;
BA_ "GenMsgCycleTime" BO_ 260 100;
BA_ "GenMsgSendType" BO_ 260 0;
BA_ "GenMsgCycleTime" BO_ 261 100;
BA_ "GenMsgSendType" BO_ 261 0;
BA_ "GenMsgCycleTime" BO_ 262 100;
BA_ "GenMsgSendType" BO_ 262 0;
BA_ "GenMsgCycleTime" BO_ 263 100;
BA_ "GenMsgSendType" BO_ 263 0;
BA_ "GenMsgCycleTime" BO_ 265 100;
BA_ "GenMsgCycleTimeFast" BO_ 265 30;
BA_ "GenMsgNrOfRepetition" BO_ 265 3;
BA_ "GenMsgSendType" BO_ 265 0;
BA_ "GenMsgCycleTime" BO_ 266 500;
BA_ "GenMsgSendType" BO_ 266 0;
BA_ "GenMsgCycleTime" BO_ 267 100;
BA_ "GenMsgSendType" BO_ 267 0;
BA_ "GenMsgCycleTime" BO_ 268 100;
BA_ "GenMsgSendType" BO_ 268 0;
BA_ "GenMsgCycleTimeFast" BO_ 269 100;
BA_ "GenMsgNrOfRepetition" BO_ 269 3;
BA_ "GenMsgCycleTime" BO_ 270 100;
BA_ "GenMsgCycleTimeFast" BO_ 270 30;
BA_ "GenMsgNrOfRepetition" BO_ 270 3;
BA_ "GenMsgSendType" BO_ 270 0;
BA_ "GenMsgCycleTimeFast" BO_ 271 30;
BA_ "GenMsgNrOfRepetition" BO_ 271 3;
BA_ "GenMsgCycleTime" BO_ 273 100;
BA_ "GenMsgSendType" BO_ 273 0;
BA_ "GenMsgCycleTime" BO_ 274 100;
BA_ "GenMsgCycleTimeFast" BO_ 274 20;
BA_ "GenMsgNrOfRepetition" BO_ 274 3;
BA_ "GenMsgSendType" BO_ 274 0;
BA_ "GenMsgCycleTime" BO_ 276 100;
BA_ "GenMsgSendType" BO_ 276 0;
BA_ "GenMsgCycleTime" BO_ 278 500;
BA_ "GenMsgSendType" BO_ 278 0;
BA_ "GenMsgCycleTime" BO_ 280 500;
BA_ "GenMsgSendType" BO_ 280 0;
BA_ "GenMsgCycleTimeFast" BO_ 282 100;
BA_ "GenMsgNrOfRepetition" BO_ 282 2;
BA_ "GenMsgCycleTimeFast" BO_ 283 100;
BA_ "GenMsgNrOfRepetition" BO_ 283 3;
BA_ "GenMsgCycleTimeFast" BO_ 284 100;
BA_ "GenMsgNrOfRepetition" BO_ 284 3;
BA_ "GenMsgCycleTime" BO_ 285 200;
BA_ "GenMsgSendType" BO_ 285 0;
BA_ "GenMsgStartDelayTime" BO_ 285 20;
BA_ "GenMsgCycleTime" BO_ 286 200;
BA_ "GenMsgSendType" BO_ 286 0;
BA_ "GenMsgCycleTimeFast" BO_ 287 30;
BA_ "GenMsgNrOfRepetition" BO_ 287 3;
BA_ "GenMsgCycleTime" BO_ 290 200;
BA_ "GenMsgSendType" BO_ 290 0;
BA_ "GenMsgStartDelayTime" BO_ 290 15;
BA_ "GenMsgCycleTime" BO_ 295 80;
BA_ "GenMsgSendType" BO_ 295 0;
BA_ "GenMsgCycleTime" BO_ 296 100;
BA_ "GenMsgSendType" BO_ 296 0;
BA_ "GenMsgCycleTime" BO_ 303 100;
BA_ "GenMsgSendType" BO_ 303 0;
BA_ "GenMsgCycleTime" BO_ 306 50;
BA_ "GenMsgSendType" BO_ 306 0;
BA_ "GenMsgSendType" BO_ 307 0;
BA_ "GenMsgCycleTime" BO_ 307 100;
BA_ "GenMsgSendType" BO_ 314 0;
BA_ "GenMsgCycleTime" BO_ 314 20;
BA_ "GenMsgCycleTime" BO_ 360 100;
BA_ "GenMsgCycleTimeFast" BO_ 360 50;
BA_ "GenMsgNrOfRepetition" BO_ 360 2;
BA_ "GenMsgSendType" BO_ 360 0;
BA_ "GenMsgCycleTime" BO_ 376 10;
BA_ "GenMsgSendType" BO_ 376 0;
BA_ "GenMsgCycleTime" BO_ 381 10;
BA_ "GenMsgSendType" BO_ 381 0;
BA_ "GenMsgCycleTime" BO_ 382 10;
BA_ "GenMsgSendType" BO_ 382 0;
BA_ "GenMsgCycleTime" BO_ 385 40;
BA_ "GenMsgSendType" BO_ 385 0;
BA_ "GenMsgCycleTime" BO_ 388 50;
BA_ "GenMsgSendType" BO_ 388 0;
BA_ "GenMsgCycleTime" BO_ 388 50;
BA_ "GenMsgSendType" BO_ 388 0;
BA_ "GenMsgCycleTime" BO_ 401 40;
BA_ "GenMsgSendType" BO_ 401 0;
BA_ "GenMsgCycleTime" BO_ 404 40;
BA_ "GenMsgSendType" BO_ 404 0;
BA_ "GenMsgCycleTime" BO_ 406 40;
BA_ "GenMsgSendType" BO_ 406 0;
BA_ "GenMsgCycleTime" BO_ 410 40;
BA_ "GenMsgSendType" BO_ 410 0;
BA_ "GenMsgCycleTime" BO_ 412 40;
BA_ "GenMsgSendType" BO_ 412 0;
BA_ "GenMsgCycleTime" BO_ 413 40;
BA_ "GenMsgSendType" BO_ 413 0;
BA_ "GenMsgCycleTime" BO_ 414 40;
BA_ "GenMsgSendType" BO_ 414 0;
BA_ "GenMsgCycleTime" BO_ 415 40;
BA_ "GenMsgSendType" BO_ 415 0;
BA_ "GenMsgCycleTime" BO_ 417 20;
BA_ "GenMsgSendType" BO_ 417 0;
BA_ "GenMsgCycleTime" BO_ 504 20;
BA_ "GenMsgSendType" BO_ 504 0;
BA_ "GenMsgCycleTime" BO_ 505 20;
BA_ "GenMsgSendType" BO_ 505 0;
BA_ "GenMsgCycleTime" BO_ 518 50;
BA_ "GenMsgSendType" BO_ 518 0;
BA_ "GenMsgCycleTime" BO_ 519 100;
BA_ "GenMsgSendType" BO_ 519 0;
BA_ "GenMsgCycleTime" BO_ 520 100;
BA_ "GenMsgSendType" BO_ 520 0;
BA_ "GenSigTimeoutTime_ALL" SG_ 518 ADAS_ALC_txtpopup 500;
BA_ "InvalidValue" SG_ 518 ADAS_ALC_txtpopup "Fh";
BA_ "GenSigTimeoutTime_ALL" SG_ 518 ADAS_Lane_Line_Curva_Radius 500;
BA_ "InvalidValue" SG_ 518 ADAS_Lane_Line_Curva_Radius "0";
BA_ "GenSigTimeoutTime_ALL" SG_ 518 ADAS_LA_Display 500;
BA_ "InvalidValue" SG_ 518 ADAS_LA_Display "0";
BA_ "GenSigTimeoutTime_ALL" SG_ 518 ADAS_ALC_state 500;
BA_ "InvalidValue" SG_ 518 ADAS_ALC_state "7h";
BA_ "GenSigTimeoutTime_ALL" SG_ 518 ADAS_handsoff_txtpopup 500;
BA_ "InvalidValue" SG_ 518 ADAS_handsoff_txtpopup "3h";
BA_ "GenSigTimeoutTime_ALL" SG_ 518 ADAS_Mode2_status 500;
BA_ "InvalidValue" SG_ 518 ADAS_Mode2_status "3h";
BA_ "GenSigTimeoutTime_ALL" SG_ 518 ADAS_handsoff_Warning_Mode_2 500;
BA_ "InvalidValue" SG_ 518 ADAS_handsoff_Warning_Mode_2 "3h";
BA_ "GenSigTimeoutTime_ALL" SG_ 518 ADAS_HWA_state 500;
BA_ "InvalidValue" SG_ 518 ADAS_HWA_state "7h";
BA_ "GenSigTimeoutTime_ALL" SG_ 518 ADAS_HWA_txtpopup 500;
BA_ "InvalidValue" SG_ 518 ADAS_HWA_txtpopup "Fh";
BA_ "GenSigStartValue" SG_ 518 ADAS_ALC_Mode_feed 1;
BA_ "GenSigTimeoutTime_ALL" SG_ 518 ADAS_ALC_Mode_feed 500;
BA_ "InvalidValue" SG_ 518 ADAS_ALC_Mode_feed "3h";
BA_ "GenSigTimeoutTime_ALL" SG_ 518 ADAS_ELK_check 500;
BA_ "InvalidValue" SG_ 518 ADAS_ELK_check "0";
BA_ "GenSigTimeoutTime_ALL" SG_ 518 ADAS_HWA_Fautlstate 500;
BA_ "InvalidValue" SG_ 518 ADAS_HWA_Fautlstate "3h";
BA_ "GenSigTimeoutTime_ALL" SG_ 518 ALV_ADAS_ELK 500;
BA_ "InvalidValue" SG_ 518 ALV_ADAS_ELK "Fh";
BA_ "GenSigTimeoutTime_ALL" SG_ 518 CHKSM_ADAS_ELK 500;
BA_ "InvalidValue" SG_ 518 CHKSM_ADAS_ELK "0";
BA_ "GenSigTimeoutTime_ALL" SG_ 133 CHKSM_CRASH_Sts 200;
BA_ "InvalidValue" SG_ 133 CHKSM_CRASH_Sts "null";
BA_ "GenSigTimeoutTime_ALL" SG_ 133 ALV_CRASH_Sts 200;
BA_ "InvalidValue" SG_ 133 ALV_CRASH_Sts "Fh";
BA_ "GenSigTimeoutTime_ALL" SG_ 133 ACM_Crash_Sts 200;
BA_ "InvalidValue" SG_ 133 ACM_Crash_Sts "3h";
BA_ "GenSigTimeoutTime_ALL" SG_ 133 ACM_Airbag_Deployment_Status 200;
BA_ "InvalidValue" SG_ 133 ACM_Airbag_Deployment_Status "3h";
BA_ "GenSigTimeoutTime_ALL" SG_ 133 ACM_Crash_Intensity 200;
BA_ "InvalidValue" SG_ 133 ACM_Crash_Intensity "7h";
BA_ "GenSigTimeoutTime_ALL" SG_ 133 ACM_Front_Crash 200;
BA_ "InvalidValue" SG_ 133 ACM_Front_Crash "3h";
BA_ "GenSigTimeoutTime_ALL" SG_ 133 ACM_DriverSide_Crash 200;
BA_ "InvalidValue" SG_ 133 ACM_DriverSide_Crash "3h";
BA_ "GenSigTimeoutTime_ALL" SG_ 133 ACM_PassSide_Crash 200;
BA_ "InvalidValue" SG_ 133 ACM_PassSide_Crash "3h";
BA_ "GenSigTimeoutTime_ALL" SG_ 133 ACM_Rear_Crash 200;
BA_ "InvalidValue" SG_ 133 ACM_Rear_Crash "3h";
BA_ "GenSigTimeoutTime_ALL" SG_ 133 ACM_Rollover_Crash 200;
BA_ "InvalidValue" SG_ 133 ACM_Rollover_Crash "3h";
BA_ "GenSigSendType" SG_ 134 ACM_CrashDeltaV_PackID 1;
BA_ "GenSigStartValue" SG_ 134 ACM_CrashDeltaV_PackID 1;
BA_ "InvalidValue" SG_ 134 ACM_CrashDeltaV_PackID "FFh";
BA_ "GenSigSendType" SG_ 134 ACM_DeltaVx_01 1;
BA_ "GenSigStartValue" SG_ 134 ACM_DeltaVx_01 250;
BA_ "InvalidValue" SG_ 134 ACM_DeltaVx_01 "1FFh";
BA_ "GenSigSendType" SG_ 134 ACM_DeltaVx_02 1;
BA_ "GenSigStartValue" SG_ 134 ACM_DeltaVx_02 250;
BA_ "InvalidValue" SG_ 134 ACM_DeltaVx_02 "1FFh";
BA_ "GenSigSendType" SG_ 134 ACM_DeltaVx_03 1;
BA_ "GenSigStartValue" SG_ 134 ACM_DeltaVx_03 250;
BA_ "InvalidValue" SG_ 134 ACM_DeltaVx_03 "1FFh";
BA_ "GenSigSendType" SG_ 134 ACM_DeltaVy_01 1;
BA_ "GenSigStartValue" SG_ 134 ACM_DeltaVy_01 250;
BA_ "InvalidValue" SG_ 134 ACM_DeltaVy_01 "1FFh";
BA_ "GenSigSendType" SG_ 134 ACM_DeltaVy_02 1;
BA_ "GenSigStartValue" SG_ 134 ACM_DeltaVy_02 250;
BA_ "InvalidValue" SG_ 134 ACM_DeltaVy_02 "1FFh";
BA_ "GenSigSendType" SG_ 134 ACM_DeltaVy_03 1;
BA_ "GenSigStartValue" SG_ 134 ACM_DeltaVy_03 250;
BA_ "InvalidValue" SG_ 134 ACM_DeltaVy_03 "1FFh";
BA_ "GenSigTimeoutTime_ALL" SG_ 149 CHKSM_IDB_FUNCTION 500;
BA_ "InvalidValue" SG_ 149 CHKSM_IDB_FUNCTION "null";
BA_ "GenSigTimeoutTime_ALL" SG_ 149 ALV_IDB_FUNCTION 500;
BA_ "InvalidValue" SG_ 149 ALV_IDB_FUNCTION "Fh";
BA_ "GenSigTimeoutTime_ALL" SG_ 149 STAT_ABS 500;
BA_ "InvalidValue" SG_ 149 STAT_ABS "3h";
BA_ "GenSigTimeoutTime_ALL" SG_ 149 ABS_Active 500;
BA_ "InvalidValue" SG_ 149 ABS_Active "3h";
BA_ "GenSigTimeoutTime_ALL" SG_ 149 AYC_Active 500;
BA_ "InvalidValue" SG_ 149 AYC_Active "3h";
BA_ "GenSigTimeoutTime_ALL" SG_ 149 ASR_Active 500;
BA_ "InvalidValue" SG_ 149 ASR_Active "3h";
BA_ "GenSigTimeoutTime_ALL" SG_ 149 STAT_DSC 500;
BA_ "InvalidValue" SG_ 149 STAT_DSC "3h";
BA_ "GenSigTimeoutTime_ALL" SG_ 149 DSC_Active 500;
BA_ "InvalidValue" SG_ 149 DSC_Active "3h";
BA_ "GenSigTimeoutTime_ALL" SG_ 149 HBA_ActiveSignal 500;
BA_ "InvalidValue" SG_ 149 HBA_ActiveSignal "3h";
BA_ "GenSigTimeoutTime_ALL" SG_ 149 ARM_ActiveSignal 500;
BA_ "InvalidValue" SG_ 149 ARM_ActiveSignal "3h";
BA_ "GenSigTimeoutTime_ALL" SG_ 149 STAT_AutoHazardBlinking 500;
BA_ "InvalidValue" SG_ 149 STAT_AutoHazardBlinking "3h";
BA_ "GenSigTimeoutTime_ALL" SG_ 149 MSR_Active 500;
BA_ "InvalidValue" SG_ 149 MSR_Active "3h";
BA_ "GenSigTimeoutTime_ALL" SG_ 149 HSA_ActiveSignal 500;
BA_ "InvalidValue" SG_ 149 HSA_ActiveSignal "3h";
BA_ "GenSigTimeoutTime_ALL" SG_ 149 EPBi_ECD_ActiveSignal 500;
BA_ "InvalidValue" SG_ 149 EPBi_ECD_ActiveSignal "3h";
BA_ "GenSigTimeoutTime_ALL" SG_ 149 TSM_Active 500;
BA_ "InvalidValue" SG_ 149 TSM_Active "3h";
BA_ "GenSigTimeoutTime_ALL" SG_ 149 HAS_Available 500;
BA_ "InvalidValue" SG_ 149 HAS_Available "3h";
BA_ "GenSigTimeoutTime_ALL" SG_ 149 STAT_EBD 500;
BA_ "InvalidValue" SG_ 149 STAT_EBD "3h";
BA_ "GenSigTimeoutTime_ALL" SG_ 149 EBD_Active 500;
BA_ "InvalidValue" SG_ 149 EBD_Active "3h";
BA_ "GenSigTimeoutTime_ALL" SG_ 149 ST_BRG_MSA 500;
BA_ "InvalidValue" SG_ 149 ST_BRG_MSA "Fh";
BA_ "GenSigTimeoutTime_ALL" SG_ 217 CRC_VCU_HV_DrvSys_status 400;
BA_ "InvalidValue" SG_ 217 CRC_VCU_HV_DrvSys_status "null";
BA_ "GenSigTimeoutTime_ALL" SG_ 217 ALIV_VCU_HV_DrvSys_status 200;
BA_ "InvalidValue" SG_ 217 ALIV_VCU_HV_DrvSys_status "Fh";
BA_ "GenSigTimeoutTime_ALL" SG_ 217 VCU_HVsystem_status 200;
BA_ "InvalidValue" SG_ 217 VCU_HVsystem_status "null";
BA_ "GenSigTimeoutTime_ALL" SG_ 217 VCU_ACPD_Percent 400;
BA_ "InvalidValue" SG_ 217 VCU_ACPD_Percent "FFFh";
BA_ "GenSigTimeoutTime_ALL" SG_ 217 VCU_ACPD_Percent_Valid 400;
BA_ "InvalidValue" SG_ 217 VCU_ACPD_Percent_Valid "null";
BA_ "GenSigTimeoutTime_ALL" SG_ 217 VCU_ACTGear 400;
BA_ "InvalidValue" SG_ 217 VCU_ACTGear "null";
BA_ "GenSigTimeoutTime_ALL" SG_ 217 VCU_ACTGearValid 200;
BA_ "InvalidValue" SG_ 217 VCU_ACTGearValid "null";
BA_ "GenSigTimeoutTime_ALL" SG_ 217 VCU_ACT_DriveMode 200;
BA_ "InvalidValue" SG_ 217 VCU_ACT_DriveMode "null";
BA_ "GenSigStartValue" SG_ 217 VCU_ACT_DriveMode_Valid 1;
BA_ "GenSigTimeoutTime_ALL" SG_ 217 VCU_ACT_DriveMode_Valid 400;
BA_ "InvalidValue" SG_ 217 VCU_ACT_DriveMode_Valid "null";
BA_ "GenSigTimeoutTime_ALL" SG_ 217 VCU_HV_DRVsystem_status 400;
BA_ "InvalidValue" SG_ 217 VCU_HV_DRVsystem_status "null";
BA_ "GenSigTimeoutTime_ALL" SG_ 217 VCU_Recu_BrakeLight_ON_Req 200;
BA_ "InvalidValue" SG_ 217 VCU_Recu_BrakeLight_ON_Req "3h";
BA_ "GenSigTimeoutTime_ALL" SG_ 256 CHKSM_MHU_VEH_INFO 5000;
BA_ "InvalidValue" SG_ 256 CHKSM_MHU_VEH_INFO "null";
BA_ "GenSigTimeoutTime_ALL" SG_ 256 ALV_MHU_VEH_INFO 5000;
BA_ "InvalidValue" SG_ 256 ALV_MHU_VEH_INFO "Fh";
BA_ "GenSigTimeoutTime_ALL" SG_ 256 MHU_UserProfileId 5000;
BA_ "InvalidValue" SG_ 256 MHU_UserProfileId "Fh";
BA_ "GenSigTimeoutTime_ALL" SG_ 256 MHU_Connectivity_Status 5000;
BA_ "InvalidValue" SG_ 256 MHU_Connectivity_Status "0";
BA_ "GenSigTimeoutTime_ALL" SG_ 258 CHKSM_BCM_LOGICAL_CLAMP 500;
BA_ "InvalidValue" SG_ 258 CHKSM_BCM_LOGICAL_CLAMP "null";
BA_ "GenSigTimeoutTime_ALL" SG_ 258 ALIVE_BCM_LOGICAL_CLAMP 500;
BA_ "InvalidValue" SG_ 258 ALIVE_BCM_LOGICAL_CLAMP "Fh";
BA_ "GenSigTimeoutTime_ALL" SG_ 258 STAT_CL30s_Light_L 500;
BA_ "InvalidValue" SG_ 258 STAT_CL30s_Light_L "3h";
BA_ "GenSigStartValue" SG_ 258 STAT_CL30s_L 3;
BA_ "GenSigTimeoutTime_ALL" SG_ 258 STAT_CL30s_L 500;
BA_ "InvalidValue" SG_ 258 STAT_CL30s_L "3h";
BA_ "GenSigStartValue" SG_ 258 STAT_CL15Wup_L 3;
BA_ "GenSigTimeoutTime_ALL" SG_ 258 STAT_CL15Wup_L 500;
BA_ "InvalidValue" SG_ 258 STAT_CL15Wup_L "3h";
BA_ "GenSigTimeoutTime_ALL" SG_ 258 STAT_CrankRelayHW_BCM 500;
BA_ "InvalidValue" SG_ 258 STAT_CrankRelayHW_BCM "3h";
BA_ "GenSigSendType" SG_ 259 REQ_ConsumerControlWirelessCharg 3;
BA_ "GenSigTimeoutTime_ALL" SG_ 259 REQ_ConsumerControlWirelessCharg 5000;
BA_ "InvalidValue" SG_ 259 REQ_ConsumerControlWirelessCharg "3h";
BA_ "GenSigSendType" SG_ 259 REQ_ConsumerControlSeatMassage 3;
BA_ "GenSigTimeoutTime_ALL" SG_ 259 REQ_ConsumerControlSeatMassage 5000;
BA_ "InvalidValue" SG_ 259 REQ_ConsumerControlSeatMassage "3h";
BA_ "GenSigSendType" SG_ 259 REQ_ConsumerControlAudioVolumeCo 3;
BA_ "GenSigTimeoutTime_ALL" SG_ 259 REQ_ConsumerControlAudioVolumeCo 5000;
BA_ "InvalidValue" SG_ 259 REQ_ConsumerControlAudioVolumeCo "7h";
BA_ "GenSigSendType" SG_ 259 REQ_CCU_PTC_Limitation 3;
BA_ "GenSigTimeoutTime_ALL" SG_ 259 REQ_CCU_PTC_Limitation 5000;
BA_ "InvalidValue" SG_ 259 REQ_CCU_PTC_Limitation "7h";
BA_ "GenSigSendType" SG_ 259 REQ_ConsumerControlRearDefrost 3;
BA_ "GenSigTimeoutTime_ALL" SG_ 259 REQ_ConsumerControlRearDefrost 5000;
BA_ "InvalidValue" SG_ 259 REQ_ConsumerControlRearDefrost "3h";
BA_ "GenSigSendType" SG_ 259 REQ_ConsumerControlSeatHeatingRe 3;
BA_ "GenSigTimeoutTime_ALL" SG_ 259 REQ_ConsumerControlSeatHeatingRe 5000;
BA_ "InvalidValue" SG_ 259 REQ_ConsumerControlSeatHeatingRe "FFh";
BA_ "GenSigSendType" SG_ 259 REQ_ConsumerControlSeatVentilati 3;
BA_ "GenSigTimeoutTime_ALL" SG_ 259 REQ_ConsumerControlSeatVentilati 5000;
BA_ "InvalidValue" SG_ 259 REQ_ConsumerControlSeatVentilati "FFh";
BA_ "GenSigSendType" SG_ 259 REQ_ConsumerControlSeatHeatingFr 3;
BA_ "GenSigTimeoutTime_ALL" SG_ 259 REQ_ConsumerControlSeatHeatingFr 5000;
BA_ "InvalidValue" SG_ 259 REQ_ConsumerControlSeatHeatingFr "FFh";
BA_ "GenSigSendType" SG_ 259 DriverIdealTimerCount 3;
BA_ "GenSigTimeoutTime_ALL" SG_ 259 DriverIdealTimerCount 5000;
BA_ "InvalidValue" SG_ 259 DriverIdealTimerCount "FFh";
BA_ "GenSigSendType" SG_ 259 REQ_ConsumerControlVentilationCl 3;
BA_ "GenSigStartValue" SG_ 259 REQ_ConsumerControlVentilationCl 100;
BA_ "GenSigTimeoutTime_ALL" SG_ 259 REQ_ConsumerControlVentilationCl 5000;
BA_ "InvalidValue" SG_ 259 REQ_ConsumerControlVentilationCl "FFh";
BA_ "GenSigTimeoutTime_ALL" SG_ 260 CHKSM_LV_BATT_CHARG 500;
BA_ "InvalidValue" SG_ 260 CHKSM_LV_BATT_CHARG "null";
BA_ "GenSigTimeoutTime_ALL" SG_ 260 ALIV_LV_BATT_CHARG 500;
BA_ "InvalidValue" SG_ 260 ALIV_LV_BATT_CHARG "Fh";
BA_ "GenSigStartValue" SG_ 260 SOH_SUL 255;
BA_ "GenSigTimeoutTime_ALL" SG_ 260 SOH_SUL 500;
BA_ "InvalidValue" SG_ 260 SOH_SUL "FFh";
BA_ "GenSigStartValue" SG_ 260 SOH_SUL_STATE 3;
BA_ "GenSigTimeoutTime_ALL" SG_ 260 SOH_SUL_STATE 500;
BA_ "InvalidValue" SG_ 260 SOH_SUL_STATE "3h";
BA_ "GenSigStartValue" SG_ 260 SOC_STATE 3;
BA_ "GenSigTimeoutTime_ALL" SG_ 260 SOC_STATE 500;
BA_ "InvalidValue" SG_ 260 SOC_STATE "3h";
BA_ "GenSigTimeoutTime_ALL" SG_ 260 Resp_Error 500;
BA_ "InvalidValue" SG_ 260 Resp_Error "null";
BA_ "GenSigTimeoutTime_ALL" SG_ 260 FLAG_INCONSTENCY 500;
BA_ "InvalidValue" SG_ 260 FLAG_INCONSTENCY "null";
BA_ "GenSigTimeoutTime_ALL" SG_ 260 EBS_error 500;
BA_ "InvalidValue" SG_ 260 EBS_error "null";
BA_ "GenSigTimeoutTime_ALL" SG_ 260 FLAG_DISCONNECT 500;
BA_ "InvalidValue" SG_ 260 FLAG_DISCONNECT "null";
BA_ "GenSigTimeoutTime_ALL" SG_ 260 BCM_LV_Batt_Charging_Req 500;
BA_ "InvalidValue" SG_ 260 BCM_LV_Batt_Charging_Req "null";
BA_ "GenSigTimeoutTime_ALL" SG_ 260 IBATT_QUIESCENT 500;
BA_ "GenSigStartValue" SG_ 260 LV_TargetVoltage 26;
BA_ "GenSigTimeoutTime_ALL" SG_ 260 LV_TargetVoltage 500;
BA_ "InvalidValue" SG_ 260 LV_TargetVoltage "-";
BA_ "GenSigStartValue" SG_ 260 LV_TargetCurrent 512;
BA_ "GenSigTimeoutTime_ALL" SG_ 260 LV_TargetCurrent 500;
BA_ "InvalidValue" SG_ 260 LV_TargetCurrent "-";
BA_ "GenSigTimeoutTime_ALL" SG_ 261 CHKSM_BCM_STAT_DOOR_FLAP 500;
BA_ "InvalidValue" SG_ 261 CHKSM_BCM_STAT_DOOR_FLAP "null";
BA_ "GenSigTimeoutTime_ALL" SG_ 261 ALIVE_BCM_STAT_DOOR_FLAP 500;
BA_ "InvalidValue" SG_ 261 ALIVE_BCM_STAT_DOOR_FLAP "Fh";
BA_ "GenSigTimeoutTime_ALL" SG_ 261 BCM_STAT_TrunkAjar 500;
BA_ "InvalidValue" SG_ 261 BCM_STAT_TrunkAjar "3h";
BA_ "GenSigTimeoutTime_ALL" SG_ 261 BCM_STAT_DoorAjarFL 500;
BA_ "InvalidValue" SG_ 261 BCM_STAT_DoorAjarFL "3h";
BA_ "GenSigTimeoutTime_ALL" SG_ 261 BCM_STAT_DoorAjarFR 500;
BA_ "InvalidValue" SG_ 261 BCM_STAT_DoorAjarFR "3h";
BA_ "GenSigTimeoutTime_ALL" SG_ 261 BCM_STAT_DoorAjarRL 500;
BA_ "InvalidValue" SG_ 261 BCM_STAT_DoorAjarRL "3h";
BA_ "GenSigTimeoutTime_ALL" SG_ 261 BCM_STAT_DoorAjarRR 500;
BA_ "InvalidValue" SG_ 261 BCM_STAT_DoorAjarRR "3h";
BA_ "GenSigTimeoutTime_ALL" SG_ 261 BCM_STAT_BonnetAjar 500;
BA_ "InvalidValue" SG_ 261 BCM_STAT_BonnetAjar "3h";
BA_ "GenSigTimeoutTime_ALL" SG_ 262 CHKSM_BCM_LIGHT 500;
BA_ "InvalidValue" SG_ 262 CHKSM_BCM_LIGHT "null";
BA_ "GenSigTimeoutTime_ALL" SG_ 262 ALIVE_BCM_LIGHT 500;
BA_ "InvalidValue" SG_ 262 ALIVE_BCM_LIGHT "Fh";
BA_ "GenSigTimeoutTime_ALL" SG_ 262 BCM_DayRunningLampSts 500;
BA_ "InvalidValue" SG_ 262 BCM_DayRunningLampSts "3h";
BA_ "GenSigTimeoutTime_ALL" SG_ 262 BCM_ReverseLightSts 500;
BA_ "InvalidValue" SG_ 262 BCM_ReverseLightSts "3h";
BA_ "GenSigTimeoutTime_ALL" SG_ 262 BCM_StopLightSts 500;
BA_ "InvalidValue" SG_ 262 BCM_StopLightSts "3h";
BA_ "GenSigTimeoutTime_ALL" SG_ 262 BCM_LicensePlateLightSts 500;
BA_ "InvalidValue" SG_ 262 BCM_LicensePlateLightSts "3h";
BA_ "GenSigTimeoutTime_ALL" SG_ 262 BCM_Fr_Dimming_dome_lampSts 500;
BA_ "InvalidValue" SG_ 262 BCM_Fr_Dimming_dome_lampSts "3h";
BA_ "GenSigTimeoutTime_ALL" SG_ 262 BCM_Rr_Dimming_dome_lampSts 500;
BA_ "InvalidValue" SG_ 262 BCM_Rr_Dimming_dome_lampSts "3h";
BA_ "GenSigStartValue" SG_ 262 BCM_STAT_InteriorLight 3;
BA_ "GenSigTimeoutTime_ALL" SG_ 262 BCM_STAT_InteriorLight 500;
BA_ "InvalidValue" SG_ 262 BCM_STAT_InteriorLight "3h";
BA_ "GenSigStartValue" SG_ 262 BCM_STAT_LightActivation 7;
BA_ "GenSigTimeoutTime_ALL" SG_ 262 BCM_STAT_LightActivation 500;
BA_ "InvalidValue" SG_ 262 BCM_STAT_LightActivation "7h";
BA_ "GenSigTimeoutTime_ALL" SG_ 262 BCM_HighBeamSts 500;
BA_ "InvalidValue" SG_ 262 BCM_HighBeamSts "3h";
BA_ "GenSigStartValue" SG_ 262 BCM_STAT_SwitchLightBrightness 80;
BA_ "GenSigTimeoutTime_ALL" SG_ 262 BCM_STAT_SwitchLightBrightness 500;
BA_ "InvalidValue" SG_ 262 BCM_STAT_SwitchLightBrightness "7Fh";
BA_ "GenSigTimeoutTime_ALL" SG_ 262 BCM_LowBeamSts 500;
BA_ "InvalidValue" SG_ 262 BCM_LowBeamSts "3h";
BA_ "GenSigTimeoutTime_ALL" SG_ 262 BCM_RearFogLmpSts 500;
BA_ "InvalidValue" SG_ 262 BCM_RearFogLmpSts "3h";
BA_ "GenSigTimeoutTime_ALL" SG_ 262 BCM_FrntFogLmpSts 500;
BA_ "InvalidValue" SG_ 262 BCM_FrntFogLmpSts "3h";
BA_ "GenSigTimeoutTime_ALL" SG_ 262 BCM_PosLmpSts 500;
BA_ "InvalidValue" SG_ 262 BCM_PosLmpSts "3h";
BA_ "GenSigTimeoutTime_ALL" SG_ 262 BCM_BackGrdCl58Sts 500;
BA_ "InvalidValue" SG_ 262 BCM_BackGrdCl58Sts "3h";
BA_ "GenSigTimeoutTime_ALL" SG_ 262 BCM_HornSts 500;
BA_ "InvalidValue" SG_ 262 BCM_HornSts "3h";
BA_ "GenSigSendType" SG_ 262 BCM_TurnIndicatorSts 3;
BA_ "GenSigTimeoutTime_ALL" SG_ 262 BCM_TurnIndicatorSts 500;
BA_ "InvalidValue" SG_ 262 BCM_TurnIndicatorSts "3h";
BA_ "GenSigTimeoutTime_ALL" SG_ 263 CHKSM_BCM_CENTRAL_LOCK 500;
BA_ "InvalidValue" SG_ 263 CHKSM_BCM_CENTRAL_LOCK "null";
BA_ "GenSigTimeoutTime_ALL" SG_ 263 ALV_BCM_CENTRAL_LOCK 500;
BA_ "InvalidValue" SG_ 263 ALV_BCM_CENTRAL_LOCK "Fh";
BA_ "GenSigTimeoutTime_ALL" SG_ 263 STAT_CDL_LED 500;
BA_ "InvalidValue" SG_ 263 STAT_CDL_LED "3h";
BA_ "GenSigTimeoutTime_ALL" SG_ 263 STAT_DoorUnlockFL 500;
BA_ "InvalidValue" SG_ 263 STAT_DoorUnlockFL "3h";
BA_ "GenSigTimeoutTime_ALL" SG_ 263 STAT_ATWS 500;
BA_ "InvalidValue" SG_ 263 STAT_ATWS "7h";
BA_ "GenSigTimeoutTime_ALL" SG_ 263 BCM_CentralLockSwSts 500;
BA_ "InvalidValue" SG_ 263 BCM_CentralLockSwSts "1h";
BA_ "GenSigTimeoutTime_ALL" SG_ 263 STAT_DoorLockFL 500;
BA_ "InvalidValue" SG_ 263 STAT_DoorLockFL "3h";
BA_ "GenSigTimeoutTime_ALL" SG_ 265 CHKSM_BCM_SWITCH_Sts 500;
BA_ "InvalidValue" SG_ 265 CHKSM_BCM_SWITCH_Sts "null";
BA_ "GenSigTimeoutTime_ALL" SG_ 265 ALV_BCM_SWITCH_Sts 500;
BA_ "InvalidValue" SG_ 265 ALV_BCM_SWITCH_Sts "Fh";
BA_ "GenSigSendType" SG_ 265 BCM_STAT_BrakeSwitch 4;
BA_ "GenSigTimeoutTime_ALL" SG_ 265 BCM_STAT_BrakeSwitch 500;
BA_ "InvalidValue" SG_ 265 BCM_STAT_BrakeSwitch "3h";
BA_ "GenSigSendType" SG_ 265 BCM_STAT_HazardWarn 4;
BA_ "GenSigTimeoutTime_ALL" SG_ 265 BCM_STAT_HazardWarn 500;
BA_ "InvalidValue" SG_ 265 BCM_STAT_HazardWarn "3h";
BA_ "GenSigSendType" SG_ 265 BCM_STAT_FuelPumpCutOFF 4;
BA_ "GenSigTimeoutTime_ALL" SG_ 265 BCM_STAT_FuelPumpCutOFF 500;
BA_ "InvalidValue" SG_ 265 BCM_STAT_FuelPumpCutOFF "3h";
BA_ "GenSigTimeoutTime_ALL" SG_ 265 BCM_FollowMeHomeActive 500;
BA_ "InvalidValue" SG_ 265 BCM_FollowMeHomeActive "3h";
BA_ "GenSigSendType" SG_ 265 BCM_STAT_Horn 4;
BA_ "GenSigTimeoutTime_ALL" SG_ 265 BCM_STAT_Horn 500;
BA_ "InvalidValue" SG_ 265 BCM_STAT_Horn "3h";
BA_ "GenSigSendType" SG_ 265 BCM_STAT_Autowiping 4;
BA_ "GenSigTimeoutTime_ALL" SG_ 265 BCM_STAT_Autowiping 500;
BA_ "InvalidValue" SG_ 265 BCM_STAT_Autowiping "3h";
BA_ "GenSigTimeoutTime_ALL" SG_ 265 BCM_TurnIndicator 500;
BA_ "InvalidValue" SG_ 265 BCM_TurnIndicator "3h";
BA_ "GenSigTimeoutTime_ALL" SG_ 265 BCM_WelcomeActive 500;
BA_ "InvalidValue" SG_ 265 BCM_WelcomeActive "3h";
BA_ "GenSigTimeoutTime_ALL" SG_ 265 BCM_HighBeam 500;
BA_ "InvalidValue" SG_ 265 BCM_HighBeam "3h";
BA_ "GenSigTimeoutTime_ALL" SG_ 265 ACM_Seat_Belt_Status_3rd_Row_Pas 500;
BA_ "InvalidValue" SG_ 265 ACM_Seat_Belt_Status_3rd_Row_Pas "null";
BA_ "GenSigTimeoutTime_ALL" SG_ 265 ACM_Seat_Belt_Status_3rd_Row_Dri 500;
BA_ "InvalidValue" SG_ 265 ACM_Seat_Belt_Status_3rd_Row_Dri "null";
BA_ "GenSigTimeoutTime_ALL" SG_ 265 BCM_AlcoholockSwitch 500;
BA_ "GenSigTimeoutTime_ALL" SG_ 266 CHKSM_BCM_VOLTAGE 2500;
BA_ "InvalidValue" SG_ 266 CHKSM_BCM_VOLTAGE "null";
BA_ "GenSigTimeoutTime_ALL" SG_ 266 ALIVE_BCM_VOLTAGE 2500;
BA_ "InvalidValue" SG_ 266 ALIVE_BCM_VOLTAGE "Fh";
BA_ "GenSigTimeoutTime_ALL" SG_ 266 LV_BatteryType 2500;
BA_ "InvalidValue" SG_ 266 LV_BatteryType "-";
BA_ "GenSigStartValue" SG_ 266 UBatt 9205;
BA_ "GenSigTimeoutTime_ALL" SG_ 266 UBatt 2500;
BA_ "InvalidValue" SG_ 266 UBatt "3FFFh";
BA_ "GenSigStartValue" SG_ 266 LV_Batt_Temp 40;
BA_ "GenSigTimeoutTime_ALL" SG_ 266 LV_Batt_Temp 2500;
BA_ "InvalidValue" SG_ 266 LV_Batt_Temp "FFh";
BA_ "GenSigTimeoutTime_ALL" SG_ 266 LV_SOC 2500;
BA_ "InvalidValue" SG_ 266 LV_SOC "FFh";
BA_ "GenSigStartValue" SG_ 266 LV_Batt_Current 49152;
BA_ "GenSigTimeoutTime_ALL" SG_ 266 LV_Batt_Current 2500;
BA_ "InvalidValue" SG_ 266 LV_Batt_Current "FFFFh";
BA_ "GenSigTimeoutTime_ALL" SG_ 267 ALIVE_TRM_LIGHT 500;
BA_ "InvalidValue" SG_ 267 ALIVE_TRM_LIGHT "Fh";
BA_ "GenSigStartValue" SG_ 267 TrailerInput 3;
BA_ "GenSigTimeoutTime_ALL" SG_ 267 TrailerInput 500;
BA_ "InvalidValue" SG_ 267 TrailerInput "3h";
BA_ "GenSigStartValue" SG_ 267 TrailerSystemError 3;
BA_ "GenSigTimeoutTime_ALL" SG_ 267 TrailerSystemError 500;
BA_ "InvalidValue" SG_ 267 TrailerSystemError "3h";
BA_ "GenSigTimeoutTime_ALL" SG_ 267 TRM_VoltageStatus 500;
BA_ "InvalidValue" SG_ 267 TRM_VoltageStatus "3h";
BA_ "GenSigTimeoutTime_ALL" SG_ 267 TRM_STAT_BrakeLight 500;
BA_ "InvalidValue" SG_ 267 TRM_STAT_BrakeLight "3h";
BA_ "GenSigTimeoutTime_ALL" SG_ 267 TRM_STAT_FogLampRear 500;
BA_ "InvalidValue" SG_ 267 TRM_STAT_FogLampRear "3h";
BA_ "GenSigTimeoutTime_ALL" SG_ 267 TRM_STAT_PositionLight 500;
BA_ "InvalidValue" SG_ 267 TRM_STAT_PositionLight "3h";
BA_ "GenSigTimeoutTime_ALL" SG_ 267 TRM_STAT_TurnIndicators 500;
BA_ "InvalidValue" SG_ 267 TRM_STAT_TurnIndicators "Fh";
BA_ "GenSigTimeoutTime_ALL" SG_ 267 TRM_STAT_ReverseLight 500;
BA_ "InvalidValue" SG_ 267 TRM_STAT_ReverseLight "3h";
BA_ "GenSigTimeoutTime_ALL" SG_ 267 TRM_STAT_HWBrakeLightInput 500;
BA_ "InvalidValue" SG_ 267 TRM_STAT_HWBrakeLightInput "3h";
BA_ "GenSigTimeoutTime_ALL" SG_ 267 TRM_STAT_HWIndicatorInput 500;
BA_ "InvalidValue" SG_ 267 TRM_STAT_HWIndicatorInput "3h";
BA_ "GenSigTimeoutTime_ALL" SG_ 267 TRM_STAT_HWPosLightInput 500;
BA_ "InvalidValue" SG_ 267 TRM_STAT_HWPosLightInput "3h";
BA_ "GenSigTimeoutTime_ALL" SG_ 268 Checksum_0x10C 500;
BA_ "InvalidValue" SG_ 268 Checksum_0x10C "null";
BA_ "GenSigTimeoutTime_ALL" SG_ 268 Rolling_Counter_0x10C 500;
BA_ "InvalidValue" SG_ 268 Rolling_Counter_0x10C "Fh";
BA_ "GenSigTimeoutTime_ALL" SG_ 268 BCM_TboxAuthStatus 500;
BA_ "InvalidValue" SG_ 268 BCM_TboxAuthStatus "3h";
BA_ "GenSigTimeoutTime_ALL" SG_ 268 BCM_RandomNum32bit 500;
BA_ "InvalidValue" SG_ 268 BCM_RandomNum32bit "null";
BA_ "GenSigSendType" SG_ 269 MHU_APM_ReqWindow 2;
BA_ "InvalidValue" SG_ 269 MHU_APM_ReqWindow "3h";
BA_ "GenSigSendType" SG_ 269 MHU_BCM_RemoteDoorCtrl 2;
BA_ "GenSigStartValue" SG_ 269 MHU_BCM_RemoteDoorCtrl 2;
BA_ "InvalidValue" SG_ 269 MHU_BCM_RemoteDoorCtrl "3h";
BA_ "GenSigSendType" SG_ 269 MHU_BCM_reqTrunk 2;
BA_ "GenSigStartValue" SG_ 269 MHU_BCM_reqTrunk 2;
BA_ "InvalidValue" SG_ 269 MHU_BCM_reqTrunk "3h";
BA_ "GenSigSendType" SG_ 269 MHU_BCM_reqFrunk 2;
BA_ "InvalidValue" SG_ 269 MHU_BCM_reqFrunk "3h";
BA_ "GenSigSendType" SG_ 269 MHU_BCM_ReqSunroof 2;
BA_ "GenSigStartValue" SG_ 269 MHU_BCM_ReqSunroof 255;
BA_ "InvalidValue" SG_ 269 MHU_BCM_ReqSunroof "FFh";
BA_ "GenSigSendType" SG_ 269 TBOX_AuthCode_0x10D 2;
BA_ "GenSigTimeoutTime_ALL" SG_ 270 GlobalWindowReq 500;
BA_ "GenSigSendType" SG_ 270 RemoteAccessKey 4;
BA_ "GenSigTimeoutTime_ALL" SG_ 270 RemoteAccessKey 500;
BA_ "InvalidValue" SG_ 270 RemoteAccessKey "Fh";
BA_ "GenSigSendType" SG_ 270 PassiveAccessTrunk 4;
BA_ "GenSigTimeoutTime_ALL" SG_ 270 PassiveAccessTrunk 500;
BA_ "InvalidValue" SG_ 270 PassiveAccessTrunk "3h";
BA_ "GenSigSendType" SG_ 270 ComfortOpen 4;
BA_ "GenSigStartValue" SG_ 270 ComfortOpen 3;
BA_ "GenSigTimeoutTime_ALL" SG_ 270 ComfortOpen 500;
BA_ "InvalidValue" SG_ 270 ComfortOpen "3h";
BA_ "GenSigSendType" SG_ 270 PassiveAccessDoor 4;
BA_ "GenSigTimeoutTime_ALL" SG_ 270 PassiveAccessDoor 500;
BA_ "InvalidValue" SG_ 270 PassiveAccessDoor "3h";
BA_ "GenSigSendType" SG_ 270 FksOpen 4;
BA_ "GenSigTimeoutTime_ALL" SG_ 270 FksOpen 500;
BA_ "InvalidValue" SG_ 270 FksOpen "3h";
BA_ "GenSigSendType" SG_ 271 MHU_SetHornOnOff 2;
BA_ "GenSigStartValue" SG_ 271 MHU_SetHornOnOff 2;
BA_ "InvalidValue" SG_ 271 MHU_SetHornOnOff "3h";
BA_ "GenSigSendType" SG_ 271 MHU_SetLowBeam 2;
BA_ "GenSigStartValue" SG_ 271 MHU_SetLowBeam 2;
BA_ "InvalidValue" SG_ 271 MHU_SetLowBeam "3h";
BA_ "GenSigSendType" SG_ 271 MHU_SetHighBeam 2;
BA_ "GenSigStartValue" SG_ 271 MHU_SetHighBeam 2;
BA_ "InvalidValue" SG_ 271 MHU_SetHighBeam "3h";
BA_ "GenSigSendType" SG_ 271 TBOX_AuthCode_0x10F 2;
BA_ "GenSigTimeoutTime_ALL" SG_ 273 BCM_Stat_SwitchLightBrightness 500;
BA_ "InvalidValue" SG_ 273 BCM_Stat_SwitchLightBrightness "null";
BA_ "GenSigTimeoutTime_ALL" SG_ 273 BCM_Rear_Wiper_Park_Pos_Status 500;
BA_ "GenSigTimeoutTime_ALL" SG_ 273 BCM_Front_Wiper_Park_Pos_Status 500;
BA_ "GenSigTimeoutTime_ALL" SG_ 273 BCM_Rear_Wash_Status 500;
BA_ "GenSigTimeoutTime_ALL" SG_ 273 BCM_Front_Wash_Status 500;
BA_ "GenSigTimeoutTime_ALL" SG_ 274 STAT_TransportMode 500;
BA_ "InvalidValue" SG_ 274 STAT_TransportMode "null";
BA_ "GenSigTimeoutTime_ALL" SG_ 274 CHKSM_BCM_CLAMP_STAT 500;
BA_ "InvalidValue" SG_ 274 CHKSM_BCM_CLAMP_STAT "null";
BA_ "GenSigTimeoutTime_ALL" SG_ 274 ALIVE_BCM_CLAMP_STAT 500;
BA_ "InvalidValue" SG_ 274 ALIVE_BCM_CLAMP_STAT "Fh";
BA_ "GenSigSendType" SG_ 274 RemoteFunctionState 4;
BA_ "GenSigTimeoutTime_ALL" SG_ 274 RemoteFunctionState 500;
BA_ "InvalidValue" SG_ 274 RemoteFunctionState "3h";
BA_ "GenSigTimeoutTime_ALL" SG_ 274 STAT_BLS 500;
BA_ "InvalidValue" SG_ 274 STAT_BLS "3h";
BA_ "GenSigTimeoutTime_ALL" SG_ 274 STAT_CL_50_L 500;
BA_ "InvalidValue" SG_ 274 STAT_CL_50_L "3h";
BA_ "GenSigSendType" SG_ 274 Clamp50AdviceRemoteStart 4;
BA_ "GenSigTimeoutTime_ALL" SG_ 274 Clamp50AdviceRemoteStart 500;
BA_ "InvalidValue" SG_ 274 Clamp50AdviceRemoteStart "3h";
BA_ "GenSigSendType" SG_ 274 Clamp50AdviceESS 4;
BA_ "GenSigTimeoutTime_ALL" SG_ 274 Clamp50AdviceESS 500;
BA_ "InvalidValue" SG_ 274 Clamp50AdviceESS "3h";
BA_ "GenSigTimeoutTime_ALL" SG_ 274 STAT_CL_R_L 500;
BA_ "InvalidValue" SG_ 274 STAT_CL_R_L "3h";
BA_ "GenSigTimeoutTime_ALL" SG_ 274 STAT_CL_15_1_L 500;
BA_ "InvalidValue" SG_ 274 STAT_CL_15_1_L "3h";
BA_ "GenSigTimeoutTime_ALL" SG_ 274 STAT_CL_15_1_DME_L 500;
BA_ "InvalidValue" SG_ 274 STAT_CL_15_1_DME_L "3h";
BA_ "GenSigTimeoutTime_ALL" SG_ 274 FobId 500;
BA_ "InvalidValue" SG_ 274 FobId "3h";
BA_ "GenSigTimeoutTime_ALL" SG_ 274 STAT_Terminal 500;
BA_ "InvalidValue" SG_ 274 STAT_Terminal "7h";
BA_ "GenSigTimeoutTime_ALL" SG_ 274 STAT_CL30_C_BEV 500;
BA_ "InvalidValue" SG_ 274 STAT_CL30_C_BEV "3h";
BA_ "GenSigTimeoutTime_ALL" SG_ 274 BCM_Clamp_Transport 500;
BA_ "InvalidValue" SG_ 274 BCM_Clamp_Transport "7h";
BA_ "GenSigTimeoutTime_ALL" SG_ 276 CHKSM_LVBAT_DATA 500;
BA_ "InvalidValue" SG_ 276 CHKSM_LVBAT_DATA "-";
BA_ "GenSigTimeoutTime_ALL" SG_ 276 ALIV_LVBAT_DATA 500;
BA_ "InvalidValue" SG_ 276 ALIV_LVBAT_DATA "Fh";
BA_ "GenSigTimeoutTime_ALL" SG_ 276 LV_ErrorSts 500;
BA_ "InvalidValue" SG_ 276 LV_ErrorSts "7h";
BA_ "GenSigTimeoutTime_ALL" SG_ 276 LV_MinCellVolt 500;
BA_ "InvalidValue" SG_ 276 LV_MinCellVolt "-";
BA_ "GenSigTimeoutTime_ALL" SG_ 276 LV_MaxCellVolt 500;
BA_ "InvalidValue" SG_ 276 LV_MaxCellVolt "-";
BA_ "GenSigStartValue" SG_ 276 LV_MinCellTemp 40;
BA_ "GenSigTimeoutTime_ALL" SG_ 276 LV_MinCellTemp 500;
BA_ "InvalidValue" SG_ 276 LV_MinCellTemp "-";
BA_ "GenSigStartValue" SG_ 276 LV_MaxCellTemp 40;
BA_ "GenSigTimeoutTime_ALL" SG_ 276 LV_MaxCellTemp 500;
BA_ "InvalidValue" SG_ 276 LV_MaxCellTemp "-";
BA_ "GenSigTimeoutTime_ALL" SG_ 276 LV_Discharger_Err 500;
BA_ "InvalidValue" SG_ 276 LV_Discharger_Err "-";
BA_ "GenSigTimeoutTime_ALL" SG_ 276 LV_Discharger_Sts 500;
BA_ "InvalidValue" SG_ 276 LV_Discharger_Sts "-";
BA_ "GenSigTimeoutTime_ALL" SG_ 276 LV_Charger_Err 500;
BA_ "InvalidValue" SG_ 276 LV_Charger_Err "-";
BA_ "GenSigTimeoutTime_ALL" SG_ 276 LV_Charger_Sts 500;
BA_ "InvalidValue" SG_ 276 LV_Charger_Sts "-";
BA_ "GenSigTimeoutTime_ALL" SG_ 276 LV_OverVoltage 500;
BA_ "InvalidValue" SG_ 276 LV_OverVoltage "-";
BA_ "GenSigTimeoutTime_ALL" SG_ 276 LV_UnderVoltage 500;
BA_ "InvalidValue" SG_ 276 LV_UnderVoltage "-";
BA_ "GenSigTimeoutTime_ALL" SG_ 276 LV_OverCurrent 500;
BA_ "InvalidValue" SG_ 276 LV_OverCurrent "-";
BA_ "GenSigTimeoutTime_ALL" SG_ 276 LV_UnderTemp 500;
BA_ "InvalidValue" SG_ 276 LV_UnderTemp "-";
BA_ "GenSigTimeoutTime_ALL" SG_ 276 LV_OverTemp 500;
BA_ "InvalidValue" SG_ 276 LV_OverTemp "-";
BA_ "GenSigTimeoutTime_ALL" SG_ 276 LV_OverCharge 500;
BA_ "InvalidValue" SG_ 276 LV_OverCharge "-";
BA_ "GenSigTimeoutTime_ALL" SG_ 276 LV_OverDischarge 500;
BA_ "InvalidValue" SG_ 276 LV_OverDischarge "-";
BA_ "GenSigTimeoutTime_ALL" SG_ 276 LV_CellBalance_Sts 500;
BA_ "InvalidValue" SG_ 276 LV_CellBalance_Sts "-";
BA_ "GenSigTimeoutTime_ALL" SG_ 276 LV_CellBalance_Error 500;
BA_ "InvalidValue" SG_ 276 LV_CellBalance_Error "-";
BA_ "GenSigTimeoutTime_ALL" SG_ 276 LV_ThermalRunaway 500;
BA_ "InvalidValue" SG_ 276 LV_ThermalRunaway "-";
BA_ "GenSigTimeoutTime_ALL" SG_ 276 LV_WarmupRequest 500;
BA_ "InvalidValue" SG_ 276 LV_WarmupRequest "3h";
BA_ "GenSigSendType" SG_ 277 BCM_ChildLock_Feedback 1;
BA_ "InvalidValue" SG_ 277 BCM_ChildLock_Feedback "null";
BA_ "GenSigTimeoutTime_ALL" SG_ 278 CHKSM_LVBAT_INFO2 2500;
BA_ "InvalidValue" SG_ 278 CHKSM_LVBAT_INFO2 "-";
BA_ "GenSigTimeoutTime_ALL" SG_ 278 ALIV_LVBAT_INFO2 2500;
BA_ "InvalidValue" SG_ 278 ALIV_LVBAT_INFO2 "Fh";
BA_ "GenSigTimeoutTime_ALL" SG_ 278 LV_MaxAllowDischargeCurrent 2500;
BA_ "InvalidValue" SG_ 278 LV_MaxAllowDischargeCurrent "-";
BA_ "GenSigTimeoutTime_ALL" SG_ 278 LV_WakeupReason 2500;
BA_ "InvalidValue" SG_ 278 LV_WakeupReason "7h";
BA_ "GenSigTimeoutTime_ALL" SG_ 278 LV_MaxAllowChargeCurrent 2500;
BA_ "InvalidValue" SG_ 278 LV_MaxAllowChargeCurrent "-";
BA_ "GenSigTimeoutTime_ALL" SG_ 278 LV_SOE 2500;
BA_ "InvalidValue" SG_ 278 LV_SOE "-";
BA_ "GenSigTimeoutTime_ALL" SG_ 280 CHKSM_BCM_MHU_Ctrl_Fbk 2500;
BA_ "InvalidValue" SG_ 280 CHKSM_BCM_MHU_Ctrl_Fbk "null";
BA_ "GenSigTimeoutTime_ALL" SG_ 280 ALV_BCM_MHU_Ctrl_Fbk 2500;
BA_ "InvalidValue" SG_ 280 ALV_BCM_MHU_Ctrl_Fbk "Fh";
BA_ "GenSigTimeoutTime_ALL" SG_ 280 BCM_DrvInhibitStsFbk 2500;
BA_ "InvalidValue" SG_ 280 BCM_DrvInhibitStsFbk "0h";
BA_ "GenSigSendType" SG_ 282 MHU_SET_WiperServicePositionMod 2;
BA_ "GenSigStartValue" SG_ 282 MHU_SET_WiperServicePositionMod 3;
BA_ "InvalidValue" SG_ 282 MHU_SET_WiperServicePositionMod "null";
BA_ "GenSigSendType" SG_ 282 MHU_Read_KeyFobOnCenterConsole 2;
BA_ "GenSigStartValue" SG_ 282 MHU_Read_KeyFobOnCenterConsole 2;
BA_ "InvalidValue" SG_ 282 MHU_Read_KeyFobOnCenterConsole "null";
BA_ "GenSigSendType" SG_ 283 TBOX_STAT_TerminalReq 2;
BA_ "GenSigStartValue" SG_ 283 TBOX_STAT_TerminalReq 6;
BA_ "InvalidValue" SG_ 283 TBOX_STAT_TerminalReq "7h";
BA_ "GenSigSendType" SG_ 283 TBOX_AuthCode_0x11B 2;
BA_ "InvalidValue" SG_ 283 TBOX_AuthCode_0x11B "null";
BA_ "GenSigSendType" SG_ 284 TBOX_FOTA_STAT_TerminalReq 2;
BA_ "InvalidValue" SG_ 284 TBOX_FOTA_STAT_TerminalReq "7h";
BA_ "GenSigTimeoutTime_ALL" SG_ 285 CCU_ERL_Rear 1000;
BA_ "InvalidValue" SG_ 285 CCU_ERL_Rear "null";
BA_ "GenSigStartValue" SG_ 285 CCU_EvapTempSet_Rear 50;
BA_ "GenSigTimeoutTime_ALL" SG_ 285 CCU_EvapTempSet_Rear 1000;
BA_ "InvalidValue" SG_ 285 CCU_EvapTempSet_Rear "null";
BA_ "GenSigTimeoutTime_ALL" SG_ 285 CCU_AirDistribFlapPos_Rear 1000;
BA_ "InvalidValue" SG_ 285 CCU_AirDistribFlapPos_Rear "null";
BA_ "GenSigTimeoutTime_ALL" SG_ 285 CCU_BlowerFltPwm_Rear 1000;
BA_ "InvalidValue" SG_ 285 CCU_BlowerFltPwm_Rear "null";
BA_ "GenSigStartValue" SG_ 285 CCU_DuctTargetTemp_Rear 80;
BA_ "GenSigTimeoutTime_ALL" SG_ 285 CCU_DuctTargetTemp_Rear 1000;
BA_ "InvalidValue" SG_ 285 CCU_DuctTargetTemp_Rear "null";
BA_ "GenSigTimeoutTime_ALL" SG_ 285 CCU_TempFlapPos_Rear 1000;
BA_ "InvalidValue" SG_ 285 CCU_TempFlapPos_Rear "null";
BA_ "GenSigTimeoutTime_ALL" SG_ 285 CCU_FanSpeed_Rear 1000;
BA_ "InvalidValue" SG_ 285 CCU_FanSpeed_Rear "Fh";
BA_ "GenSigStartValue" SG_ 285 CCUF_InteriorTemp_Rear 80;
BA_ "GenSigTimeoutTime_ALL" SG_ 285 CCUF_InteriorTemp_Rear 5000;
BA_ "InvalidValue" SG_ 285 CCUF_InteriorTemp_Rear "FFh";
BA_ "GenSigStartValue" SG_ 286 CCUR_DuctActRearFace 80;
BA_ "GenSigTimeoutTime_ALL" SG_ 286 CCUR_DuctActRearFace 1000;
BA_ "InvalidValue" SG_ 286 CCUR_DuctActRearFace "null";
BA_ "GenSigStartValue" SG_ 286 CCUR_DuctActRearFoot 80;
BA_ "GenSigTimeoutTime_ALL" SG_ 286 CCUR_DuctActRearFoot 1000;
BA_ "InvalidValue" SG_ 286 CCUR_DuctActRearFoot "null";
BA_ "GenSigStartValue" SG_ 286 CCUR_EvaporatorTemp 80;
BA_ "GenSigTimeoutTime_ALL" SG_ 286 CCUR_EvaporatorTemp 1000;
BA_ "InvalidValue" SG_ 286 CCUR_EvaporatorTemp "null";
BA_ "GenSigStartValue" SG_ 286 CCUR_InteriorTemp 80;
BA_ "GenSigTimeoutTime_ALL" SG_ 286 CCUR_InteriorTemp 1000;
BA_ "InvalidValue" SG_ 286 CCUR_InteriorTemp "null";
BA_ "GenSigTimeoutTime_ALL" SG_ 286 CCUR_AirDistribFeedback_Rear 1000;
BA_ "InvalidValue" SG_ 286 CCUR_AirDistribFeedback_Rear "null";
BA_ "GenSigTimeoutTime_ALL" SG_ 286 CCUR_TempFeedback_Rear 1000;
BA_ "InvalidValue" SG_ 286 CCUR_TempFeedback_Rear "null";
BA_ "GenSigTimeoutTime_ALL" SG_ 286 CCUR_BlowerFeedback_Rear 1000;
BA_ "InvalidValue" SG_ 286 CCUR_BlowerFeedback_Rear "null";
BA_ "GenSigSendType" SG_ 287 MHU_DrvInhibitSts 2;
BA_ "InvalidValue" SG_ 287 MHU_DrvInhibitSts "0h";
BA_ "GenSigSendType" SG_ 287 TBOX_AuthCode_0x11F 2;
BA_ "InvalidValue" SG_ 287 TBOX_AuthCode_0x11F "null";
BA_ "GenSigTimeoutTime_ALL" SG_ 290 CHKSM_CCU_REQUEST 1000;
BA_ "InvalidValue" SG_ 290 CHKSM_CCU_REQUEST "null";
BA_ "GenSigTimeoutTime_ALL" SG_ 290 ALV_CCU_REQUEST 1000;
BA_ "InvalidValue" SG_ 290 ALV_CCU_REQUEST "Fh";
BA_ "GenSigTimeoutTime_ALL" SG_ 290 CCU_REQ_MaxCool 1000;
BA_ "InvalidValue" SG_ 290 CCU_REQ_MaxCool "3h";
BA_ "GenSigStartValue" SG_ 290 CCU_REQ_MaxHeat 3;
BA_ "GenSigTimeoutTime_ALL" SG_ 290 CCU_REQ_MaxHeat 1000;
BA_ "InvalidValue" SG_ 290 CCU_REQ_MaxHeat "3h";
BA_ "GenSigStartValue" SG_ 290 CCU_REQ_ESSMotorControl 7;
BA_ "GenSigTimeoutTime_ALL" SG_ 290 CCU_REQ_ESSMotorControl 1000;
BA_ "InvalidValue" SG_ 290 CCU_REQ_ESSMotorControl "7h";
BA_ "GenSigTimeoutTime_ALL" SG_ 290 CCU_AC_PWM 1000;
BA_ "InvalidValue" SG_ 290 CCU_AC_PWM "7Fh";
BA_ "GenSigTimeoutTime_ALL" SG_ 295 CHKSM_ADAS_LDW_LKA 800;
BA_ "GenSigTimeoutTime_ALL" SG_ 295 ALV_ADAS_LDW_LKA 800;
BA_ "InvalidValue" SG_ 295 ALV_ADAS_LDW_LKA "Fh";
BA_ "GenSigTimeoutTime_ALL" SG_ 295 ADAS_ELKA_ON_feed 800;
BA_ "GenSigStartValue" SG_ 295 ADAS_ELKA_ON_feed 1;
BA_ "GenSigTimeoutTime_ALL" SG_ 295 ADAS_Mode1_status 800;
BA_ "InvalidValue" SG_ 295 ADAS_Mode1_status "3h";
BA_ "GenSigTimeoutTime_ALL" SG_ 295 ADAS_LA_sens_Feed 800;
BA_ "GenSigTimeoutTime_ALL" SG_ 295 ADAS_LDW_check 800;
BA_ "InvalidValue" SG_ 295 ADAS_LDW_check "3h";
BA_ "GenSigTimeoutTime_ALL" SG_ 295 ADAS_LKA_check 800;
BA_ "InvalidValue" SG_ 295 ADAS_LKA_check "3h";
BA_ "GenSigStartValue" SG_ 295 ADAS_LA_Mode_Feed 2;
BA_ "GenSigTimeoutTime_ALL" SG_ 295 ADAS_LA_Mode_Feed 800;
BA_ "InvalidValue" SG_ 295 ADAS_LA_Mode_Feed "4h";
BA_ "GenSigTimeoutTime_ALL" SG_ 296 CHKSM_ADAS_FCW_RCTA 500;
BA_ "GenSigTimeoutTime_ALL" SG_ 296 ALV_ADAS_FCW_RCTA 500;
BA_ "InvalidValue" SG_ 296 ALV_ADAS_FCW_RCTA "Fh";
BA_ "GenSigTimeoutTime_ALL" SG_ 296 ADAS_RCTA_IndLeft 500;
BA_ "GenSigTimeoutTime_ALL" SG_ 296 ADAS_RCTA_IndRight 500;
BA_ "GenSigTimeoutTime_ALL" SG_ 296 ADAS_IA_check 500;
BA_ "GenSigTimeoutTime_ALL" SG_ 296 ADAS_IA_Left_warning 500;
BA_ "InvalidValue" SG_ 296 ADAS_IA_Left_warning "3h";
BA_ "GenSigStartValue" SG_ 296 ADAS_FCW_state 1;
BA_ "GenSigTimeoutTime_ALL" SG_ 296 ADAS_FCW_state 500;
BA_ "GenSigTimeoutTime_ALL" SG_ 296 ADAS_IA_state 500;
BA_ "InvalidValue" SG_ 296 ADAS_IA_state "7h";
BA_ "GenSigTimeoutTime_ALL" SG_ 296 ADAS_FCW_check 500;
BA_ "InvalidValue" SG_ 296 ADAS_FCW_check "3h";
BA_ "GenSigTimeoutTime_ALL" SG_ 296 ADAS_IA_Right_warning 500;
BA_ "InvalidValue" SG_ 296 ADAS_IA_Right_warning "3h";
BA_ "GenSigTimeoutTime_ALL" SG_ 296 ADAS_IA_Mode_Feed 500;
BA_ "GenSigTimeoutTime_ALL" SG_ 296 ADAS_FCW_warning 500;
BA_ "InvalidValue" SG_ 296 ADAS_FCW_warning "3h";
BA_ "GenSigSendType" SG_ 303 CHKSM_BCM_TERMINAL 3;
BA_ "GenSigTimeoutTime_ALL" SG_ 303 CHKSM_BCM_TERMINAL 500;
BA_ "InvalidValue" SG_ 303 CHKSM_BCM_TERMINAL "null";
BA_ "GenSigSendType" SG_ 303 ALV_BCM_TERMINAL 3;
BA_ "GenSigTimeoutTime_ALL" SG_ 303 ALV_BCM_TERMINAL 500;
BA_ "InvalidValue" SG_ 303 ALV_BCM_TERMINAL "Fh";
BA_ "GenSigSendType" SG_ 303 ST_KL 3;
BA_ "GenSigTimeoutTime_ALL" SG_ 303 ST_KL 500;
BA_ "InvalidValue" SG_ 303 ST_KL "Fh";
BA_ "GenSigSendType" SG_ 303 ST_KL_KEY_VLD 3;
BA_ "GenSigTimeoutTime_ALL" SG_ 303 ST_KL_KEY_VLD 500;
BA_ "InvalidValue" SG_ 303 ST_KL_KEY_VLD "Fh";
BA_ "GenSigTimeoutTime_ALL" SG_ 303 STAT_AlcoholEngineStatus 500;
BA_ "InvalidValue" SG_ 303 STAT_AlcoholEngineStatus "3h";
BA_ "GenSigSendType" SG_ 303 ST_STCD_PENG 3;
BA_ "GenSigTimeoutTime_ALL" SG_ 303 ST_STCD_PENG 500;
BA_ "InvalidValue" SG_ 303 ST_STCD_PENG "3h";
BA_ "GenSigSendType" SG_ 303 ST_SSB 3;
BA_ "GenSigTimeoutTime_ALL" SG_ 303 ST_SSB 500;
BA_ "InvalidValue" SG_ 303 ST_SSB "3h";
BA_ "GenSigSendType" SG_ 303 RWDT_BLS 3;
BA_ "GenSigTimeoutTime_ALL" SG_ 303 RWDT_BLS 500;
BA_ "InvalidValue" SG_ 303 RWDT_BLS "Fh";
BA_ "GenSigSendType" SG_ 303 RQ_DRVG_RDI 3;
BA_ "GenSigTimeoutTime_ALL" SG_ 303 RQ_DRVG_RDI 500;
BA_ "InvalidValue" SG_ 303 RQ_DRVG_RDI "3h";
BA_ "GenSigTimeoutTime_ALL" SG_ 303 STAT_AlcoholIgnStatus 500;
BA_ "InvalidValue" SG_ 303 STAT_AlcoholIgnStatus "3h";
BA_ "GenSigSendType" SG_ 303 CTR_ENG_STOP 3;
BA_ "GenSigTimeoutTime_ALL" SG_ 303 CTR_ENG_STOP 500;
BA_ "InvalidValue" SG_ 303 CTR_ENG_STOP "3h";
BA_ "GenSigSendType" SG_ 303 ST_VEH_CON 3;
BA_ "GenSigTimeoutTime_ALL" SG_ 303 ST_VEH_CON 500;
BA_ "InvalidValue" SG_ 303 ST_VEH_CON "Fh";
BA_ "GenSigTimeoutTime_ALL" SG_ 306 Checksum_0x132 500;
BA_ "InvalidValue" SG_ 306 Checksum_0x132 "null";
BA_ "GenSigTimeoutTime_ALL" SG_ 306 Rolling_Counter_0x132 500;
BA_ "InvalidValue" SG_ 306 Rolling_Counter_0x132 "Fh";
BA_ "GenSigStartValue" SG_ 306 SRR_BSD_AudChime_Feed 1;
BA_ "GenSigTimeoutTime_ALL" SG_ 306 SRR_BSD_AudChime_Feed 500;
BA_ "InvalidValue" SG_ 306 SRR_BSD_AudChime_Feed "3h";
BA_ "GenSigTimeoutTime_ALL" SG_ 306 SRR_BSD_check 500;
BA_ "InvalidValue" SG_ 306 SRR_BSD_check "3h";
BA_ "GenSigTimeoutTime_ALL" SG_ 306 SRR_BSD_state 500;
BA_ "InvalidValue" SG_ 306 SRR_BSD_state "null";
BA_ "GenSigTimeoutTime_ALL" SG_ 306 SRR_BSD_IndLeft 500;
BA_ "InvalidValue" SG_ 306 SRR_BSD_IndLeft "null";
BA_ "GenSigTimeoutTime_ALL" SG_ 306 SRR_BSD_IndRight 500;
BA_ "InvalidValue" SG_ 306 SRR_BSD_IndRight "null";
BA_ "GenSigTimeoutTime_ALL" SG_ 306 SRR_BSD_SndWarn 500;
BA_ "InvalidValue" SG_ 306 SRR_BSD_SndWarn "null";
BA_ "GenSigStartValue" SG_ 306 SRR_BSD_Mode_Feed 1;
BA_ "GenSigTimeoutTime_ALL" SG_ 306 SRR_BSD_Mode_Feed 500;
BA_ "InvalidValue" SG_ 306 SRR_BSD_Mode_Feed "3h";
BA_ "InvalidValue" SG_ 307 ADAS_BSD_IndLeft "3h";
BA_ "GenSigTimeoutTime_ALL" SG_ 307 ADAS_BSD_IndLeft 500;
BA_ "InvalidValue" SG_ 307 ADAS_BSD_IndRight "3h";
BA_ "GenSigTimeoutTime_ALL" SG_ 307 ADAS_BSD_IndRight 500;
BA_ "GenSigTimeoutTime_ALL" SG_ 314 FCAM_ESA_Sts 100;
BA_ "GenSigSendType" SG_ 359 TWV1_N_Position 7;
BA_ "InvalidValue" SG_ 359 TWV1_N_Position "null";
BA_ "GenSigSendType" SG_ 359 TWV1_St_Feedback 7;
BA_ "InvalidValue" SG_ 359 TWV1_St_Feedback "null";
BA_ "GenSigSendType" SG_ 359 TWV1_Frm_Error 7;
BA_ "InvalidValue" SG_ 359 TWV1_Frm_Error "null";
BA_ "GenSigTimeoutTime_ALL" SG_ 360 Checksum_MHU_FEEDBACK_APA 1000;
BA_ "InvalidValue" SG_ 360 Checksum_MHU_FEEDBACK_APA "null";
BA_ "GenSigTimeoutTime_ALL" SG_ 360 Rolling_Counter_MHU_FEEDBACK_APA 1000;
BA_ "InvalidValue" SG_ 360 Rolling_Counter_MHU_FEEDBACK_APA "Fh";
BA_ "GenSigTimeoutTime_ALL" SG_ 360 MHU_AVM_ShowAVMReq 1000;
BA_ "InvalidValue" SG_ 360 MHU_AVM_ShowAVMReq "3h";
BA_ "GenSigTimeoutTime_ALL" SG_ 376 CHKSM_YSS_LongAcc 100;
BA_ "InvalidValue" SG_ 376 CHKSM_YSS_LongAcc "null";
BA_ "GenSigTimeoutTime_ALL" SG_ 376 ALV_YSS_LongAcc 100;
BA_ "InvalidValue" SG_ 376 ALV_YSS_LongAcc "Fh";
BA_ "GenSigTimeoutTime_ALL" SG_ 376 YSS_LONG_ACCUNFILTERED_QUAL 100;
BA_ "GenSigTimeoutTime_ALL" SG_ 376 YSS_LONG_ACC_UNFILTERED 100;
BA_ "InvalidValue" SG_ 376 YSS_LONG_ACC_UNFILTERED "FFFFh";
BA_ "GenSigTimeoutTime_ALL" SG_ 376 YSS_LONG_ACC_QUAL 100;
BA_ "GenSigTimeoutTime_ALL" SG_ 376 YSS_LONG_ACC 100;
BA_ "InvalidValue" SG_ 376 YSS_LONG_ACC "FFFFh";
BA_ "GenSigTimeoutTime_ALL" SG_ 381 CHKSM_YSS_YawRate 100;
BA_ "InvalidValue" SG_ 381 CHKSM_YSS_YawRate "null";
BA_ "GenSigTimeoutTime_ALL" SG_ 381 ALV_YSS_YawRate 100;
BA_ "InvalidValue" SG_ 381 ALV_YSS_YawRate "Fh";
BA_ "GenSigTimeoutTime_ALL" SG_ 381 YSS_YAW_RATEUNFILTERED_QUAL 100;
BA_ "GenSigTimeoutTime_ALL" SG_ 381 YSS_YAW_RATE_UNFILTERED 100;
BA_ "InvalidValue" SG_ 381 YSS_YAW_RATE_UNFILTERED "FFFh";
BA_ "GenSigTimeoutTime_ALL" SG_ 381 YSS_YAW_RATE_QUAL 100;
BA_ "GenSigTimeoutTime_ALL" SG_ 381 YSS_SC_STATUS 100;
BA_ "InvalidValue" SG_ 381 YSS_SC_STATUS "null";
BA_ "GenSigTimeoutTime_ALL" SG_ 381 YSS_YAW_RATE 100;
BA_ "InvalidValue" SG_ 381 YSS_YAW_RATE "FFFFh";
BA_ "GenSigStartValue" SG_ 381 YSS_TEMPERATURE 40;
BA_ "GenSigTimeoutTime_ALL" SG_ 381 YSS_TEMPERATURE 100;
BA_ "InvalidValue" SG_ 381 YSS_TEMPERATURE "FFh";
BA_ "GenSigTimeoutTime_ALL" SG_ 382 CHKSM_SAS_Sensor 200;
BA_ "InvalidValue" SG_ 382 CHKSM_SAS_Sensor "null";
BA_ "GenSigTimeoutTime_ALL" SG_ 382 ALV_SAS_Sensor 200;
BA_ "InvalidValue" SG_ 382 ALV_SAS_Sensor "Fh";
BA_ "GenSigTimeoutTime_ALL" SG_ 382 SAS_SASStsSnsr 200;
BA_ "InvalidValue" SG_ 382 SAS_SASStsSnsr "null";
BA_ "GenSigStartValue" SG_ 382 SAS_SteerWhlRotSpd 8192;
BA_ "GenSigTimeoutTime_ALL" SG_ 382 SAS_SteerWhlRotSpd 100;
BA_ "InvalidValue" SG_ 382 SAS_SteerWhlRotSpd "3FFFh";
BA_ "GenSigTimeoutTime_ALL" SG_ 382 SAS_SteerWhlRotSpdStatus 200;
BA_ "InvalidValue" SG_ 382 SAS_SteerWhlRotSpdStatus "null";
BA_ "GenSigTimeoutTime_ALL" SG_ 382 SAS_SASFailure 200;
BA_ "InvalidValue" SG_ 382 SAS_SASFailure "null";
BA_ "GenSigTimeoutTime_ALL" SG_ 382 SAS_Calibrated 100;
BA_ "InvalidValue" SG_ 382 SAS_Calibrated "null";
BA_ "GenSigTimeoutTime_ALL" SG_ 382 SAS_SteerWheelAngleValid 200;
BA_ "InvalidValue" SG_ 382 SAS_SteerWheelAngleValid "3h";
BA_ "GenSigTimeoutTime_ALL" SG_ 382 SAS_SteerWheelAngle 200;
BA_ "InvalidValue" SG_ 382 SAS_SteerWheelAngle "FFFFh";
BA_ "GenSigTimeoutTime_ALL" SG_ 385 CAM_CamSts 400;
BA_ "GenSigTimeoutTime_ALL" SG_ 385 CAM_AmbLi 400;
BA_ "GenSigTimeoutTime_ALL" SG_ 385 CAM_RoadIllmn 400;
BA_ "GenSigTimeoutTime_ALL" SG_ 385 CAM_Obj_TrfcStyle 400;
BA_ "GenSigTimeoutTime_ALL" SG_ 388 CHKSM_FCAM_BCM_Status 500;
BA_ "GenSigTimeoutTime_ALL" SG_ 388 ALIVE_FCAM_BCM_Status 500;
BA_ "InvalidValue" SG_ 388 ALIVE_FCAM_BCM_Status "Fh";
BA_ "GenSigTimeoutTime_ALL" SG_ 388 FCAM_BCM_IndicatorlightReq 500;
BA_ "GenSigTimeoutTime_ALL" SG_ 388 SECCAN_FCAM_BCM_Sts 500;
BA_ "GenSigTimeoutTime_ALL" SG_ 401 CAM_Obj1_ID 400;
BA_ "InvalidValue" SG_ 401 CAM_Obj1_ID "0";
BA_ "GenSigStartValue" SG_ 401 CAM_Obj1_HozlDst 511;
BA_ "GenSigTimeoutTime_ALL" SG_ 401 CAM_Obj1_HozlDst 400;
BA_ "InvalidValue" SG_ 401 CAM_Obj1_HozlDst "1FFh";
BA_ "GenSigTimeoutTime_ALL" SG_ 401 CAM_Obj1_Valid 400;
BA_ "InvalidValue" SG_ 401 CAM_Obj1_Valid "0";
BA_ "GenSigStartValue" SG_ 401 CAM_Obj1_HozlPosnRi 500;
BA_ "GenSigTimeoutTime_ALL" SG_ 401 CAM_Obj1_HozlPosnRi 400;
BA_ "InvalidValue" SG_ 401 CAM_Obj1_HozlPosnRi "3FFh";
BA_ "GenSigTimeoutTime_ALL" SG_ 401 CAM_Obj1_Typ 400;
BA_ "InvalidValue" SG_ 401 CAM_Obj1_Typ "0";
BA_ "GenSigStartValue" SG_ 401 CAM_Obj1_HozlPosnLe 500;
BA_ "GenSigTimeoutTime_ALL" SG_ 401 CAM_Obj1_HozlPosnLe 400;
BA_ "InvalidValue" SG_ 401 CAM_Obj1_HozlPosnLe "3FFh";
BA_ "GenSigStartValue" SG_ 401 CAM_Obj1_VertPosn 120;
BA_ "GenSigTimeoutTime_ALL" SG_ 401 CAM_Obj1_VertPosn 400;
BA_ "GenSigStartValue" SG_ 401 CAM_Obj1_HozlSpdLe 128;
BA_ "GenSigTimeoutTime_ALL" SG_ 401 CAM_Obj1_HozlSpdLe 400;
BA_ "InvalidValue" SG_ 401 CAM_Obj1_HozlSpdLe "null";
BA_ "GenSigStartValue" SG_ 401 CAM_Obj1_HozlSpdRi 128;
BA_ "GenSigTimeoutTime_ALL" SG_ 401 CAM_Obj1_HozlSpdRi 400;
BA_ "InvalidValue" SG_ 401 CAM_Obj1_HozlSpdRi "null";
BA_ "GenSigTimeoutTime_ALL" SG_ 404 CAM_Obj2_ID 400;
BA_ "InvalidValue" SG_ 404 CAM_Obj2_ID "0";
BA_ "GenSigStartValue" SG_ 404 CAM_Obj2_HozlDst 511;
BA_ "GenSigTimeoutTime_ALL" SG_ 404 CAM_Obj2_HozlDst 400;
BA_ "InvalidValue" SG_ 404 CAM_Obj2_HozlDst "1FFh";
BA_ "GenSigTimeoutTime_ALL" SG_ 404 CAM_Obj2_Valid 400;
BA_ "InvalidValue" SG_ 404 CAM_Obj2_Valid "0";
BA_ "GenSigStartValue" SG_ 404 CAM_Obj2_HozlPosnRi 500;
BA_ "GenSigTimeoutTime_ALL" SG_ 404 CAM_Obj2_HozlPosnRi 400;
BA_ "InvalidValue" SG_ 404 CAM_Obj2_HozlPosnRi "3FFh";
BA_ "GenSigTimeoutTime_ALL" SG_ 404 CAM_Obj2_Typ 400;
BA_ "InvalidValue" SG_ 404 CAM_Obj2_Typ "0";
BA_ "GenSigStartValue" SG_ 404 CAM_Obj2_HozlPosnLe 500;
BA_ "GenSigTimeoutTime_ALL" SG_ 404 CAM_Obj2_HozlPosnLe 400;
BA_ "InvalidValue" SG_ 404 CAM_Obj2_HozlPosnLe "3FFh";
BA_ "GenSigStartValue" SG_ 404 CAM_Obj2_VertPosn 120;
BA_ "GenSigTimeoutTime_ALL" SG_ 404 CAM_Obj2_VertPosn 400;
BA_ "GenSigStartValue" SG_ 404 CAM_Obj2_HozlSpdLe 128;
BA_ "GenSigTimeoutTime_ALL" SG_ 404 CAM_Obj2_HozlSpdLe 400;
BA_ "InvalidValue" SG_ 404 CAM_Obj2_HozlSpdLe "null";
BA_ "GenSigStartValue" SG_ 404 CAM_Obj2_HozlSpdRi 128;
BA_ "GenSigTimeoutTime_ALL" SG_ 404 CAM_Obj2_HozlSpdRi 400;
BA_ "InvalidValue" SG_ 404 CAM_Obj2_HozlSpdRi "null";
BA_ "GenSigTimeoutTime_ALL" SG_ 406 CAM_Obj3_ID 400;
BA_ "InvalidValue" SG_ 406 CAM_Obj3_ID "0";
BA_ "GenSigStartValue" SG_ 406 CAM_Obj3_HozlDst 511;
BA_ "GenSigTimeoutTime_ALL" SG_ 406 CAM_Obj3_HozlDst 400;
BA_ "InvalidValue" SG_ 406 CAM_Obj3_HozlDst "1FFh";
BA_ "GenSigTimeoutTime_ALL" SG_ 406 CAM_Obj3_Valid 400;
BA_ "InvalidValue" SG_ 406 CAM_Obj3_Valid "0";
BA_ "GenSigStartValue" SG_ 406 CAM_Obj3_HozlPosnRi 500;
BA_ "GenSigTimeoutTime_ALL" SG_ 406 CAM_Obj3_HozlPosnRi 400;
BA_ "InvalidValue" SG_ 406 CAM_Obj3_HozlPosnRi "3FFh";
BA_ "GenSigTimeoutTime_ALL" SG_ 406 CAM_Obj3_Typ 400;
BA_ "InvalidValue" SG_ 406 CAM_Obj3_Typ "0";
BA_ "GenSigStartValue" SG_ 406 CAM_Obj3_HozlPosnLe 500;
BA_ "GenSigTimeoutTime_ALL" SG_ 406 CAM_Obj3_HozlPosnLe 400;
BA_ "InvalidValue" SG_ 406 CAM_Obj3_HozlPosnLe "3FFh";
BA_ "GenSigStartValue" SG_ 406 CAM_Obj3_VertPosn 120;
BA_ "GenSigTimeoutTime_ALL" SG_ 406 CAM_Obj3_VertPosn 400;
BA_ "GenSigStartValue" SG_ 406 CAM_Obj3_HozlSpdLe 128;
BA_ "GenSigTimeoutTime_ALL" SG_ 406 CAM_Obj3_HozlSpdLe 400;
BA_ "InvalidValue" SG_ 406 CAM_Obj3_HozlSpdLe "null";
BA_ "GenSigStartValue" SG_ 406 CAM_Obj3_HozlSpdRi 128;
BA_ "GenSigTimeoutTime_ALL" SG_ 406 CAM_Obj3_HozlSpdRi 400;
BA_ "InvalidValue" SG_ 406 CAM_Obj3_HozlSpdRi "null";
BA_ "GenSigTimeoutTime_ALL" SG_ 410 CAM_Obj4_ID 400;
BA_ "InvalidValue" SG_ 410 CAM_Obj4_ID "0";
BA_ "GenSigStartValue" SG_ 410 CAM_Obj4_HozlDst 511;
BA_ "GenSigTimeoutTime_ALL" SG_ 410 CAM_Obj4_HozlDst 400;
BA_ "InvalidValue" SG_ 410 CAM_Obj4_HozlDst "1FFh";
BA_ "GenSigTimeoutTime_ALL" SG_ 410 CAM_Obj4_Valid 400;
BA_ "InvalidValue" SG_ 410 CAM_Obj4_Valid "0";
BA_ "GenSigStartValue" SG_ 410 CAM_Obj4_HozlPosnRi 500;
BA_ "GenSigTimeoutTime_ALL" SG_ 410 CAM_Obj4_HozlPosnRi 400;
BA_ "InvalidValue" SG_ 410 CAM_Obj4_HozlPosnRi "3FFh";
BA_ "GenSigTimeoutTime_ALL" SG_ 410 CAM_Obj4_Typ 400;
BA_ "InvalidValue" SG_ 410 CAM_Obj4_Typ "0";
BA_ "GenSigStartValue" SG_ 410 CAM_Obj4_HozlPosnLe 500;
BA_ "GenSigTimeoutTime_ALL" SG_ 410 CAM_Obj4_HozlPosnLe 400;
BA_ "InvalidValue" SG_ 410 CAM_Obj4_HozlPosnLe "3FFh";
BA_ "GenSigStartValue" SG_ 410 CAM_Obj4_VertPosn 120;
BA_ "GenSigTimeoutTime_ALL" SG_ 410 CAM_Obj4_VertPosn 400;
BA_ "GenSigStartValue" SG_ 410 CAM_Obj4_HozlSpdLe 128;
BA_ "GenSigTimeoutTime_ALL" SG_ 410 CAM_Obj4_HozlSpdLe 400;
BA_ "InvalidValue" SG_ 410 CAM_Obj4_HozlSpdLe "null";
BA_ "GenSigStartValue" SG_ 410 CAM_Obj4_HozlSpdRi 128;
BA_ "GenSigTimeoutTime_ALL" SG_ 410 CAM_Obj4_HozlSpdRi 400;
BA_ "InvalidValue" SG_ 410 CAM_Obj4_HozlSpdRi "null";
BA_ "GenSigTimeoutTime_ALL" SG_ 412 CAM_Obj5_ID 400;
BA_ "InvalidValue" SG_ 412 CAM_Obj5_ID "0";
BA_ "GenSigStartValue" SG_ 412 CAM_Obj5_HozlDst 511;
BA_ "GenSigTimeoutTime_ALL" SG_ 412 CAM_Obj5_HozlDst 400;
BA_ "InvalidValue" SG_ 412 CAM_Obj5_HozlDst "1FFh";
BA_ "GenSigTimeoutTime_ALL" SG_ 412 CAM_Obj5_Valid 400;
BA_ "InvalidValue" SG_ 412 CAM_Obj5_Valid "0";
BA_ "GenSigStartValue" SG_ 412 CAM_Obj5_HozlPosnRi 500;
BA_ "GenSigTimeoutTime_ALL" SG_ 412 CAM_Obj5_HozlPosnRi 400;
BA_ "InvalidValue" SG_ 412 CAM_Obj5_HozlPosnRi "3FFh";
BA_ "GenSigTimeoutTime_ALL" SG_ 412 CAM_Obj5_Typ 400;
BA_ "InvalidValue" SG_ 412 CAM_Obj5_Typ "0";
BA_ "GenSigStartValue" SG_ 412 CAM_Obj5_HozlPosnLe 500;
BA_ "GenSigTimeoutTime_ALL" SG_ 412 CAM_Obj5_HozlPosnLe 400;
BA_ "InvalidValue" SG_ 412 CAM_Obj5_HozlPosnLe "3FFh";
BA_ "GenSigStartValue" SG_ 412 CAM_Obj5_VertPosn 120;
BA_ "GenSigTimeoutTime_ALL" SG_ 412 CAM_Obj5_VertPosn 400;
BA_ "GenSigStartValue" SG_ 412 CAM_Obj5_HozlSpdLe 128;
BA_ "GenSigTimeoutTime_ALL" SG_ 412 CAM_Obj5_HozlSpdLe 400;
BA_ "InvalidValue" SG_ 412 CAM_Obj5_HozlSpdLe "null";
BA_ "GenSigStartValue" SG_ 412 CAM_Obj5_HozlSpdRi 128;
BA_ "GenSigTimeoutTime_ALL" SG_ 412 CAM_Obj5_HozlSpdRi 400;
BA_ "InvalidValue" SG_ 412 CAM_Obj5_HozlSpdRi "null";
BA_ "GenSigTimeoutTime_ALL" SG_ 413 CAM_Obj6_ID 400;
BA_ "InvalidValue" SG_ 413 CAM_Obj6_ID "0";
BA_ "GenSigStartValue" SG_ 413 CAM_Obj6_HozlDst 511;
BA_ "GenSigTimeoutTime_ALL" SG_ 413 CAM_Obj6_HozlDst 400;
BA_ "InvalidValue" SG_ 413 CAM_Obj6_HozlDst "1FFh";
BA_ "GenSigTimeoutTime_ALL" SG_ 413 CAM_Obj6_Valid 400;
BA_ "InvalidValue" SG_ 413 CAM_Obj6_Valid "0";
BA_ "GenSigStartValue" SG_ 413 CAM_Obj6_HozlPosnRi 500;
BA_ "GenSigTimeoutTime_ALL" SG_ 413 CAM_Obj6_HozlPosnRi 400;
BA_ "InvalidValue" SG_ 413 CAM_Obj6_HozlPosnRi "3FFh";
BA_ "GenSigTimeoutTime_ALL" SG_ 413 CAM_Obj6_Typ 400;
BA_ "InvalidValue" SG_ 413 CAM_Obj6_Typ "0";
BA_ "GenSigStartValue" SG_ 413 CAM_Obj6_HozlPosnLe 500;
BA_ "GenSigTimeoutTime_ALL" SG_ 413 CAM_Obj6_HozlPosnLe 400;
BA_ "InvalidValue" SG_ 413 CAM_Obj6_HozlPosnLe "3FFh";
BA_ "GenSigStartValue" SG_ 413 CAM_Obj6_VertPosn 120;
BA_ "GenSigTimeoutTime_ALL" SG_ 413 CAM_Obj6_VertPosn 400;
BA_ "GenSigStartValue" SG_ 413 CAM_Obj6_HozlSpdLe 128;
BA_ "GenSigTimeoutTime_ALL" SG_ 413 CAM_Obj6_HozlSpdLe 400;
BA_ "InvalidValue" SG_ 413 CAM_Obj6_HozlSpdLe "null";
BA_ "GenSigStartValue" SG_ 413 CAM_Obj6_HozlSpdRi 128;
BA_ "GenSigTimeoutTime_ALL" SG_ 413 CAM_Obj6_HozlSpdRi 400;
BA_ "InvalidValue" SG_ 413 CAM_Obj6_HozlSpdRi "null";
BA_ "GenSigTimeoutTime_ALL" SG_ 414 CAM_Obj7_ID 400;
BA_ "InvalidValue" SG_ 414 CAM_Obj7_ID "0";
BA_ "GenSigStartValue" SG_ 414 CAM_Obj7_HozlDst 511;
BA_ "GenSigTimeoutTime_ALL" SG_ 414 CAM_Obj7_HozlDst 400;
BA_ "InvalidValue" SG_ 414 CAM_Obj7_HozlDst "1FFh";
BA_ "GenSigTimeoutTime_ALL" SG_ 414 CAM_Obj7_Valid 400;
BA_ "InvalidValue" SG_ 414 CAM_Obj7_Valid "0";
BA_ "GenSigStartValue" SG_ 414 CAM_Obj7_HozlPosnRi 500;
BA_ "GenSigTimeoutTime_ALL" SG_ 414 CAM_Obj7_HozlPosnRi 400;
BA_ "InvalidValue" SG_ 414 CAM_Obj7_HozlPosnRi "3FFh";
BA_ "GenSigTimeoutTime_ALL" SG_ 414 CAM_Obj7_Typ 400;
BA_ "InvalidValue" SG_ 414 CAM_Obj7_Typ "0";
BA_ "GenSigStartValue" SG_ 414 CAM_Obj7_HozlPosnLe 500;
BA_ "GenSigTimeoutTime_ALL" SG_ 414 CAM_Obj7_HozlPosnLe 400;
BA_ "InvalidValue" SG_ 414 CAM_Obj7_HozlPosnLe "3FFh";
BA_ "GenSigStartValue" SG_ 414 CAM_Obj7_VertPosn 120;
BA_ "GenSigTimeoutTime_ALL" SG_ 414 CAM_Obj7_VertPosn 400;
BA_ "GenSigStartValue" SG_ 414 CAM_Obj7_HozlSpdLe 128;
BA_ "GenSigTimeoutTime_ALL" SG_ 414 CAM_Obj7_HozlSpdLe 400;
BA_ "InvalidValue" SG_ 414 CAM_Obj7_HozlSpdLe "null";
BA_ "GenSigStartValue" SG_ 414 CAM_Obj7_HozlSpdRi 128;
BA_ "GenSigTimeoutTime_ALL" SG_ 414 CAM_Obj7_HozlSpdRi 400;
BA_ "InvalidValue" SG_ 414 CAM_Obj7_HozlSpdRi "null";
BA_ "GenSigTimeoutTime_ALL" SG_ 415 CAM_Obj8_ID 400;
BA_ "InvalidValue" SG_ 415 CAM_Obj8_ID "0";
BA_ "GenSigStartValue" SG_ 415 CAM_Obj8_HozlDst 511;
BA_ "GenSigTimeoutTime_ALL" SG_ 415 CAM_Obj8_HozlDst 400;
BA_ "InvalidValue" SG_ 415 CAM_Obj8_HozlDst "1FFh";
BA_ "GenSigTimeoutTime_ALL" SG_ 415 CAM_Obj8_Valid 400;
BA_ "InvalidValue" SG_ 415 CAM_Obj8_Valid "0";
BA_ "GenSigStartValue" SG_ 415 CAM_Obj8_HozlPosnRi 500;
BA_ "GenSigTimeoutTime_ALL" SG_ 415 CAM_Obj8_HozlPosnRi 400;
BA_ "InvalidValue" SG_ 415 CAM_Obj8_HozlPosnRi "3FFh";
BA_ "GenSigTimeoutTime_ALL" SG_ 415 CAM_Obj8_Typ 400;
BA_ "InvalidValue" SG_ 415 CAM_Obj8_Typ "0";
BA_ "GenSigStartValue" SG_ 415 CAM_Obj8_HozlPosnLe 500;
BA_ "GenSigTimeoutTime_ALL" SG_ 415 CAM_Obj8_HozlPosnLe 400;
BA_ "InvalidValue" SG_ 415 CAM_Obj8_HozlPosnLe "3FFh";
BA_ "GenSigStartValue" SG_ 415 CAM_Obj8_VertPosn 120;
BA_ "GenSigTimeoutTime_ALL" SG_ 415 CAM_Obj8_VertPosn 400;
BA_ "GenSigStartValue" SG_ 415 CAM_Obj8_HozlSpdLe 128;
BA_ "GenSigTimeoutTime_ALL" SG_ 415 CAM_Obj8_HozlSpdLe 400;
BA_ "InvalidValue" SG_ 415 CAM_Obj8_HozlSpdLe "null";
BA_ "GenSigStartValue" SG_ 415 CAM_Obj8_HozlSpdRi 128;
BA_ "GenSigTimeoutTime_ALL" SG_ 415 CAM_Obj8_HozlSpdRi 400;
BA_ "InvalidValue" SG_ 415 CAM_Obj8_HozlSpdRi "null";
BA_ "GenSigTimeoutTime_ALL" SG_ 417 CHSKM_V_VEH 200;
BA_ "InvalidValue" SG_ 417 CHSKM_V_VEH "null";
BA_ "GenSigTimeoutTime_ALL" SG_ 417 ALIV_V_VEH 200;
BA_ "InvalidValue" SG_ 417 ALIV_V_VEH "Fh";
BA_ "GenSigTimeoutTime_ALL" SG_ 417 V_VEH_COG 200;
BA_ "InvalidValue" SG_ 417 V_VEH_COG "FFFFh";
BA_ "GenSigTimeoutTime_ALL" SG_ 417 DVCO_VEH 200;
BA_ "InvalidValue" SG_ 417 DVCO_VEH "7h";
BA_ "GenSigStartValue" SG_ 417 QU_V_VEH_COG 8;
BA_ "GenSigTimeoutTime_ALL" SG_ 417 QU_V_VEH_COG 200;
BA_ "InvalidValue" SG_ 417 QU_V_VEH_COG "Fh";
BA_ "GenSigTimeoutTime_ALL" SG_ 504 CHKSM_EDS_OutPut_FR 400;
BA_ "InvalidValue" SG_ 504 CHKSM_EDS_OutPut_FR "null";
BA_ "GenSigTimeoutTime_ALL" SG_ 504 ALV_EDS_OutPut_FR 400;
BA_ "InvalidValue" SG_ 504 ALV_EDS_OutPut_FR "Fh";
BA_ "GenSigTimeoutTime_ALL" SG_ 504 EDS_Work_STS_FR 200;
BA_ "InvalidValue" SG_ 504 EDS_Work_STS_FR "Fh";
BA_ "GenSigStartValue" SG_ 504 EDS_Spd_FR 20000;
BA_ "GenSigTimeoutTime_ALL" SG_ 504 EDS_Spd_FR 400;
BA_ "InvalidValue" SG_ 504 EDS_Spd_FR "FFFFh";
BA_ "GenSigTimeoutTime_ALL" SG_ 504 EDS_output_trqValid_FR 200;
BA_ "InvalidValue" SG_ 504 EDS_output_trqValid_FR "null";
BA_ "GenSigTimeoutTime_ALL" SG_ 504 EDS_MotorDriveSts_FR 400;
BA_ "InvalidValue" SG_ 504 EDS_MotorDriveSts_FR "3h";
BA_ "GenSigTimeoutTime_ALL" SG_ 504 EDS_powoff_req_FR 200;
BA_ "InvalidValue" SG_ 504 EDS_powoff_req_FR "null";
BA_ "GenSigTimeoutTime_ALL" SG_ 504 EDS_SpdValid_FR 200;
BA_ "InvalidValue" SG_ 504 EDS_SpdValid_FR "null";
BA_ "GenSigStartValue" SG_ 504 EDS_output_trq_FR 2000;
BA_ "GenSigTimeoutTime_ALL" SG_ 504 EDS_output_trq_FR 200;
BA_ "InvalidValue" SG_ 504 EDS_output_trq_FR "FFFFh";
BA_ "GenSigTimeoutTime_ALL" SG_ 504 EDS_VCU_6SO_flag_FWD 400;
BA_ "InvalidValue" SG_ 504 EDS_VCU_6SO_flag_FWD "null";
BA_ "GenSigTimeoutTime_ALL" SG_ 505 CHKSM_EDS_OutPut_RR 400;
BA_ "InvalidValue" SG_ 505 CHKSM_EDS_OutPut_RR "null";
BA_ "GenSigTimeoutTime_ALL" SG_ 505 ALV_EDS_OutPut_RR 400;
BA_ "InvalidValue" SG_ 505 ALV_EDS_OutPut_RR "Fh";
BA_ "GenSigTimeoutTime_ALL" SG_ 505 EDS_Work_STS_RR 400;
BA_ "InvalidValue" SG_ 505 EDS_Work_STS_RR "Fh";
BA_ "GenSigStartValue" SG_ 505 EDS_Spd_RR 20000;
BA_ "GenSigTimeoutTime_ALL" SG_ 505 EDS_Spd_RR 400;
BA_ "InvalidValue" SG_ 505 EDS_Spd_RR "FFFFh";
BA_ "GenSigTimeoutTime_ALL" SG_ 505 EDS_output_trqValid_RR 400;
BA_ "InvalidValue" SG_ 505 EDS_output_trqValid_RR "null";
BA_ "GenSigTimeoutTime_ALL" SG_ 505 EDS_MotorDriveSts_RR 400;
BA_ "InvalidValue" SG_ 505 EDS_MotorDriveSts_RR "3h";
BA_ "GenSigTimeoutTime_ALL" SG_ 505 EDS_powoff_req_RR 400;
BA_ "InvalidValue" SG_ 505 EDS_powoff_req_RR "null";
BA_ "GenSigTimeoutTime_ALL" SG_ 505 EDS_SpdValid_RR 200;
BA_ "InvalidValue" SG_ 505 EDS_SpdValid_RR "null";
BA_ "GenSigStartValue" SG_ 505 EDS_output_trq_RR 2000;
BA_ "GenSigTimeoutTime_ALL" SG_ 505 EDS_output_trq_RR 200;
BA_ "InvalidValue" SG_ 505 EDS_output_trq_RR "FFFFh";
BA_ "GenSigTimeoutTime_ALL" SG_ 505 EDS_VCU_6SO_flag_RWD 400;
BA_ "InvalidValue" SG_ 505 EDS_VCU_6SO_flag_RWD "null";
BA_ "GenSigTimeoutTime_ALL" SG_ 519 SR_Undervoltage_Fault_Sts 500;
BA_ "InvalidValue" SG_ 519 SR_Undervoltage_Fault_Sts "null";
BA_ "GenSigTimeoutTime_ALL" SG_ 519 SR_Overvoltage_Fault_Sts 500;
BA_ "InvalidValue" SG_ 519 SR_Overvoltage_Fault_Sts "null";
BA_ "GenSigTimeoutTime_ALL" SG_ 519 SR_SLEEP_RQ 500;
BA_ "InvalidValue" SG_ 519 SR_SLEEP_RQ "null";
BA_ "GenSigTimeoutTime_ALL" SG_ 519 SR_Position 500;
BA_ "InvalidValue" SG_ 519 SR_Position "null";
BA_ "GenSigTimeoutTime_ALL" SG_ 519 SR_Motor_Running_Sts 500;
BA_ "InvalidValue" SG_ 519 SR_Motor_Running_Sts "null";
BA_ "GenSigTimeoutTime_ALL" SG_ 519 SR_MotorReverse_Fault_Sts 500;
BA_ "InvalidValue" SG_ 519 SR_MotorReverse_Fault_Sts "null";
BA_ "GenSigTimeoutTime_ALL" SG_ 519 SR_Hall_Fault_Sts 500;
BA_ "InvalidValue" SG_ 519 SR_Hall_Fault_Sts "null";
BA_ "GenSigTimeoutTime_ALL" SG_ 519 SR_Normalisation_Sts 500;
BA_ "InvalidValue" SG_ 519 SR_Normalisation_Sts "null";
BA_ "GenSigTimeoutTime_ALL" SG_ 519 SR_Relay_Fault 500;
BA_ "InvalidValue" SG_ 519 SR_Relay_Fault "null";
BA_ "GenSigTimeoutTime_ALL" SG_ 519 SR_Commu_Fault_Sts 500;
BA_ "InvalidValue" SG_ 519 SR_Commu_Fault_Sts "null";
BA_ "GenSigTimeoutTime_ALL" SG_ 519 SR_Initialisation_Status 500;
BA_ "InvalidValue" SG_ 519 SR_Initialisation_Status "null";
BA_ "GenSigTimeoutTime_ALL" SG_ 519 SR_Ctrl_Result 500;
BA_ "InvalidValue" SG_ 519 SR_Ctrl_Result "null";
BA_ "GenSigTimeoutTime_ALL" SG_ 519 SR_ThermalProtection_Fault_Sts 500;
BA_ "InvalidValue" SG_ 519 SR_ThermalProtection_Fault_Sts "null";
BA_ "GenSigTimeoutTime_ALL" SG_ 519 SR_Posit_Percentage 500;
BA_ "InvalidValue" SG_ 519 SR_Posit_Percentage "7Fh";
BA_ "GenSigTimeoutTime_ALL" SG_ 519 SR_Operation_Stat 500;
BA_ "InvalidValue" SG_ 519 SR_Operation_Stat "null";
BA_ "GenSigTimeoutTime_ALL" SG_ 519 SR_Error_RSP 500;
BA_ "InvalidValue" SG_ 519 SR_Error_RSP "null";
BA_ "GenSigTimeoutTime_ALL" SG_ 519 BCM_AutoSunroof_Sts 500;
BA_ "GenSigStartValue" SG_ 519 BCM_AutoSunroof_Sts 2;
BA_ "InvalidValue" SG_ 519 BCM_AutoSunroof_Sts "3h";
BA_ "GenSigTimeoutTime_ALL" SG_ 520 SS_MotorReverse_Fault_Status 500;
BA_ "InvalidValue" SG_ 520 SS_MotorReverse_Fault_Status "null";
BA_ "GenSigTimeoutTime_ALL" SG_ 520 SS_Motor_Running_Status 500;
BA_ "InvalidValue" SG_ 520 SS_Motor_Running_Status "null";
BA_ "GenSigTimeoutTime_ALL" SG_ 520 SS_Position 500;
BA_ "InvalidValue" SG_ 520 SS_Position "null";
BA_ "GenSigTimeoutTime_ALL" SG_ 520 SS_SLEEP_RQ 500;
BA_ "InvalidValue" SG_ 520 SS_SLEEP_RQ "null";
BA_ "GenSigTimeoutTime_ALL" SG_ 520 SS_Undervoltage_Fault_Status 500;
BA_ "InvalidValue" SG_ 520 SS_Undervoltage_Fault_Status "null";
BA_ "GenSigTimeoutTime_ALL" SG_ 520 SS_Ctrl_Result 500;
BA_ "InvalidValue" SG_ 520 SS_Ctrl_Result "null";
BA_ "GenSigTimeoutTime_ALL" SG_ 520 SS_Overvoltage_Fault_Status 500;
BA_ "InvalidValue" SG_ 520 SS_Overvoltage_Fault_Status "null";
BA_ "GenSigTimeoutTime_ALL" SG_ 520 SS_Relay_Fault 500;
BA_ "InvalidValue" SG_ 520 SS_Relay_Fault "null";
BA_ "GenSigTimeoutTime_ALL" SG_ 520 SS_Normalisation_Status 500;
BA_ "InvalidValue" SG_ 520 SS_Normalisation_Status "null";
BA_ "GenSigTimeoutTime_ALL" SG_ 520 SS_Hall_Fault_Status 500;
BA_ "InvalidValue" SG_ 520 SS_Hall_Fault_Status "null";
BA_ "GenSigTimeoutTime_ALL" SG_ 520 SS_Commu_Fault_Status 500;
BA_ "InvalidValue" SG_ 520 SS_Commu_Fault_Status "null";
BA_ "GenSigTimeoutTime_ALL" SG_ 520 SS_Initialisation_Status 500;
BA_ "InvalidValue" SG_ 520 SS_Initialisation_Status "null";
BA_ "GenSigTimeoutTime_ALL" SG_ 520 SS_Posit_Percentage 500;
BA_ "InvalidValue" SG_ 520 SS_Posit_Percentage "7Fh";
BA_ "GenSigTimeoutTime_ALL" SG_ 520 SS_ThermalProtection_Flt_Sts 500;
BA_ "InvalidValue" SG_ 520 SS_ThermalProtection_Flt_Sts "null";
BA_ "GenSigTimeoutTime_ALL" SG_ 520 SS_Operation_State 500;
BA_ "InvalidValue" SG_ 520 SS_Operation_State "null";
BA_ "GenSigTimeoutTime_ALL" SG_ 520 SECCAN_SunshadeSts 500;
BA_ "InvalidValue" SG_ 520 SECCAN_SunshadeSts "null";
BA_ "GenSigTimeoutTime_ALL" SG_ 520 SS_Error_RSP 500;
BA_ "InvalidValue" SG_ 520 SS_Error_RSP "null";
VAL_ 133 ACM_Crash_Sts 0 "No_Event" 1 "Crash_Detected" ;
VAL_ 133 ACM_Airbag_Deployment_Status 0 "No_Airbag_Deployment" 1 "Airbag_Deployment" ;
VAL_ 133 ACM_Crash_Intensity 0 "No_Crash" 1 "Crash_Intensity_1" 2 "Crash_Intensity_2" 3 "Crash_Intensity_3" ;
VAL_ 133 ACM_Front_Crash 0 "No_Event" 1 "Front_Crash_Detected" ;
VAL_ 133 ACM_DriverSide_Crash 0 "No_Event" 1 "Driverside_Crash_Detected" ;
VAL_ 133 ACM_PassSide_Crash 0 "No_Event" 1 "PasSide_Crash_Detected" ;
VAL_ 133 ACM_Rear_Crash 0 "No_Event" 1 "Rear_Crash_Detected" ;
VAL_ 133 ACM_Rollover_Crash 0 "No_Event" 1 "Rollover_Crash_Detected" ;
VAL_ 149 STAT_ABS 0 "No error" 1 "Error Full functionality of ABS is not available" 2 "Reserved" 3 "Signal invalid" ;
VAL_ 149 ABS_Active 0 "Inactive" 1 "Active" 2 "Reserved" 3 "Signal invalid" ;
VAL_ 149 AYC_Active 0 "Inactive" 1 "Active" 2 "Reserved" 3 "Signal invalid" ;
VAL_ 149 ASR_Active 0 "Inactive" 1 "Active" 2 "Reserved" 3 "Signal invalid" ;
VAL_ 149 STAT_DSC 0 "IDB normal" 1 "Traction Mode" 2 "IDB-OFF" 3 "Signal invalid" ;
VAL_ 149 DSC_Active 0 "Inactive" 1 "Active" 2 "Reserved" 3 "Signal invalid" ;
VAL_ 149 HBA_ActiveSignal 0 "Inactive" 1 "Active" 2 "Reserved" 3 "Signal invalid" ;
VAL_ 149 ARM_ActiveSignal 0 "Inactive" 1 "Active" 2 "Reserved" 3 "Signal invalid" ;
VAL_ 149 STAT_AutoHazardBlinking 0 "AutoHazardBlinking OFF" 1 "AutoHazardBlinking ON" 2 "Reserved" 3 "Signal invalid" ;
VAL_ 149 MSR_Active 0 "Inactive" 1 "Active" 2 "Reserved" 3 "Signal invalid" ;
VAL_ 149 HSA_ActiveSignal 0 "Inactive" 1 "Active" 2 "Reserved" 3 "Signal invalid" ;
VAL_ 149 EPBi_ECD_ActiveSignal 0 "Function supported by EPBi active signal" 1 "Function supported by EPBi no active" 2 "Reserved" 3 "Signal invalid" ;
VAL_ 149 TSM_Active 0 "Not active" 1 "Active" 2 "No trailer" 3 "Invalid" ;
VAL_ 149 HAS_Available 0 "No error" 1 "Error. Functionality of Hiil Hold is not available" 2 "Reserved" 3 "Signal invalid" ;
VAL_ 149 STAT_EBD 0 "No error" 1 "Error . Functionality of EBD is not available" 2 "Reserved" 3 "Signal invalid" ;
VAL_ 149 EBD_Active 0 "Inactive" 1 "Active" 2 "Reserved" 3 "Signal invalid" ;
VAL_ 149 ST_BRG_MSA 0 "vehicle is not held at speed 0 by the brake" 1 "vehicle is held at speed 0 by the brake" 14 "functions reports error" 15 "signal invalid" ;
VAL_ 217 VCU_HVsystem_status 0 "Not ready" 1 "HV On" 2 "ReadyToDrive" 3 "Charging" 4 "Error" 5 "Reserved" 6 "Reserved" 7 "Reserved" ;
VAL_ 217 VCU_ACPD_Percent_Valid 0 "Valid" 1 "Invalid" ;
VAL_ 217 VCU_ACTGear 0 "P" 1 "R" 2 "N" 3 "D" 4 "Reserved" 5 "Reserved" 6 "Reserved" 7 "Fault" ;
VAL_ 217 VCU_ACTGearValid 0 "Valid" 1 "Invalid" ;
VAL_ 217 VCU_ACT_DriveMode 0 "Normal mode" 1 "ECO mode" 2 "Sport mode" 3 "Reserved" 4 "Reserved" 5 "Reserved" 6 "Reserved" 7 "Invalid" ;
VAL_ 217 VCU_ACT_DriveMode_Valid 0 "Valid" 1 "Invalid" ;
VAL_ 217 VCU_HV_DRVsystem_status 0 "Not available" 1 "Normal" 2 "Degration" 3 "Limphome" 4 "Error" 5 "Reserved" 6 "Reserved" 7 "Reserved" ;
VAL_ 217 VCU_Recu_BrakeLight_ON_Req 0 "Brake light OFF" 1 "Brake light ON" 2 "Reserved" 3 "Signal not available" ;
VAL_ 256 MHU_UserProfileId 0 "User 1 - Guess mode" 1 "User 2 - Valet mode" 2 "User 3" 3 "User 4" 4 "User 5" 5 "User 6" 6 "User 7" 7 "User 8" 8 "User 9" 9 "User 10" 15 "Invalid Value" ;
VAL_ 256 MHU_Connectivity_Status 0 "Init" 1 "No Connection" 2 "LTE Internet Connection" 3 "WIFI Internet Establish" 4 "WIFI + LTE Connection" 5 "Reserved" 6 "Reserved" 7 "Reserved" ;
VAL_ 258 STAT_CL30s_Light_L 0 "OFF" 1 "ON" 2 "Failure" 3 "Signal invalid" ;
VAL_ 258 STAT_CL30s_L 0 "OFF" 1 "ON" 2 "Failure" 3 "Signal invalid" ;
VAL_ 258 STAT_CL15Wup_L 0 "OFF" 1 "ON" 2 "Failure" 3 "Signal invalid" ;
VAL_ 258 STAT_CrankRelayHW_BCM 0 "OFF" 1 "ON" 2 "Reserved" 3 "Signal invalid" ;
VAL_ 259 REQ_ConsumerControlSeatMassage 0 "Reduction not active" 1 "Reduction active" 2 "Reserved" 3 "Signal invalid";
VAL_ 259 REQ_ConsumerControlWirelessCharg 0 "Reduction not activ" 1 "Reduction activ" 2 "Reserved" 3 "Signal invalid" ;
VAL_ 259 REQ_ConsumerControlAudioVolumeCo 0 "No reduction" 1 "Level 1" 2 "Level 2" 3 "Reserved" 4 "Reserved" 5 "Reserved" 6 "Reserved" 7 "Signal invalid" ;
VAL_ 259 REQ_CCU_PTC_Limitation 0 "Step 0" 1 "Step 1" 2 "Step 2" 3 "Step 3" 4 "Reserved" 5 "Reserved" 6 "Reserved" 7 "Signal invalid" ;
VAL_ 259 REQ_ConsumerControlRearDefrost 0 "Reduction not activ" 1 "Reduction activ" 2 "Reserved" 3 "Signal invalid" ;
VAL_ 260 SOH_SUL 255 "Signal invalid" ;
VAL_ 260 SOH_SUL_STATE 0 "Not learned" 1 "Learned" 2 "Reserved" 3 "Signal invalid" ;
VAL_ 260 SOC_STATE 0 "deviation > 15% " 1 "deviation < 15%" 2 "deviation < 10%" 3 "invalid" ;
VAL_ 260 Resp_Error 0 "No Error" 1 "Error" ;
VAL_ 260 FLAG_INCONSTENCY 0 "No battery inconsistency" 1 "Battery inconsistency" ;
VAL_ 260 EBS_error 0 "No Error" 1 "Error" ;
VAL_ 260 FLAG_DISCONNECT 0 "No battery disconnection" 1 "Battery disconnection" ;
VAL_ 260 BCM_LV_Batt_Charging_Req 0 "Disable " 1 "Enable" ;
VAL_ 260 IBATT_QUIESCENT 253 "Outside quiescent current range" 254 "Reserved" 255 "Invalid" ;
VAL_ 261 BCM_STAT_TrunkAjar 0 "Closed" 1 "Opened" 2 "Reserved" 3 "Signal invalid" ;
VAL_ 261 BCM_STAT_DoorAjarFL 0 "Closed" 1 "Opened" 2 "Reserved" 3 "Signal invalid" ;
VAL_ 261 BCM_STAT_DoorAjarFR 0 "Closed" 1 "Opened" 2 "Reserved" 3 "Signal invalid" ;
VAL_ 261 BCM_STAT_DoorAjarRL 0 "Closed" 1 "Opened" 2 "Reserved" 3 "Signal invalid" ;
VAL_ 261 BCM_STAT_DoorAjarRR 0 "Closed" 1 "Opened" 2 "Reserved" 3 "Signal invalid" ;
VAL_ 261 BCM_STAT_BonnetAjar 0 "Closed" 1 "Opened" 2 "Reserved" 3 "Signal invalid" ;
VAL_ 262 BCM_DayRunningLampSts 0 "OFF" 1 "ON" 2 "Fault (Reserved)" 3 "Signal Invalid" ;
VAL_ 262 BCM_ReverseLightSts 0 "OFF" 1 "ON" 2 "Fault (Reserved)" 3 "Signal Invalid" ;
VAL_ 262 BCM_StopLightSts 0 "OFF" 1 "ON" 2 "Fault (Reserved)" 3 "Signal Invalid" ;
VAL_ 262 BCM_LicensePlateLightSts 0 "OFF" 1 "ON" 2 "Fault (Reserved)" 3 "Signal Invalid" ;
VAL_ 262 BCM_Fr_Dimming_dome_lampSts 0 "OFF" 1 "ON" 2 "Fault (Reserved)" 3 "Signal Invalid" ;
VAL_ 262 BCM_Rr_Dimming_dome_lampSts 0 "OFF" 1 "ON" 2 "Fault (Reserved)" 3 "Signal Invalid" ;
VAL_ 262 BCM_STAT_InteriorLight 0 "OFF" 1 "ON" 2 "Reserved" 3 "Signal invalid" ;
VAL_ 262 BCM_STAT_LightActivation 0 "OFF" 1 "PositionLight" 2 "LowBeam" 3 "AutoLight" 4 "Reserved" 5 "Reserved" 6 "Reserved" 7 "Signal invalid" ;
VAL_ 262 BCM_HighBeamSts 0 "OFF" 1 "ON" 2 "Fault (Reserved)" 3 "Signal Invalid" ;
VAL_ 262 BCM_LowBeamSts 0 "OFF" 1 "ON" 2 "Fault (Reserved)" 3 "Signal Invalid" ;
VAL_ 262 BCM_RearFogLmpSts 0 "OFF" 1 "ON" 2 "Fault (Reserved)" 3 "Signal Invalid" ;
VAL_ 262 BCM_FrntFogLmpSts 0 "OFF" 1 "ON" 2 "Fault (Reserved)" 3 "Signal Invalid" ;
VAL_ 262 BCM_PosLmpSts 0 "OFF" 1 "ON" 2 "Fault (Reserved)" 3 "Signal Invalid" ;
VAL_ 262 BCM_BackGrdCl58Sts 0 "OFF" 1 "ON" 2 "Fault (Reserved)" 3 "Signal Invalid" ;
VAL_ 262 BCM_HornSts 0 "OFF" 1 "ON" 2 "Fault (Reserved)" 3 "Signal Invalid" ;
VAL_ 262 BCM_TurnIndicatorSts 0 "OFF" 1 "Left On" 2 "Right On" 3 "Left and Right On" ;
VAL_ 263 STAT_CDL_LED 0 "OFF" 1 "ON" 2 "blinking" 3 "Signal invalid" ;
VAL_ 263 STAT_DoorUnlockFL 0 "Locked" 1 "Unlocked" 2 "Reserved" 3 "Signal invalid" ;
VAL_ 263 STAT_ATWS 0 "Secured" 1 "Unsecured" 2 "Alarm" 3 "Partly secured" 4 "Reserved" 5 "Reserved" 6 "Reserved" 7 "Signal invalid" ;
VAL_ 263 BCM_CentralLockSwSts 0 "OFF" 1 "ON" ;
VAL_ 263 STAT_DoorLockFL 0 "Unlocked" 1 "Locked" 2 "Reserved" 3 "Signal invalid" ;
VAL_ 265 BCM_STAT_BrakeSwitch 0 "Brake not pressed" 1 "Brake Pressed" 2 "Reserved" 3 "Signal invalid" ;
VAL_ 265 BCM_STAT_HazardWarn 0 "Not active" 1 "Active" 2 "Reserved" 3 "Signal invalid" ;
VAL_ 265 BCM_STAT_FuelPumpCutOFF 0 "Not active" 1 "Active" 2 "Reserved" 3 "Signal invalid" ;
VAL_ 265 BCM_FollowMeHomeActive 0 "Not Active" 1 "Active" 2 "Reserved" 3 "Signal Invalid" ;
VAL_ 265 BCM_STAT_Horn 0 "OFF" 1 "ON" 2 "Reserved" 3 "Signal invalid" ;
VAL_ 265 BCM_STAT_Autowiping 0 "OFF" 1 "ON" 2 "Reserved" 3 "Signal invalid" ;
VAL_ 265 BCM_TurnIndicator 0 "OFF" 1 "Left" 2 "Right" ;
VAL_ 265 BCM_WelcomeActive 0 "Not Active" 1 "Active" 2 "Reserved" 3 "Signal Invalid" ;
VAL_ 265 BCM_HighBeam 0 "OFF" 1 "High Beam" 2 "Flash high Beam" 3 "Fault" ;
VAL_ 265 ACM_Seat_Belt_Status_3rd_Row_Pas 0 "Not_buckled" 1 "Buckled" 2 "Not_Available" 3 "Failure" ;
VAL_ 265 ACM_Seat_Belt_Status_3rd_Row_Dri 0 "Not_buckled" 1 "Buckled" 2 "Not_Available" 3 "Failure" ;
VAL_ 265 BCM_AlcoholockSwitch 0 "Not active" 1 "Active" 2 "Reserved" 3 "Signal invalid" ;
VAL_ 266 LV_BatteryType 0 "Lead Acid Battery" 1 "Lithium Battery" 2 "Reversed" 3 "Invalid" ;
VAL_ 267 TrailerInput 0 "Trailer synchronous with CAN" 1 "Trailer synchronous with HW input" 2 "Reserved" 3 "Invalid" ;
VAL_ 267 TrailerSystemError 0 "No error" 1 "Error" 2 "Reserved" 3 "Invalid" ;
VAL_ 267 TRM_VoltageStatus 0 "No failure" 1 "Overvoltage" 2 "Undervoltage" 3 "Invalid" ;
VAL_ 267 TRM_STAT_BrakeLight 0 "OFF" 1 "ON" 2 "Reserved" 3 "Signal invalid" ;
VAL_ 267 TRM_STAT_FogLampRear 0 "OFF" 1 "ON" 2 "Failure" 3 "Signal invalid" ;
VAL_ 267 TRM_STAT_PositionLight 0 "PositionLight OFF" 1 "PositionLight ON" 2 "PositionLight failure" 3 "Signal invalid" ;
VAL_ 267 TRM_STAT_TurnIndicators 0 "OFF" 1 "Left turn lamp ON" 2 "Right turn lamp ON" 3 "Both turn lamps ON" 4 "Left turn lamp defect" 5 "Right turn lamp defect" 6 "Both turn lamp defect" 15 "Signal invalid" ;
VAL_ 267 TRM_STAT_ReverseLight 0 "OFF" 1 "ON" 2 "Reserved" 3 "Signal invalid" ;
VAL_ 267 TRM_STAT_HWBrakeLightInput 0 "Brakel Light Input not active TRM" 1 "Brakel Light Input  active TRM" 2 "Reserved" 3 "Signal invalid" ;
VAL_ 267 TRM_STAT_HWIndicatorInput 0 "Indicator Input not active TRM" 1 "Indicator Input active TRM" 2 "Reserved" 3 "Signal invalid" ;
VAL_ 267 TRM_STAT_HWPosLightInput 0 "PosLight nput not active TRM" 1 "PosLight input active TRM" 2 "Reserved" 3 "Signal invalid" ;
VAL_ 268 BCM_TboxAuthStatus 0 "Have not learn. Not allow action" 1 "PASSED" 2 "FALIED: Authentication fail" 3 "Invalid" ;
VAL_ 269 MHU_APM_ReqWindow 0 "No action" 1 "Closed(Top)" 2 "Open Bottom" ;
VAL_ 269 MHU_BCM_RemoteDoorCtrl 0 "Lock" 1 "Unlock" 2 "No action" 3 "Signal invalid" ;
VAL_ 269 MHU_BCM_reqTrunk 0 "Close" 1 "Open" 2 "No action" 3 "Signal invalid" ;
VAL_ 269 MHU_BCM_reqFrunk 0 "No action" 1 "Unlock" 2 "Reserved" 3 "Signal invalid" ;
VAL_ 269 MHU_BCM_ReqSunroof 0 "Closed" 127 "Vent" 150 "Stop" 255 "No Request" ;
VAL_ 270 GlobalWindowReq 0 "Global stop request" 1 "Global closing request via remote control" 2 "Global open request" 3 "Global closing request via CL Switch" 4 "Global closing request via DD Switch" 5 "Global closing request via C-App" 6 "Global Slightly Open request via C-App" 7 "Not Defined" ;
VAL_ 270 RemoteAccessKey 0 "No command" 1 "Lock" 2 "Unlock" 3 "Tailgate unlock long press" 4 "Tailgate unlock" 5 "Long press lock" 6 "Long press unlock" 7 "Panic alarm long press" 8 "Panic alarm press" 9 "Tailgate unlock double press" 15 "Invalid" ;
VAL_ 270 PassiveAccessTrunk 0 "Not pressed" 1 "Pressed" 2 "Reserved" 3 "Signal invalid" ;
VAL_ 270 ComfortOpen 0 "Not active" 1 "Active" 2 "Reserved" 3 "Signal invalid" ;
VAL_ 270 PassiveAccessDoor 0 "Not pressed" 1 "Pressed" 2 "PE switch long press" 3 "Extended Long Press" ;
VAL_ 270 FksOpen 0 "OFF" 1 "ON" 2 "Reserved" 3 "Signal invalid" ;
VAL_ 271 MHU_SetHornOnOff 0 "OFF" 1 "ON" 2 "No action" 3 "Invalid" ;
VAL_ 271 MHU_SetLowBeam 0 "OFF" 1 "ON" 2 "No action" 3 "Invalid" ;
VAL_ 271 MHU_SetHighBeam 0 "OFF" 1 "ON" 2 "No action" 3 "Invalid" ;
VAL_ 273 BCM_Rear_Wiper_Park_Pos_Status 0 "Rear wiper not in Parking position" 1 "Rear wiper in Parking position" ;
VAL_ 273 BCM_Front_Wiper_Park_Pos_Status 0 "Front wiper not in Parking position" 1 "Front wiper in Parking position" ;
VAL_ 273 BCM_Rear_Wash_Status 0 "RearWash OFF" 1 "Rear Wash ON" ;
VAL_ 273 BCM_Front_Wash_Status 0 "FrontWash OFF" 1 "Front Wash ON" ;
VAL_ 274 STAT_TransportMode 0 "OFF" 1 "ON" 2 "Reserved" 3 "Reserved";
VAL_ 274 RemoteFunctionState 0 "Normal function" 1 "Remote function" 2 "Reserved" 3 "Signal Invalid" ;
VAL_ 274 STAT_BLS 0 "BLS not pressed" 1 "BLS pressed" 2 "Reserved" 3 "Signal invalid" ;
VAL_ 274 STAT_CL_50_L 0 "OFF" 1 "ON" 2 "Failure" 3 "Signal invalid" ;
VAL_ 274 Clamp50AdviceRemoteStart 0 "Engine Start announcement not active" 1 "Engine Start announcement active" 2 "Reserved" 3 "Invalid" ;
VAL_ 274 Clamp50AdviceESS 0 "Engine Start announcement not active" 1 "Engine Start announcement active" 2 "Reserved" 3 "Invalid" ;
VAL_ 274 STAT_CL_R_L 0 "OFF" 1 "ON" 2 "Failure" 3 "Signal invalid" ;
VAL_ 274 STAT_CL_15_1_L 0 "OFF" 1 "ON" 2 "Failure" 3 "Signal invalid" ;
VAL_ 274 STAT_CL_15_1_DME_L 0 "OFF" 1 "ON" 2 "Failure" 3 "Signal invalid" ;
VAL_ 274 FobId 0 "Key not available" 1 "FOB_1" 2 "FOB_2" 3 "Signal invalid" ;
VAL_ 274 STAT_Terminal 0 "OFF(Comfort Enable)" 1 "ACC (Park)" 2 "ON (Driver Present)" 3 "Engine start (eMotor running)" 4 "SW Update OTA" 5 "Reserved" 6 "Reserved" 7 "Signal Invalid" ;
VAL_ 274 STAT_CL30_C_BEV 0 "OFF" 1 "ON" 2 "Failure" 3 "Signal invalid" ;
VAL_ 274 BCM_Clamp_Transport 0 "Transport Disabled" 1 "Transport E-Motor Running" 2 "Transport Driver Present" 3 "Ttransport ACC" 4 "Transport OFF" 5 "Init" 6 "Reserved " 7 "Reserved " ;
VAL_ 276 LV_ErrorSts 0 "None" 1 "BMS Warning" 2 "BMS temporarily fault" 3 "BMS permanent fault" 4 "Reserved" 5 "Reserved" 6 "Reserved" 7 "Invalid" ;
VAL_ 276 LV_Discharger_Err 0 "Normal" 1 "Error" ;
VAL_ 276 LV_Discharger_Sts 0 "Open" 1 "Close" ;
VAL_ 276 LV_Charger_Err 0 "Normal" 1 "Error" ;
VAL_ 276 LV_Charger_Sts 0 "Open" 1 "Close" ;
VAL_ 276 LV_OverVoltage 0 "No" 1 "Yes" ;
VAL_ 276 LV_UnderVoltage 0 "No" 1 "Yes" ;
VAL_ 276 LV_OverCurrent 0 "No" 1 "Yes" ;
VAL_ 276 LV_UnderTemp 0 "No" 1 "Yes" ;
VAL_ 276 LV_OverTemp 0 "No" 1 "Yes" ;
VAL_ 276 LV_OverCharge 0 "No" 1 "Yes" ;
VAL_ 276 LV_OverDischarge 0 "No" 1 "Yes" ;
VAL_ 276 LV_CellBalance_Sts 0 "Inactive" 1 "Active" ;
VAL_ 276 LV_CellBalance_Error 0 "Normal" 1 "Error" ;
VAL_ 276 LV_ThermalRunaway 0 "No" 1 "Yes" ;
VAL_ 276 LV_WarmupRequest 0 "Disable" 1 "Enable" 2 "Reserved" 3 "Signal invalid";
VAL_ 277 BCM_ChildLock_Feedback 0 "OFF" 1 "ON" 2 "Reserved" 3 "Signal Invalid" ;
VAL_ 278 LV_WakeupReason 0 "None" 1 "Low SOC Wakeup" 2 "Low Temp Wakeup" 3 "High discharge current wakeup" 4 "High charge current wakeup" 5 "Reserve" 6 "Reserve" 7 "Invalid" ;
VAL_ 280 BCM_DrvInhibitStsFbk 0 "No effect" 1 "Inhibited" 2 "UnInhibited" 3 "Signal Invalid" ;
VAL_ 282 MHU_SET_WiperServicePositionMod 0 "OFF" 1 "ON" 2 "Reserved" 3 "Signal Invalid" ;
VAL_ 282 MHU_Read_KeyFobOnCenterConsole 0 "No Request" 1 "Req Read Keyfob on CenterConsol" 2 "Reserved" 3 "Signal Invalid" ;
VAL_ 283 TBOX_STAT_TerminalReq 0 "OFF(Comfort Enable)" 1 "ACC (Park)" 2 "ON (Driver Present)" 3 "ON (eMotor Running)" 4 "OTA" 5 "Reserved" 6 "No action" 7 "Signal invalid" ;
VAL_ 284 TBOX_FOTA_STAT_TerminalReq 0 "OFF(Comfort Enable)" 1 "ACC(Park)" 2 "ON (Driver Present)" 3 "FOTA" 4 "Reserved" 5 "Reserved" 6 "No action" 7 "Signal Invalid" ;
VAL_ 285 CCU_FanSpeed_Rear 0 "Off" 1 "Level 1" 2 "Level 2" 3 "Level 3" 4 "Level 4" 5 "Level 5" 6 "Level 6" 7 "Reserved" 8 "Reserved" 9 "Reserved" 10 "Reserved" 11 "Reserved" 12 "Reserved" 13 "Reserved" 14 "Reserved" 15 "Signal Invalid" ;
VAL_ 287 MHU_DrvInhibitSts 0 "No effect" 1 "Inhibited" 2 "UnInhibited" 3 "Signal Invalid" ;
VAL_ 290 CCU_REQ_MaxCool 0 "OFF" 1 "ON" 2 "Reserved" 3 "Signal invalid" ;
VAL_ 290 CCU_REQ_MaxHeat 0 "OFF" 1 "ON" 2 "Reserved" 3 "Signal invalid" ;
VAL_ 290 CCU_REQ_ESSMotorControl 0 "No action" 1 "inhibit motor stop" 2 "request motor start" 3 "Reserved" 4 "Reserved" 5 "Reserved" 6 "Reserved" 7 "Signal invalid" ;
VAL_ 295 ADAS_ELKA_ON_feed 0 "ELKA_OFF" 1 "ELKA_ON" ;
VAL_ 295 ADAS_Mode1_status 0 "Off Mode" 1 "Mode1_standby" 2 "Mode1_active" 3 "Mode1_Passive";
VAL_ 295 ADAS_LA_sens_Feed 0 "Early" 1 "Normal" 2 "Late" 3 "Reserved";
VAL_ 295 ADAS_LDW_check 0 "Available" 1 "Temporary fault" 2 "Permanent fault" 3 "Reserved" ;
VAL_ 295 ADAS_LKA_check 0 "Available" 1 "Temporary fault" 2 "Permanent fault" 3 "Reserved" ;
VAL_ 295 ADAS_LA_Mode_Feed 0 "OFF" 1 "Warning only" 2 "Warning and Steer" 3 "ELK" 4 "Signal Invalid";
VAL_ 296 ADAS_IA_check 0 "Available" 1 "Temporary not available" 2 "Permanently not available";
VAL_ 296 ADAS_IA_Left_warning 0 "No Warning" 1 "warning stage-1" 2 "warning stage-2" 3 "warning stage-3";
VAL_ 296 ADAS_RCTA_IndLeft 0 "Indicator output off" 1 "Indicator On(warning stage - 1)" 2 "Indicator flashing(warning stage - 2)" 3 "Reserved";
VAL_ 296 ADAS_RCTA_IndRight 0 "Indicator output off" 1 "Indicator On(warning stage - 1)" 2 "Indicator flashing(warning stage - 2)" 3 "Reserved";
VAL_ 296 ADAS_FCW_state 0 "OFF State" 1 "Stand by state" 2 "Active state" 3 "reserve";
VAL_ 296 ADAS_IA_state 0 "OFF state" 1 "Stand by state" 2 "Active State" 3 "reserve";
VAL_ 296 ADAS_FCW_check 0 "Available" 1 "Temporarily not available" 2 "Permanently not available";
VAL_ 296 ADAS_IA_Right_warning 0 "No Warning" 1 "warning stage-1" 2 "warning stage-2" 3 "warning stage-3";
VAL_ 296 ADAS_IA_Mode_Feed 0 "Off" 1 "ON";
VAL_ 296 ADAS_FCW_warning 0 "No Warning" 1 "warning stage-1" 2 "warning stage-2" 3 "warning stage-3";
VAL_ 303 ST_KL 0 "Init" 1 "Reserved" 2 "KL30" 3 "Reserved" 4 "Reserved" 5 "Reserved" 6 "KL30B-ON" 7 "KL30C-ON (BEV Only)" 8 "KLR-ON" 9 "KL15-change" 10 "KL15-ON" 11 "KL50-delay (ICE only)" 12 "KL50-Change(ICE only)" 13 "KL50-ON (ICE only)" 14 "Reserved" 15 "Signal invalid" ;
VAL_ 303 ST_KL_KEY_VLD 0 "Init" 1 "Key invalid" 2 "Key search activ" 3 "Key valid AR" 4 "Key valid IR" 5 "Key 10sec delay" 6 "Reserved" 7 "Reserved" 8 "Reserved" 9 "Reserved" 10 "Reserved" 11 "Reserved" 12 "Reserved" 13 "Reserved" 14 "Error" 15 "Signal invalid" ;
VAL_ 303 STAT_AlcoholEngineStatus 0 "OFF" 1 "ON" 2 "Reserved" 3 "Signal invalid" ;
VAL_ 303 ST_STCD_PENG 0 "Startcondition traction not fulfilled" 1 "Startcondition traction fulfilled" 2 "Startcondition traction  implausible fulfilled" 3 "Signal invalid" ;
VAL_ 303 ST_SSB 0 "SSB not pressed" 1 "SSB pressed" 2 "Reserve" 3 "Signal invalid" ;
VAL_ 303 RWDT_BLS 0 "BLTS and BLS not applied" 1 "BLS applied" 2 "BLTS  applied" 3 "BLTS and BLS  valid applied" 4 "Reserved" 5 "Reserved" 6 "Reserved" 7 "Error (Invalid signal from BLTS or BLS)" 8 "Init" 15 "Signal invalid" ;
VAL_ 303 RQ_DRVG_RDI 0 "No action" 1 "Engine start advice" 2 "Reserved" 3 "Signal invalid" ;
VAL_ 303 STAT_AlcoholIgnStatus 0 "OFF" 1 "ON" 2 "Reserved" 3 "Signal invalid" ;
VAL_ 303 CTR_ENG_STOP 0 "Init" 1 "Default" 2 "Motor_Off" 3 "Signal invalid" ;
VAL_ 303 ST_VEH_CON 0 "Initial (VSM_STM_STATE_INIT)" 1 "Standby, driver absent (VSM_STM_STATE_STANDBY)" 2 "Basis operation, driver present (VSM_STM_STATE_BASICOP)" 3 "Basis operation, vehicle coasting (VSM_STM_STATE_BASICOP_ROLL)" 4 "Engine postrun (VSM_STM_STATE_15OFF_DRIVE)" 5 "Ignition On (VSM_STM_STATE_IGNITION)" 6 "Ignition On, vehicle coasting (VSM_STM_STATE_IGNITION_ROLL)" 7 "Engine On, vehicle not coasting (VSM_STM_STATE_ENG_IDLE)" 8 "Driving (VSM_STM_STATE_DRIVE)" 9 "Impending start of engine (VSM_STM_STATE_ENG_START_PRE)" 10 "Impending start of engine, vehicle coasting (VSM_STM_STATE_ENG_START_PRE_ROLL)" 11 "Start engine (VSM_STM_STATE_ENG_START)" 12 "Start engine, vehicle coasting (VSM_STM_STATE_ENG_START_ROLL)" 13 "Car wash operation (VSM_STM_STATE_WASH)" 14 "Error (VSM_STM_STATE_ERROR)" 15 "Signal invalid" ;
VAL_ 306 Rolling_Counter_0x132 15 "Invalid" ;
VAL_ 306 SRR_BSD_AudChime_Feed 0 "Off" 1 "On" 2 "Reserved" 3 "signal invalid" ;
VAL_ 306 SRR_BSD_check 0 "Available" 1 "Temporarily not available" 2 "Permanently not available" 3 "signal invalid" ;
VAL_ 306 SRR_BSD_state 0 "OFF State" 1 "Stand by state" 2 "Armed state" 3 "Warning" ;
VAL_ 306 SRR_BSD_IndLeft 0 "Indicator output off" 1 "Indicator On(warning stage - 1)" 2 "Indicator flashing(warning stage - 2)" 3 "Sensor Fault" ;
VAL_ 306 SRR_BSD_IndRight 0 "Indicator output off" 1 "Indicator On(warning stage - 1)" 2 "Indicator flashing(warning stage - 2)" 3 "Sensor Fault" ;
VAL_ 306 SRR_BSD_SndWarn 0 "Sound Warning disable" 1 "Sound Warning enable" ;
VAL_ 306 SRR_BSD_Mode_Feed 0 "Off" 1 "On" 2 "Reserved" 3 "signal invalid" ;
VAL_ 307 ADAS_BSD_IndLeft 0 "Indicator output off" 1 "Indicator On(warning stage - 1)" 2 "Indicator flashing(warning stage - 2)" 3 "Sensor Fault" ;
VAL_ 307 ADAS_BSD_IndRight 0 "Indicator output off" 1 "Indicator On(warning stage - 1)" 2 "Indicator flashing(warning stage - 2)" 3 "Sensor Fault" ;
VAL_ 314 FCAM_ESA_Sts 0 "FctaOn1_StrtUpOn (Not_enabled)" 1 "FctaOn1_On (Active)" 2 "FctaOn1_Off (Inactive)" 3 "FctaOn1_Error (Denied)" ;
VAL_ 359 TWV1_St_Feedback 0 "Over Voltage" 1 "Under Voltage" 2 "OverTemp_Warning" 3 "OverTemp_ShutDown" 4 "Over Current" 5 "Stall" 6 "OpenLoad" 7 "Communication_Error" 8 "WTREST" 9 "POR" 10 "SensorOVR" 11 "Reserved" 12 "Reserved" 13 "Reserved" 14 "Reserved" 15 "TrgPosDone" ;
VAL_ 359 TWV1_Frm_Error 0 "Normal" 1 "Error" ;
VAL_ 360 MHU_AVM_ShowAVMReq 0 "No Request" 1 "Hide" 2 "Show";
VAL_ 376 YSS_LONG_ACCUNFILTERED_QUAL 2 "VALID" 4 "SUBSITUTE" 6 "IN VALID" 14 "NOT AVAILABLE" 15 "UNFILLED" ;
VAL_ 376 YSS_LONG_ACC_QUAL 2 "VALID" 4 "SUBSITUTE" 6 "IN VALID" 14 "NOT AVAILABLE" 15 "UNFILLED" ;
VAL_ 381 YSS_YAW_RATEUNFILTERED_QUAL 2 "VALID" 4 "SUBSITUTE" 6 "IN VALID" 14 "NOT AVAILABLE" 15 "UNFILLED" ;
VAL_ 381 YSS_YAW_RATE_QUAL 2 "VALID" 4 "SUBSITUTE" 6 "IN VALID" 14 "NOT AVAILABLE" 15 "UNFILLED" ;
VAL_ 381 YSS_SC_STATUS 0 "No Mistake" 2 "Under Voltage" 3 "Over Voltage" 13 "Function Not Available" 14 "Function Error" 15 "Un-Filled" ;
VAL_ 382 SAS_SASStsSnsr 0 "sensor value  Invalid" 1 "sensor value  valid" ;
VAL_ 382 SAS_SteerWhlRotSpdStatus 0 "Invalid" 1 "Valid" ;
VAL_ 382 SAS_SASFailure 0 "Failure" 1 "No Failure" ;
VAL_ 382 SAS_Calibrated 0 "Not Calibrated" 1 "Calibrated" ;
VAL_ 382 SAS_SteerWheelAngleValid 0 "Valid" 1 "Invalid" ;
VAL_ 385 CAM_CamSts 0 "Not Available for ADB" 1 "Available for ADB" 2 "Camera Fault" 3 "reserved" ;
VAL_ 385 CAM_AmbLi 0 "Not Active for HighBeam (Day)" 1 "Active for Highbeam (Night)" ;
VAL_ 385 CAM_RoadIllmn 0 "Road illumination Not Detected" 1 "Road illumination Detected" ;
VAL_ 385 CAM_Obj_TrfcStyle 0 "Unknown" 1 "Right Hand Traffic" 2 "Left Hand Traffic" 3 "Not Available" ;
VAL_ 388 FCAM_BCM_IndicatorlightReq 0 "No request" 1 "Left" 2 "Right" 3 "Hazard" 4 "Turn Indicator Off" ;
VAL_ 401 CAM_Obj1_Valid 0 "Invalid" 1 "Valid" ;
VAL_ 401 CAM_Obj1_Typ 0 "Unknown" 1 "Oncoming Object" 2 "Preceding Object" 3 "Reflective Object " ;
VAL_ 404 CAM_Obj2_Valid 0 "Invalid" 1 "Valid" ;
VAL_ 404 CAM_Obj2_Typ 0 "Unknown" 1 "Oncoming Object" 2 "Preceding Object" 3 "Reflective Object " ;
VAL_ 406 CAM_Obj3_Valid 0 "Invalid" 1 "Valid" ;
VAL_ 406 CAM_Obj3_Typ 0 "Unknown" 1 "Oncoming Object" 2 "Preceding Object" 3 "Reflective Object " ;
VAL_ 410 CAM_Obj4_Valid 0 "Invalid" 1 "Valid" ;
VAL_ 410 CAM_Obj4_Typ 0 "Unknown" 1 "Oncoming Object" 2 "Preceding Object" 3 "Reflective Object " ;
VAL_ 412 CAM_Obj5_Valid 0 "Invalid" 1 "Valid" ;
VAL_ 412 CAM_Obj5_Typ 0 "Unknown" 1 "Oncoming Object" 2 "Preceding Object" 3 "Reflective Object " ;
VAL_ 413 CAM_Obj6_Valid 0 "Invalid" 1 "Valid" ;
VAL_ 413 CAM_Obj6_Typ 0 "Unknown" 1 "Oncoming Object" 2 "Preceding Object" 3 "Reflective Object " ;
VAL_ 414 CAM_Obj7_Valid 0 "Invalid" 1 "Valid" ;
VAL_ 414 CAM_Obj7_Typ 0 "Unknown" 1 "Oncoming Object" 2 "Preceding Object" 3 "Reflective Object " ;
VAL_ 415 CAM_Obj8_Valid 0 "Invalid" 1 "Valid" ;
VAL_ 415 CAM_Obj8_Typ 0 "Unknown" 1 "Oncoming Object" 2 "Preceding Object" 3 "Reflective Object " ;
VAL_ 417 DVCO_VEH 0 "Vehicle is stationary" 1 "Vehicle is moving forward" 2 "Vehicle is reversing" 3 "Vehicle is moving " 4 "Vehicle is stationary rear axle rol" 5 "Vehicle is stationary all axle roll" 6 "Vehicle is stationary Front axle roll" 7 "Signal invalid" ;
VAL_ 417 QU_V_VEH_COG 1 "Signal value is valid and secured and plausible" 2 "Reserved" 3 "Reserved" 4 "Reserved" 6 "Reserved" 7 "Reserved" 8 "Init" 9 "Reserved" 10 "Signal value is valid" 11 "Signal quality or monitoring limited" 12 "Reserved" 14 "Signal value is invalid" 15 "Signal invalid" ;
VAL_ 504 EDS_Work_STS_FR 0 "default" 1 "init" 2 "standby" 3 "precharge" 4 "normal" 5 "HVReady" 6 "6SO" 11 "shut down" 12 "after run" 13 "Failure" 14 "power off" 15 "invaild" ;
VAL_ 504 EDS_output_trqValid_FR 0 "invalid" 1 "valid" ;
VAL_ 504 EDS_MotorDriveSts_FR 0 "Zero control" 1 "Drive control" 2 "regen control" 3 "Invaild" ;
VAL_ 504 EDS_powoff_req_FR 0 "(No request)" 1 "(Request high voltage power down)" ;
VAL_ 504 EDS_SpdValid_FR 0 "invalid" 1 "valid" ;
VAL_ 504 EDS_VCU_6SO_flag_FWD 0 "OFF" 1 "ON" ;
VAL_ 505 EDS_Work_STS_RR 0 "default" 1 "init" 2 "standby" 3 "precharge" 4 "normal" 5 "HVReady" 6 "6SO" 11 "shut down" 12 "after run" 13 "Failure" 14 "power off" 15 "invaild" ;
VAL_ 505 EDS_output_trqValid_RR 0 "invalid" 1 "valid" ;
VAL_ 505 EDS_MotorDriveSts_RR 0 "Zero control" 1 "Drive control" 2 "regen control" 3 "Invaild" ;
VAL_ 505 EDS_powoff_req_RR 0 "(No request)" 1 "(Request high voltage power down)" ;
VAL_ 505 EDS_SpdValid_RR 0 "invalid" 1 "valid" ;
VAL_ 505 EDS_VCU_6SO_flag_RWD 0 "OFF" 1 "ON" ;
VAL_ 518 ADAS_ELK_check 0 "Available" 1 "Fault" 2 "Automatic deactivation" 3 "OFF-Manual Deactivation" ;
VAL_ 518 ADAS_HWA_state 0 "Off" 1 "Stand_by" 2 "Active" 3 "Override" 4 "Passive" 5 "Active_suspend" 6 "Fault" ;
VAL_ 518 ADAS_Mode2_status 0 "Off Mode" 1 "Mode2_Standby" 2 "Mode2_Active" 3 "Mode2_Passive" ;
VAL_ 518 ADAS_ALC_state 0 "Off" 1 "Stand_by" 2 "Active" 3 "Override" 4 "Passive" 5 "Active_suspend" 6 "Fault" ;
VAL_ 518 ADAS_ALC_Mode_feed 0 "OFF" 1 "ON" 2 "Reserved" 3 "Reserved";
VAL_ 519 SR_Undervoltage_Fault_Sts 0 "Normal" 1 "Fault" ;
VAL_ 519 SR_Overvoltage_Fault_Sts 0 "Normal" 1 "Fault" ;
VAL_ 519 SR_SLEEP_RQ 0 "Sleep Not Ready" 1 "Ready to Sleep" ;
VAL_ 519 SR_Position 0 "Unknown -Default" 1 "All Closed" 2 "All Closed To Tilt" 3 "Tilt" 4 "Tilt to Half Open" 5 "Half Open" 6 "Half Open to Open" 7 "ALL Open" ;
VAL_ 519 SR_Motor_Running_Sts 0 "Stop" 1 "Open Direction" 2 "Close Direction" 3 "Not Used" ;
VAL_ 519 SR_MotorReverse_Fault_Sts 0 "Normal" 1 "Fault" ;
VAL_ 519 SR_Hall_Fault_Sts 0 "Normal" 1 "Fault" ;
VAL_ 519 SR_Normalisation_Sts 0 "Normalised" 1 "Not normalised" ;
VAL_ 519 SR_Relay_Fault 0 "Normal" 1 "Fault" ;
VAL_ 519 SR_Commu_Fault_Sts 0 "Normal" 1 "Fault" ;
VAL_ 519 SR_Initialisation_Status 0 "Initialised" 1 "Not initialised" ;
VAL_ 519 SR_Ctrl_Result 0 "No Response" 1 "Running" 2 "Succeed" 3 "Failed" ;
VAL_ 519 SR_ThermalProtection_Fault_Sts 0 "Normal" 1 "Fault" ;
VAL_ 519 SR_Posit_Percentage 127 "Invalid" ;
VAL_ 519 SR_Operation_Stat 0 "Idle/Not pressed" 1 "Manual Slide Open" 2 "Manual Slide Closed" 3 "ManualTilt Open" 4 "Manual Tilt Closed" 5 "Auto Slide Open" 6 "Auto Slide Closed" 7 "Auto Tilt Open" 8 "Auto Tilt Closed" ;
VAL_ 519 SR_Error_RSP 0 "No Error" 1 "Error" ;
VAL_ 519 BCM_AutoSunroof_Sts 0 "OFF" 1 "Glass Only" 2 "Glass & Shade" 3 "Signal invalid";
VAL_ 520 SS_MotorReverse_Fault_Status 0 "Normal" 1 "Fault" ;
VAL_ 520 SS_Motor_Running_Status 0 "Stop" 1 "Open direction" 2 "Close direction" 3 "Not Used" ;
VAL_ 520 SS_Position 0 "Unknown-Default" 1 "All Closed" 2 "All Closed to Ajar" 3 "Ajar" 4 "Ajar to Half Open" 5 "Half Open" 6 "Half Open to Open" 7 "All Open" ;
VAL_ 520 SS_SLEEP_RQ 0 "Sleep Not Ready" 1 "Ready to Sleep" ;
VAL_ 520 SS_Undervoltage_Fault_Status 0 "Normal" 1 "Fault" ;
VAL_ 520 SS_Ctrl_Result 0 "No Response" 1 "Running" 2 "Succeed" 3 "Failed" ;
VAL_ 520 SS_Overvoltage_Fault_Status 0 "Normal" 1 "Fault" ;
VAL_ 520 SS_Relay_Fault 0 "Normal" 1 "Fault" ;
VAL_ 520 SS_Normalisation_Status 0 "Normalised" 1 "Not normalised" ;
VAL_ 520 SS_Hall_Fault_Status 0 "Normal" 1 "Fault" ;
VAL_ 520 SS_Commu_Fault_Status 0 "Normal" 1 "Fault" ;
VAL_ 520 SS_Initialisation_Status 0 "Normal" 1 "Fault" ;
VAL_ 520 SS_Posit_Percentage 127 "Invalid" ;
VAL_ 520 SS_ThermalProtection_Flt_Sts 0 "Normal" 1 "Fault" ;
VAL_ 520 SS_Operation_State 0 "Idle/Not pressed" 1 "Stop" 2 "Tilt Man" 3 "Tilt Auto" 4 "Close Man" 5 "Close Auto" 6 "Open Man" 7 "Open Auto" ;
VAL_ 520 SS_Error_RSP 0 "No Error" 1 "Error" ;
